VERSION "created by canmatrix"

NS_ :

BS_:

BU_: IPD

BO_ 777 RZCU_PTCANFD_100ms_FrP10: 8 Vector__XXX
 SG_ IRZCU_100ms_Group10_CRC : 7|8@0+ (1,0) [0|255] "null" IPD
 SG_ IRZCU_100ms_Group10_RC : 11|4@0+ (1,0) [0|15] "null" IPD
 SG_ IOfbdChrgRelaySts : 13|2@0+ (1,0) [0|3] "null" IPD
 SG_ IRZCU_100ms_Group10_Reserved1 : 15|2@0+ (1,0) [0|3] "null" IPD
 SG_ IOfbdChrgrNgtvSktTem : 23|8@0+ (1,-40) [-40|215] "degreeCelsius" IPD
 SG_ IOnBdChrgrSktPstvSnsrTem : 31|8@0+ (1,-40) [-40|215] "degreeCelsius" IPD
 SG_ IEleccLckCtrlResp : 34|3@0+ (1,0) [0|7] "null" IPD
 SG_ IOnbdChrgrSktEleccLckEnable : 36|2@0+ (1,0) [0|3] "null" IPD
 SG_ IOnBdChrgrSktPstvSnsrTemV : 37|1@0+ (1,0) [0|1] "null" IPD
 SG_ IOfbdChrgrNgtvSktTemV : 38|1@0+ (1,0) [0|1] "null" IPD
 SG_ IOfbdChrgrWkup : 39|1@0+ (1,0) [0|1] "null" IPD
 SG_ IRZCU_100ms_Group10_Reserved2 : 45|7@0+ (1,0) [0|127] "null" IPD
 SG_ IFlbStrgFnStsResp : 47|2@0+ (1,0) [0|3] "null" IPD
 SG_ IRZCU_100ms_Group10_Reserved3 : 48|3@0+ (1,0) [0|7] "null" IPD
 SG_ IOfbdRelayWeldFlt : 49|1@0+ (1,0) [0|1] "null" IPD
 SG_ IIMU_Signal_status : 52|3@0+ (1,0) [0|7] "null" IPD
 SG_ IVCUCtrlS2Req : 54|2@0+ (1,0) [0|3] "null" IPD
 SG_ IOfbdChrgRelayStsV : 56|1@0+ (1,0) [0|1] "null" IPD
 SG_ ICstRgtnBrkLgtReq : 57|1@0+ (1,0) [0|1] "null" IPD
 SG_ ICstRgtnBrkLgtReqV : 58|1@0+ (1,0) [0|1] "null" IPD
 SG_ IOnBdChrgrSktElecLckStaV : 59|1@0+ (1,0) [0|1] "null" IPD
 SG_ IOnBdChrgrSktElecLckSta : 61|2@0+ (1,0) [0|3] "null" IPD

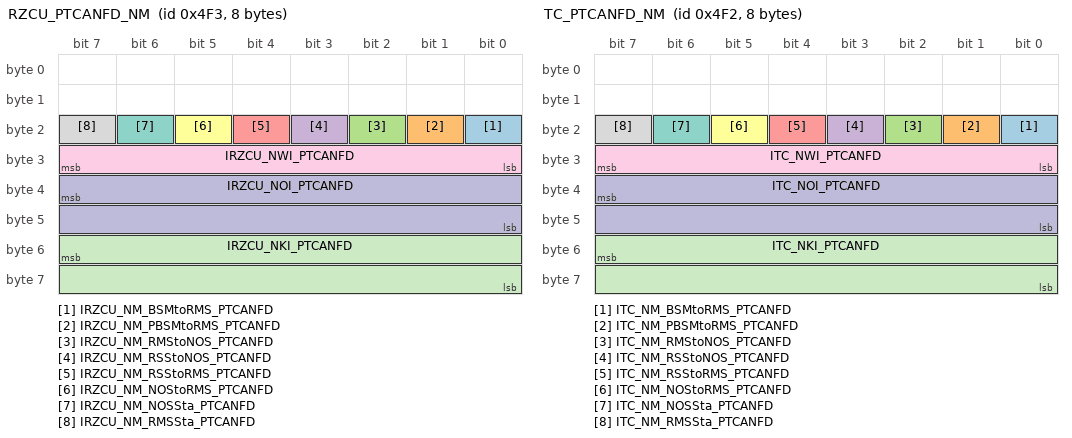
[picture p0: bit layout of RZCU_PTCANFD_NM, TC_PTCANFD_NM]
BO_ 1267 RZCU_PTCANFD_NM: 8 Vector__XXX
 SG_ IRZCU_NM_BSMtoRMS_PTCANFD : 16|1@0+ (1,0) [0|1] "null" Vector__XXX
 SG_ IRZCU_NM_PBSMtoRMS_PTCANFD : 17|1@0+ (1,0) [0|1] "null" Vector__XXX
 SG_ IRZCU_NM_RMStoNOS_PTCANFD : 18|1@0+ (1,0) [0|1] "null" Vector__XXX
 SG_ IRZCU_NM_RSStoNOS_PTCANFD : 19|1@0+ (1,0) [0|1] "null" Vector__XXX
 SG_ IRZCU_NM_RSStoRMS_PTCANFD : 20|1@0+ (1,0) [0|1] "null" Vector__XXX
 SG_ IRZCU_NM_NOStoRMS_PTCANFD : 21|1@0+ (1,0) [0|1] "null" Vector__XXX
 SG_ IRZCU_NM_NOSSta_PTCANFD : 22|1@0+ (1,0) [0|1] "null" Vector__XXX
 SG_ IRZCU_NM_RMSSta_PTCANFD : 23|1@0+ (1,0) [0|1] "null" Vector__XXX
 SG_ IRZCU_NWI_PTCANFD : 31|8@0+ (1,0) [0|255] "null" Vector__XXX
 SG_ IRZCU_NOI_PTCANFD : 39|16@0+ (1,0) [0|65535] "null" Vector__XXX
 SG_ IRZCU_NKI_PTCANFD : 55|16@0+ (1,0) [0|65535] "null" Vector__XXX

BO_ 247 RZCU_RZCUCANFD_10ms_FrP22_NoSecO: 12 Vector__XXX
 SG_ IRZCU_10ms_Group22_CRC : 7|8@0+ (1,0) [0|255] "null" IPD
 SG_ IRZCU_10ms_Group22_RC : 11|4@0+ (1,0) [0|15] "null" IPD
 SG_ IRZCU_10ms_Group22_Reserved1 : 13|2@0+ (1,0) [0|3] "null" IPD
 SG_ IEPTTrOtptShaftTotMinAvlblToqV : 14|1@0+ (1,0) [0|1] "null" IPD
 SG_ IEPTTrOtptShaftTotMaxAvlblToqV : 15|1@0+ (1,0) [0|1] "null" IPD
 SG_ IEPTTrOtptShaftTotMaxAvlblToq : 23|12@0+ (0.5,-848) [-848|1199.5] "Nm" IPD
 SG_ IEPTTrOtptShaftTotMinAvlblToq : 27|12@0+ (0.5,-848) [-848|1199.5] "Nm" IPD
 SG_ IEPTTrOtptShaftTotToq : 43|12@0+ (0.5,-848) [-848|1199.5] "Nm" IPD
 SG_ IEPTTrOtptShaftTotToqV : 44|1@0+ (1,0) [0|1] "null" IPD
 SG_ IRZCU_10ms_Group22_Reserved2 : 47|3@0+ (1,0) [0|7] "null" IPD
 SG_ IRZCU_10ms_Group22_Reserved3 : 63|8@0+ (1,0) [0|255] "null" IPD
 SG_ IRZCU_10ms_Group22_Reserved4 : 71|8@0+ (1,0) [0|255] "null" IPD
 SG_ IRZCU_10ms_Group22_Reserved5 : 79|8@0+ (1,0) [0|255] "null" IPD
 SG_ IRZCU_10ms_Group22_Reserved6 : 87|8@0+ (1,0) [0|255] "null" IPD
 SG_ IRZCU_10ms_Group22_Reserved7 : 95|8@0+ (1,0) [0|255] "null" IPD

BO_ 225 RZCU_RZCUCANFD_10ms_FrP23: 16 Vector__XXX
 SG_ IRZCU_10ms_Group23_CRC : 7|8@0+ (1,0) [0|255] "null" IPD
 SG_ IRZCU_10ms_Group23_RC : 11|4@0+ (1,0) [0|15] "null" IPD
 SG_ IRZCU_10ms_Group23_Reserved1 : 15|4@0+ (1,0) [0|15] "null" IPD
 SG_ IRZCU_10ms_Group23_Reserved3 : 18|3@0+ (1,0) [0|7] "null" IPD
 SG_ IAutodDrvngToqReqResp : 21|3@0+ (1,0) [0|7] "null" IPD
 SG_ IRZCU_10ms_Group23_Reserved2 : 23|2@0+ (1,0) [0|3] "null" IPD
 SG_ IRZCU_10ms_Group23_Reserved4 : 28|5@0+ (1,0) [0|31] "null" IPD
 SG_ IPtACCToqReqResp : 31|3@0+ (1,0) [0|7] "null" IPD
 SG_ IAIPilotSysSaBrSts : 35|4@0+ (1,0) [0|15] "null" IPD
 SG_ IAIPilotSysSaBrInh : 39|4@0+ (1,0) [0|15] "null" IPD
 SG_ IRZCU_10ms_Group23_Reserved5 : 47|8@0+ (1,0) [0|255] "null" IPD
 SG_ IRZCU_10ms_Group23_Reserved6 : 54|7@0+ (1,0) [0|127] "null" IPD
 SG_ IAccelOvrd : 55|1@0+ (1,0) [0|1] "null" IPD
 SG_ IRZCU_10ms_Group23_Reserved7 : 63|8@0+ (1,0) [0|255] "null" IPD
 SG_ IRZCU_10ms_Group23_Reserved8 : 71|8@0+ (1,0) [0|255] "null" IPD
 SG_ IRZCU_10ms_Group23_Reserved9 : 79|8@0+ (1,0) [0|255] "null" IPD
 SG_ IRZCU_10ms_Group23_Reserved10 : 87|8@0+ (1,0) [0|255] "null" IPD
 SG_ IRZCU_10ms_Group23_Reserved11 : 95|8@0+ (1,0) [0|255] "null" IPD

BO_ 1266 TC_PTCANFD_NM: 8 Vector__XXX
 SG_ ITC_NM_BSMtoRMS_PTCANFD : 16|1@0+ (1,0) [0|1] "null" Vector__XXX
 SG_ ITC_NM_PBSMtoRMS_PTCANFD : 17|1@0+ (1,0) [0|1] "null" Vector__XXX
 SG_ ITC_NM_RMStoNOS_PTCANFD : 18|1@0+ (1,0) [0|1] "null" Vector__XXX
 SG_ ITC_NM_RSStoNOS_PTCANFD : 19|1@0+ (1,0) [0|1] "null" Vector__XXX
 SG_ ITC_NM_RSStoRMS_PTCANFD : 20|1@0+ (1,0) [0|1] "null" Vector__XXX
 SG_ ITC_NM_NOStoRMS_PTCANFD : 21|1@0+ (1,0) [0|1] "null" Vector__XXX
 SG_ ITC_NM_NOSSta_PTCANFD : 22|1@0+ (1,0) [0|1] "null" Vector__XXX
 SG_ ITC_NM_RMSSta_PTCANFD : 23|1@0+ (1,0) [0|1] "null" Vector__XXX
 SG_ ITC_NWI_PTCANFD : 31|8@0+ (1,0) [0|255] "null" Vector__XXX
 SG_ ITC_NOI_PTCANFD : 39|16@0+ (1,0) [0|65535] "null" Vector__XXX
 SG_ ITC_NKI_PTCANFD : 55|16@0+ (1,0) [0|65535] "null" Vector__XXX

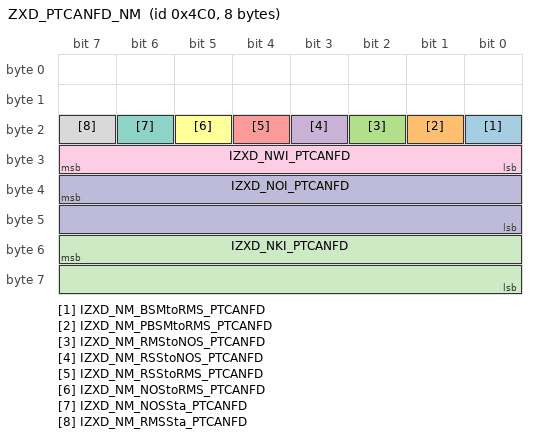
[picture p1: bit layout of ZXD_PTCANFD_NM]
BO_ 1216 ZXD_PTCANFD_NM: 8 Vector__XXX
 SG_ IZXD_NM_BSMtoRMS_PTCANFD : 16|1@0+ (1,0) [0|1] "null" Vector__XXX
 SG_ IZXD_NM_PBSMtoRMS_PTCANFD : 17|1@0+ (1,0) [0|1] "null" Vector__XXX
 SG_ IZXD_NM_RMStoNOS_PTCANFD : 18|1@0+ (1,0) [0|1] "null" Vector__XXX
 SG_ IZXD_NM_RSStoNOS_PTCANFD : 19|1@0+ (1,0) [0|1] "null" Vector__XXX
 SG_ IZXD_NM_RSStoRMS_PTCANFD : 20|1@0+ (1,0) [0|1] "null" Vector__XXX
 SG_ IZXD_NM_NOStoRMS_PTCANFD : 21|1@0+ (1,0) [0|1] "null" Vector__XXX
 SG_ IZXD_NM_NOSSta_PTCANFD : 22|1@0+ (1,0) [0|1] "null" Vector__XXX
 SG_ IZXD_NM_RMSSta_PTCANFD : 23|1@0+ (1,0) [0|1] "null" Vector__XXX
 SG_ IZXD_NWI_PTCANFD : 31|8@0+ (1,0) [0|255] "null" Vector__XXX
 SG_ IZXD_NOI_PTCANFD : 39|16@0+ (1,0) [0|65535] "null" Vector__XXX
 SG_ IZXD_NKI_PTCANFD : 55|16@0+ (1,0) [0|65535] "null" Vector__XXX

BO_ 769 ESS_PTCANFD_100ms_ConFrP19: 64 Vector__XXX
 SG_ Header_ID M : 7|24@0- (1,0) [-8388608|8388607] "" Vector__XXX
 SG_ Header_DLC : 31|8@0- (1,0) [-128|127] "" Vector__XXX
 SG_ IBMSEmsnRltdMalfA m147460 : 36|1@0+ (1,0) [0|1] "null" Vector__XXX
 SG_ IBMSOdoFctV m147460 : 37|1@0+ (1,0) [0|1] "null" Vector__XXX
 SG_ IBMSCdstCtr m147460 : 39|2@0+ (1,0) [0|3] "null" Vector__XXX
 SG_ IBMSOdoFct m147460 : 47|8@0+ (0.5,0) [0|127.5] "Percent" Vector__XXX
 SG_ IBMSStdAvlblEnrg m147460 : 55|12@0+ (0.05,0) [0.00|204.75] "kwh" Vector__XXX
 SG_ IBMSChrgTrgtStdAvlblEnrg m147460 : 59|12@0+ (0.05,0) [0.00|204.75] "kwh" Vector__XXX
 SG_ IBMSDisTrgtStdAvlblEnrg m147460 : 79|12@0+ (0.05,0) [0.00|204.75] "kwh" Vector__XXX
 SG_ IBMSStdAvlblEnrgV m147460 : 81|1@0+ (1,0) [0|1] "null" Vector__XXX
 SG_ IBMSChrgTrgtStdAvlblEnrgV m147460 : 82|1@0+ (1,0) [0|1] "null" Vector__XXX
 SG_ IBMSDisTrgtStdAvlblEnrgV m147460 : 83|1@0+ (1,0) [0|1] "null" Vector__XXX
 SG_ IESS_100ms_Group25_CRC m65796 : 39|8@0+ (1,0) [0|255] "null" Vector__XXX
 SG_ IESS_100ms_Group25_RC m65796 : 43|4@0+ (1,0) [0|15] "null" Vector__XXX
 SG_ IESS_100ms_Group25_Reserved1 m65796 : 47|4@0+ (1,0) [0|15] "null" Vector__XXX
 SG_ IBMSPosPtIsltnRstc m65796 : 53|14@0+ (0.5,0) [0|8191.5] "kOhm" Vector__XXX
 SG_ IBMSPosPtIsltnRstcV m65796 : 54|1@0+ (1,0) [0|1] "null" Vector__XXX
 SG_ IBMSNegPtIsltnRstcV m65796 : 55|1@0+ (1,0) [0|1] "null" Vector__XXX
 SG_ IBMSNegPtIsltnRstc m65796 : 69|14@0+ (0.5,0) [0|8191.5] "kOhm" Vector__XXX
 SG_ IESS_100ms_Group25_Reserved2 m65796 : 71|2@0+ (1,0) [0|3] "null" Vector__XXX
 SG_ IESS_100ms_Group25_Reserved3 m65796 : 87|8@0+ (1,0) [0|255] "null" Vector__XXX
 SG_ IESS_100ms_Group25_Reserved4 m65796 : 95|8@0+ (1,0) [0|255] "null" Vector__XXX
 SG_ IBMSStaOfHealthResi m65794 : 39|8@0+ (0.5,0) [0|127.5] "Percent" Vector__XXX
 SG_ IBMSStaOfHealthCapct m65794 : 47|8@0+ (0.5,0) [0|127.5] "Percent" Vector__XXX
 SG_ IBMSOnbdChrgSpRsn m65794 : 55|8@0+ (1,0) [0|255] "null" Vector__XXX
 SG_ IBMSPackSOH m65794 : 57|10@0+ (0.1,0) [0|102.3] "Percent" Vector__XXX
 SG_ IBMSFltLamp m65794 : 63|4@0+ (1,0) [0|15] "null" Vector__XXX
 SG_ IHVBatShutOff m65794 : 79|1@0+ (1,0) [0|1] "null" Vector__XXX
 SG_ IHVBatSOCHiResV m74579 : 48|1@0+ (1,0) [0|1] "null" Vector__XXX
 SG_ IHVBatSOCMin m74579 : 63|8@0+ (0.392157,0) [0.000000|100.000035] "null" Vector__XXX
 SG_ IHVBatSOCHiRes m74579 : 71|16@0+ (0.00152593,0) [0E-008|100.00182255] "null" Vector__XXX
 SG_ IHVBatSOCTrgtHiRes m74579 : 87|16@0+ (0.001526,0) [0.000000|100.006410] "null" Vector__XXX
 SG_ IESS_100ms_Group58_CRC m74584 : 39|8@0+ (1,0) [0|255] "null" IPD
 SG_ IESS_100ms_Group58_RC m74584 : 43|4@0+ (1,0) [0|15] "null" IPD
 SG_ IBMSOfbdChrgrSktVolV m74584 : 44|1@0+ (1,0) [0|1] "null" IPD
 SG_ IESS_100ms_Group58_Reserved1 m74584 : 45|1@0+ (1,0) [0|1] "null" IPD
 SG_ IBMSOffBdChrgrPlugOn m74584 : 47|2@0+ (1,0) [0|3] "null" IPD
 SG_ IESS_100ms_Group58_Reserved2 m74584 : 55|8@0+ (1,0) [0|255] "null" IPD
 SG_ IESS_100ms_Group58_Reserved3 m74584 : 63|8@0+ (1,0) [0|255] "null" IPD
 SG_ IBMSOfbdChrgrSktVol m74584 : 71|12@0+ (0.25,0) [0.00|1023.75] "null" IPD
 SG_ IESS_100ms_Group58_Reserved4 m74584 : 73|2@0+ (1,0) [0|3] "null" IPD
 SG_ IBMSOffBdChrgrPlugOnV m74584 : 74|1@0+ (1,0) [0|1] "null" IPD
 SG_ IBMSOfbdChrgrWkup m74584 : 75|1@0+ (1,0) [0|1] "null" IPD
 SG_ IESS_100ms_Group58_Reserved5 m74584 : 87|8@0+ (1,0) [0|255] "null" IPD
 SG_ IESS_100ms_Group58_Reserved6 m74584 : 95|8@0+ (1,0) [0|255] "null" IPD

BO_ 548 ESS_PTCANFD_100ms_ConFrP29: 64 Vector__XXX
 SG_ Header_ID M : 7|24@0- (1,0) [-8388608|8388607] "" Vector__XXX
 SG_ Header_DLC : 31|8@0- (1,0) [-128|127] "" Vector__XXX
 SG_ IVehElecRngDspCmd m147459 : 33|2@0+ (1,0) [0|3] "null" Vector__XXX
 SG_ IElecDrvRngPerKwhV m147459 : 34|1@0+ (1,0) [0|1] "null" Vector__XXX
 SG_ IVehElecRngV m147459 : 35|1@0+ (1,0) [0|1] "null" Vector__XXX
 SG_ IElecDrvRngPerKwh m147459 : 39|4@0+ (1,0) [0|15] "mph" Vector__XXX
 SG_ IBMSOfbdChrgrMaxOtptVol m147459 : 47|12@0+ (0.25,0) [0.00|1023.75] "V" Vector__XXX
 SG_ IBMSOfbdChrgrOtptVol m147459 : 50|12@0+ (0.25,0) [0.00|1023.75] "V" Vector__XXX
 SG_ IBMSOfbdChrgrMaxOtptVolV m147459 : 51|1@0+ (1,0) [0|1] "null" Vector__XXX
 SG_ IBMSOfbdChrgrOtptCrnt m147459 : 69|11@0+ (0.5,0) [0|1023.5] "A" Vector__XXX
 SG_ IBMSOfbdChrgrOtptVolV m147459 : 70|1@0+ (1,0) [0|1] "null" Vector__XXX
 SG_ IBMSOfbdChrgngMd m147459 : 73|2@0+ (1,0) [0|3] "null" Vector__XXX
 SG_ IBMSOfbdChrgrOtptCrnV m147459 : 74|1@0+ (1,0) [0|1] "null" Vector__XXX
 SG_ IVehElecRng m147459 : 82|11@0+ (1,0) [0|2047] "km" Vector__XXX
 SG_ IBMSEnbPTC m147459 : 84|1@0+ (1,0) [0|1] "null" Vector__XXX
 SG_ IHVOffMoSts m147459 : 87|3@0+ (1,0) [0|7] "null" Vector__XXX
 SG_ IBMSPTCHeatReqDspCmd m147458 : 33|2@0+ (1,0) [0|3] "null" Vector__XXX
 SG_ IChrgngRmnngTimeV m147458 : 34|1@0+ (1,0) [0|1] "null" Vector__XXX
 SG_ IBMSChrgrPlugCnctnIO m147458 : 35|1@0+ (1,0) [0|1] "null" IPD
 SG_ IBMSCumuDschrgEnrgV m147458 : 38|1@0+ (1,0) [0|1] "null" Vector__XXX
 SG_ IBMSCumuDschrgEnrg m147458 : 47|24@0+ (0.1,0) [0|1677721.5] "kWh" Vector__XXX
 SG_ IChrgngRmnngTime m147458 : 65|10@0+ (1,0) [0|1023] "min" Vector__XXX
 SG_ IBMSEleccLckCtrlDspCmd m147458 : 67|2@0+ (1,0) [0|3] "null" Vector__XXX
 SG_ IBMSPackSOCCorr m147458 : 71|3@0+ (1,0) [0|7] "null" Vector__XXX
 SG_ IBMSPTCHeatResp m147458 : 82|3@0+ (1,0) [0|7] "null" Vector__XXX
 SG_ IBMSNotfnPushReq m147458 : 87|5@0+ (1,0) [0|31] "null" Vector__XXX
 SG_ IBMSBattNoFuChargReq m147458 : 95|8@0+ (1,0) [0|255] "null" Vector__XXX
 SG_ IBMSPackSOCE m333904 : 47|10@0+ (0.1,0) [0|102.3] "%" Vector__XXX
 SG_ IBMSPackSOC m333904 : 49|10@0+ (0.1,0) [0|102.3] "Percent" Vector__XXX
 SG_ IBMSPackSOCV m333904 : 50|1@0+ (1,0) [0|1] "null" Vector__XXX
 SG_ IBMSPackSOCActual m333904 : 71|8@0+ (0.5,0) [0|127.5] "Percent" Vector__XXX
 SG_ IBMSPackSOCDsp m333904 : 73|10@0+ (0.1,0) [0|102.3] "Percent" IPD
 SG_ IBMSPackSOCDspV m333904 : 74|1@0+ (1,0) [0|1] "null" IPD
 SG_ IBMSPackSOCEV m333904 : 76|1@0+ (1,0) [0|1] "null" Vector__XXX
 SG_ IBMSSysCoolResp m333904 : 79|3@0+ (1,0) [0|7] "null" Vector__XXX
 SG_ IBMSOnbdChrgngCmdReq m333905 : 47|4@0+ (1,0) [0|15] "null" Vector__XXX
 SG_ IBMSCtrlS2Req m333905 : 49|2@0+ (1,0) [0|3] "null" Vector__XXX
 SG_ IBMSDsChrgSpRsn m333905 : 54|5@0+ (1,0) [0|31] "null" Vector__XXX
 SG_ IBMSOnbdChrgrAltCrntLmt m333905 : 63|8@0+ (0.5,0) [0|127.5] "A" Vector__XXX
 SG_ IBMSOnbdChrgrOtptCrntReq m333905 : 67|12@0+ (0.1,-204.8) [-204.8|204.7] "A" Vector__XXX
 SG_ IBMSOnbdChrgngMd m333905 : 70|3@0+ (1,0) [0|7] "null" Vector__XXX
 SG_ IBMSOnbdChrgrOtptVolReqV m333905 : 71|1@0+ (1,0) [0|1] "null" Vector__XXX
 SG_ IBMSOnbdChrgrOtptVolReq m333905 : 87|16@0+ (0.02,0) [0.00|1310.70] "V" Vector__XXX
 SG_ IVehCltcElecCsumpV m147457 : 34|1@0+ (1,0) [0|1] "null" Vector__XXX
 SG_ IBMSAvlblEnrgV m147457 : 35|1@0+ (1,0) [0|1] "null" Vector__XXX
 SG_ ICrntAvgElecCsumpV m147457 : 39|1@0+ (1,0) [0|1] "null" Vector__XXX
 SG_ IVehCltcElecCsump m147457 : 47|10@0+ (0.1,-20) [-20|82.3] "null" Vector__XXX
 SG_ ICrntAvgElecCsump m147457 : 53|10@0+ (0.1,-20) [-20|82.3] "kwh/100km" Vector__XXX
 SG_ IElecCsumpPerKm m147457 : 59|10@0+ (0.1,-20) [-20|82.3] "kwh/100km" Vector__XXX
 SG_ IHVBatElecEnrgAvgRate m147457 : 65|10@0+ (0.1,-20) [-20|82.3] "kwh/100km" Vector__XXX
 SG_ IHVBatElecEnrgAvgRateV m147457 : 85|1@0+ (1,0) [0|1] "null" Vector__XXX
 SG_ IElecEnrgAvgRstPerfd m147457 : 86|1@0+ (1,0) [0|1] "null" Vector__XXX
 SG_ IElecCsumpPerKmV m147457 : 87|1@0+ (1,0) [0|1] "null" Vector__XXX
 SG_ IBMSAvlblEnrg m147457 : 95|8@0+ (0.4,0) [0|102] "kWh" Vector__XXX

BO_ 404 RZCU_PTCANFD_20ms_ConFrP06: 64 Vector__XXX
 SG_ Header_ID M : 7|24@0- (1,0) [-8388608|8388607] "" Vector__XXX
 SG_ Header_DLC : 31|8@0- (1,0) [-128|127] "" Vector__XXX
 SG_ IRZCU_20ms_Group06_CRC m9830661 : 39|8@0+ (1,0) [0|255] "null" IPD
 SG_ IRZCU_20ms_Group06_RC m9830661 : 43|4@0+ (1,0) [0|15] "null" IPD
 SG_ ITrEstdGearV m9830661 : 44|1@0+ (1,0) [0|1] "null" IPD
 SG_ IEPTRdyV m9830661 : 45|1@0+ (1,0) [0|1] "null" IPD
 SG_ IEPTRdy m9830661 : 46|1@0+ (1,0) [0|1] "null" IPD
 SG_ ITrShftLvrPosV m9830661 : 47|1@0+ (1,0) [0|1] "null" IPD
 SG_ ITrEstdGear m9830661 : 51|4@0+ (1,0) [0|15] "null" IPD
 SG_ ITrShftLvrPos m9830661 : 55|4@0+ (1,0) [0|15] "null" IPD
 SG_ IRZCU_20ms_Group06_Reserved1 m9830661 : 60|5@0+ (1,0) [0|31] "null" IPD
 SG_ ITrEngdStaV m9830661 : 61|1@0+ (1,0) [0|1] "null" IPD
 SG_ ITrEngdSta m9830661 : 63|2@0+ (1,0) [0|3] "null" IPD
 SG_ IRZCU_20ms_Group06_Reserved2 m9830661 : 71|8@0+ (1,0) [0|255] "null" IPD
 SG_ IRZCU_20ms_Group06_Reserved3 m9830661 : 79|8@0+ (1,0) [0|255] "null" IPD
 SG_ IRZCU_20ms_Group06_Reserved4 m9830661 : 87|8@0+ (1,0) [0|255] "null" IPD
 SG_ IRZCU_20ms_Group06_Reserved5 m9830661 : 95|8@0+ (1,0) [0|255] "null" IPD
 SG_ IEPTRunCrkTrmlSts m9830663 : 45|2@0+ (1,0) [0|3] "null" Vector__XXX
 SG_ IEPTSimEnSpd m9830663 : 55|16@0+ (0.25,0) [0.00|16383.75] "rpm" Vector__XXX
 SG_ IVMCLvlCtrlAdjActn m9830663 : 68|4@0+ (1,0) [0|15] "null" Vector__XXX
 SG_ ISecyAxleSts m9830663 : 71|3@0+ (1,0) [0|7] "null" Vector__XXX

BO_ 180 RZCU_SFCANFD_10ms_ConFrP08: 64 Vector__XXX
 SG_ Header_ID M : 7|24@0- (1,0) [-8388608|8388607] "" Vector__XXX
 SG_ Header_DLC : 31|8@0- (1,0) [-128|127] "" Vector__XXX
 SG_ IRZCU_10ms_Group01_CRC m614402 : 39|8@0+ (1,0) [0|255] "null" IPD
 SG_ IRZCU_10ms_Group01_RC m614402 : 43|4@0+ (1,0) [0|15] "null" IPD
 SG_ IElecMotEmgcShutDwn m614402 : 44|1@0+ (1,0) [0|1] "null" IPD
 SG_ IEPTHVEmgcPwrOffReq m614402 : 45|1@0+ (1,0) [0|1] "null" IPD
 SG_ IEPTMainRelayDrvReq m614402 : 47|2@0+ (1,0) [0|3] "null" IPD
 SG_ IEPTStCmdOn m614402 : 48|1@0+ (1,0) [0|1] "null" IPD
 SG_ IEPTAccelActuPosV m614402 : 49|1@0+ (1,0) [0|1] "null" IPD
 SG_ IAutoChrgngMngmnt m614402 : 51|2@0+ (1,0) [0|3] "null" IPD
 SG_ IEPTBrkPdlDscrtInptStsV m614402 : 52|1@0+ (1,0) [0|1] "null" IPD
 SG_ IEPTBrkPdlDscrtInptSts m614402 : 53|1@0+ (1,0) [0|1] "null" IPD
 SG_ IRVSEPTRdy m614402 : 54|1@0+ (1,0) [0|1] "null" IPD
 SG_ IEPTCrkAbotd m614402 : 55|1@0+ (1,0) [0|1] "null" IPD
 SG_ IRZCU_10ms_Group01_Reserved1 m614402 : 60|5@0+ (1,0) [0|31] "null" IPD
 SG_ IEPTHVDCDCMdReq m614402 : 63|3@0+ (1,0) [0|7] "null" IPD
 SG_ IEPTAccelActuPos m614402 : 71|8@0+ (0.392157,0) [0.000000|100.000035] "Percent" IPD
 SG_ IEPTAccelEfctvPos m614402 : 79|8@0+ (0.392157,0) [0.000000|100.000035] "Percent" IPD
 SG_ IRZCU_10ms_Group01_Reserved2 m614402 : 87|8@0+ (1,0) [0|255] "null" IPD
 SG_ IRZCU_10ms_Group01_Reserved3 m614402 : 95|8@0+ (1,0) [0|255] "null" IPD
 SG_ IRZCU_10ms_Group02_CRC m614416 : 39|8@0+ (1,0) [0|255] "null" IPD
 SG_ IRZCU_10ms_Group02_RC m614416 : 43|4@0+ (1,0) [0|15] "null" IPD
 SG_ IEPTTrInptShaftSpdV_R m614416 : 44|1@0+ (1,0) [0|1] "null" IPD
 SG_ IRZCU_10ms_Group02_Reserved1 m614416 : 45|1@0+ (1,0) [0|1] "null" IPD
 SG_ IEPTTrInptShaftSpdV m614416 : 46|1@0+ (1,0) [0|1] "null" IPD
 SG_ IEPTSecyAxleInptShaftSpdV m614416 : 47|1@0+ (1,0) [0|1] "null" IPD
 SG_ IEPTSecyAxleInptShaftSpd m614416 : 55|16@0+ (1,-32767) [-32767|32768] "rpm" IPD
 SG_ IEPTTrInptShaftSpd m614416 : 71|16@0+ (1,-32767) [-32767|32768] "rpm" IPD
 SG_ IEPTTrInptShaftSpd_R m614416 : 87|16@0+ (1,-32767) [-32767|32768] "rpm" IPD

BA_DEF_ BO_ "FrameTriggeringName" STRING;
BA_DEF_ BO_ "GenMsgCycleTime" INT 0 65535;
BA_DEF_ BO_ "GenMsgSendType" ENUM  "cyclicX","spontanX","cyclicIfActiveX","spontanWithDelay","cyclicAndSpontanX","cyclicAndSpontanWithDelay","spontanWithRepitition","cyclicIfActiveAndSpontanWD","cyclicIfActiveFast","cyclicWithRepeatOnDemand","none";
BA_DEF_ BO_ "GenMsgStartValue" STRING;
BA_DEF_ BO_ "PduName" STRING;
BA_DEF_ BO_ "SystemMessageLongSymbol" STRING;
BA_DEF_ BO_ "VFrameFormat" ENUM  "StandardCAN","ExtendedCAN","reserved","reserved","reserved","reserved","reserved","reserved","reserved","reserved","reserved","reserved","reserved","reserved","StandardCAN_FD","ExtendedCAN_FD";
BA_DEF_ SG_ "CompuMethodName" STRING;
BA_DEF_ SG_ "GenSigStartValue" FLOAT 0 100000000000;
BA_DEF_ SG_ "ISignalName" STRING;
BA_DEF_ SG_ "LongName" STRING;
BA_DEF_ SG_ "SysSignalName" STRING;
BA_ "FrameTriggeringName" BO_ 777 "RZCU_PTCANFD_100ms_FrP10";
BA_ "GenMsgCycleTime" BO_ 777 100;
BA_ "GenMsgSendType" BO_ 777 0;
BA_ "GenMsgStartValue" BO_ 777 "00c0fe00603f81c9";
BA_ "PduName" BO_ 777 "RZCU_100ms_PDU10";
BA_ "VFrameFormat" BO_ 777 14;
BA_ "FrameTriggeringName" BO_ 1267 "RZCU_PTCANFD_NM";
BA_ "GenMsgSendType" BO_ 1267 1;
BA_ "GenMsgStartValue" BO_ 1267 "0000000000000000";
BA_ "PduName" BO_ 1267 "NmPDU_PTCANFD_RZCU";
BA_ "VFrameFormat" BO_ 1267 14;
BA_ "FrameTriggeringName" BO_ 247 "RZCU_RZCUCANFD_10ms_FrP22_NoSecOC";
BA_ "GenMsgCycleTime" BO_ 247 10;
BA_ "GenMsgSendType" BO_ 247 0;
BA_ "GenMsgStartValue" BO_ 247 "00306a0000f000ffffffffff";
BA_ "PduName" BO_ 247 "RZCU_10ms_PDU22";
BA_ "SystemMessageLongSymbol" BO_ 247 "RZCU_RZCUCANFD_10ms_FrP22_NoSecOC";
BA_ "VFrameFormat" BO_ 247 14;
BA_ "FrameTriggeringName" BO_ 225 "RZCU_RZCUCANFD_10ms_FrP23";
BA_ "GenMsgCycleTime" BO_ 225 10;
BA_ "GenMsgSendType" BO_ 225 0;
BA_ "GenMsgStartValue" BO_ 225 "00f0c71f00ff7fffffffffff00000000";
BA_ "PduName" BO_ 225 "RZCU_10ms_PDU23";
BA_ "VFrameFormat" BO_ 225 14;
BA_ "FrameTriggeringName" BO_ 1266 "TC_PTCANFD_NM";
BA_ "GenMsgSendType" BO_ 1266 1;
BA_ "GenMsgStartValue" BO_ 1266 "0000000000000000";
BA_ "PduName" BO_ 1266 "NmPDU_PTCANFD_TC";
BA_ "VFrameFormat" BO_ 1266 14;
BA_ "FrameTriggeringName" BO_ 1216 "ZXD_PTCANFD_NM";
BA_ "GenMsgSendType" BO_ 1216 1;
BA_ "GenMsgStartValue" BO_ 1216 "0000000000000000";
BA_ "PduName" BO_ 1216 "NmPDU_PTCANFD_ZXD";
BA_ "VFrameFormat" BO_ 1216 14;
BA_ "FrameTriggeringName" BO_ 769 "ESS_PTCANFD_100ms_ConFrP19";
BA_ "GenMsgCycleTime" BO_ 769 100;
BA_ "GenMsgSendType" BO_ 769 1;
BA_ "PduName" BO_ 769 "BMS_ZONE_PTCANFD_100ms_Container02";
BA_ "VFrameFormat" BO_ 769 14;
BA_ "FrameTriggeringName" BO_ 548 "ESS_PTCANFD_100ms_ConFrP29";
BA_ "GenMsgCycleTime" BO_ 548 100;
BA_ "GenMsgSendType" BO_ 548 1;
BA_ "PduName" BO_ 548 "BMS_ZONE_PTCANFD_100ms_Container01";
BA_ "VFrameFormat" BO_ 548 14;
BA_ "FrameTriggeringName" BO_ 404 "RZCU_PTCANFD_20ms_ConFrP06";
BA_ "GenMsgCycleTime" BO_ 404 20;
BA_ "GenMsgSendType" BO_ 404 1;
BA_ "PduName" BO_ 404 "IMCU_PTCANFD_20ms_Container01";
BA_ "VFrameFormat" BO_ 404 14;
BA_ "FrameTriggeringName" BO_ 180 "RZCU_SFCANFD_10ms_ConFrP08";
BA_ "GenMsgCycleTime" BO_ 180 10;
BA_ "GenMsgSendType" BO_ 180 1;
BA_ "PduName" BO_ 180 "IMCU_SFCANFD_10ms_Container08";
BA_ "VFrameFormat" BO_ 180 14;
BA_ "CompuMethodName" SG_ 777 IRZCU_100ms_Group10_CRC "RZCU_100ms_Group10_CRC";
BA_ "ISignalName" SG_ 777 IRZCU_100ms_Group10_CRC "IRZCU_100ms_Group10_CRC";
BA_ "SysSignalName" SG_ 777 IRZCU_100ms_Group10_CRC "RZCU_100ms_Group10_CRC";
BA_ "CompuMethodName" SG_ 777 IRZCU_100ms_Group10_RC "RZCU_100ms_Group10_RC";
BA_ "ISignalName" SG_ 777 IRZCU_100ms_Group10_RC "IRZCU_100ms_Group10_RC";
BA_ "SysSignalName" SG_ 777 IRZCU_100ms_Group10_RC "RZCU_100ms_Group10_RC";
BA_ "CompuMethodName" SG_ 777 IOfbdChrgRelaySts "OfbdChrgRelaySts";
BA_ "ISignalName" SG_ 777 IOfbdChrgRelaySts "IOfbdChrgRelaySts";
BA_ "LongName" SG_ 777 IOfbdChrgRelaySts "Offboard Charge Relay Status";
BA_ "SysSignalName" SG_ 777 IOfbdChrgRelaySts "OfbdChrgRelaySts";
BA_ "CompuMethodName" SG_ 777 IRZCU_100ms_Group10_Reserved1 "RZCU_100ms_Group10_Reserved1";
BA_ "GenSigStartValue" SG_ 777 IRZCU_100ms_Group10_Reserved1 3;
BA_ "ISignalName" SG_ 777 IRZCU_100ms_Group10_Reserved1 "IRZCU_100ms_Group10_Reserved1";
BA_ "SysSignalName" SG_ 777 IRZCU_100ms_Group10_Reserved1 "RZCU_100ms_Group10_Reserved1";
BA_ "CompuMethodName" SG_ 777 IOfbdChrgrNgtvSktTem "OfbdChrgrNgtvSktTem";
BA_ "GenSigStartValue" SG_ 777 IOfbdChrgrNgtvSktTem 254;
BA_ "ISignalName" SG_ 777 IOfbdChrgrNgtvSktTem "IOfbdChrgrNgtvSktTem";
BA_ "LongName" SG_ 777 IOfbdChrgrNgtvSktTem "Offboard_Charger_Negative_Socket_Temperature";
BA_ "SysSignalName" SG_ 777 IOfbdChrgrNgtvSktTem "OfbdChrgrNgtvSktTem";
BA_ "CompuMethodName" SG_ 777 IOnBdChrgrSktPstvSnsrTem "OnBdChrgrSktPstvSnsrTem";
BA_ "ISignalName" SG_ 777 IOnBdChrgrSktPstvSnsrTem "IOnBdChrgrSktPstvSnsrTem";
BA_ "LongName" SG_ 777 IOnBdChrgrSktPstvSnsrTem "On_Board_Charger_Socket_Positive_Sensor_Temperature";
BA_ "SysSignalName" SG_ 777 IOnBdChrgrSktPstvSnsrTem "OnBdChrgrSktPstvSnsrTem";
BA_ "CompuMethodName" SG_ 777 IEleccLckCtrlResp "EleccLckCtrlResp";
BA_ "ISignalName" SG_ 777 IEleccLckCtrlResp "IEleccLckCtrlResp";
BA_ "LongName" SG_ 777 IEleccLckCtrlResp "Combined Charging Unit Electronic Lock Control Response";
BA_ "SysSignalName" SG_ 777 IEleccLckCtrlResp "EleccLckCtrlResp";
BA_ "CompuMethodName" SG_ 777 IOnbdChrgrSktEleccLckEnable "OnbdChrgrSktEleccLckEnable";
BA_ "ISignalName" SG_ 777 IOnbdChrgrSktEleccLckEnable "IOnbdChrgrSktEleccLckEnable";
BA_ "LongName" SG_ 777 IOnbdChrgrSktEleccLckEnable "Combined Charging Unit On oboard Charger Socket Electric Lock Enable";
BA_ "SysSignalName" SG_ 777 IOnbdChrgrSktEleccLckEnable "OnbdChrgrSktEleccLckEnable";
BA_ "CompuMethodName" SG_ 777 IOnBdChrgrSktPstvSnsrTemV "OnBdChrgrSktPstvSnsrTemV";
BA_ "GenSigStartValue" SG_ 777 IOnBdChrgrSktPstvSnsrTemV 1;
BA_ "ISignalName" SG_ 777 IOnBdChrgrSktPstvSnsrTemV "IOnBdChrgrSktPstvSnsrTemV";
BA_ "LongName" SG_ 777 IOnBdChrgrSktPstvSnsrTemV "On_Board_Charger_Socket_Positive_Sensor_Temperature_Validity";
BA_ "SysSignalName" SG_ 777 IOnBdChrgrSktPstvSnsrTemV "OnBdChrgrSktPstvSnsrTemV";
BA_ "CompuMethodName" SG_ 777 IOfbdChrgrNgtvSktTemV "OfbdChrgrNgtvSktTemV";
BA_ "GenSigStartValue" SG_ 777 IOfbdChrgrNgtvSktTemV 1;
BA_ "ISignalName" SG_ 777 IOfbdChrgrNgtvSktTemV "IOfbdChrgrNgtvSktTemV";
BA_ "LongName" SG_ 777 IOfbdChrgrNgtvSktTemV "Offboard_Charger_Negative_Socket_Temperature_Validity";
BA_ "SysSignalName" SG_ 777 IOfbdChrgrNgtvSktTemV "OfbdChrgrNgtvSktTemV";
BA_ "CompuMethodName" SG_ 777 IOfbdChrgrWkup "OfbdChrgrWkup";
BA_ "ISignalName" SG_ 777 IOfbdChrgrWkup "IOfbdChrgrWkup";
BA_ "LongName" SG_ 777 IOfbdChrgrWkup "Combined Charging Unit Offboard Charger Wakeup";
BA_ "SysSignalName" SG_ 777 IOfbdChrgrWkup "OfbdChrgrWkup";
BA_ "CompuMethodName" SG_ 777 IRZCU_100ms_Group10_Reserved2 "RZCU_100ms_Group10_Reserved2";
BA_ "GenSigStartValue" SG_ 777 IRZCU_100ms_Group10_Reserved2 127;
BA_ "ISignalName" SG_ 777 IRZCU_100ms_Group10_Reserved2 "IRZCU_100ms_Group10_Reserved2";
BA_ "SysSignalName" SG_ 777 IRZCU_100ms_Group10_Reserved2 "RZCU_100ms_Group10_Reserved2";
BA_ "CompuMethodName" SG_ 777 IFlbStrgFnStsResp "FlbStrgFnStsResp";
BA_ "ISignalName" SG_ 777 IFlbStrgFnStsResp "IFlbStrgFnStsResp";
BA_ "LongName" SG_ 777 IFlbStrgFnStsResp "Flexible Steering Function Status Response";
BA_ "SysSignalName" SG_ 777 IFlbStrgFnStsResp "FlbStrgFnStsResp";
BA_ "CompuMethodName" SG_ 777 IRZCU_100ms_Group10_Reserved3 "RZCU_100ms_Group10_Reserved3";
BA_ "GenSigStartValue" SG_ 777 IRZCU_100ms_Group10_Reserved3 7;
BA_ "ISignalName" SG_ 777 IRZCU_100ms_Group10_Reserved3 "IRZCU_100ms_Group10_Reserved3";
BA_ "SysSignalName" SG_ 777 IRZCU_100ms_Group10_Reserved3 "RZCU_100ms_Group10_Reserved3";
BA_ "CompuMethodName" SG_ 777 IOfbdRelayWeldFlt "OfbdRelayWeldFlt";
BA_ "ISignalName" SG_ 777 IOfbdRelayWeldFlt "IOfbdRelayWeldFlt";
BA_ "LongName" SG_ 777 IOfbdRelayWeldFlt "Offboard Relay Weld Fault";
BA_ "SysSignalName" SG_ 777 IOfbdRelayWeldFlt "OfbdRelayWeldFlt";
BA_ "CompuMethodName" SG_ 777 IIMU_Signal_status "IMU_Signal_status";
BA_ "ISignalName" SG_ 777 IIMU_Signal_status "IIMU_Signal_status";
BA_ "LongName" SG_ 777 IIMU_Signal_status "IMU Signal status";
BA_ "SysSignalName" SG_ 777 IIMU_Signal_status "IMU_Signal_status";
BA_ "CompuMethodName" SG_ 777 IVCUCtrlS2Req "VCUCtrlS2Req";
BA_ "ISignalName" SG_ 777 IVCUCtrlS2Req "IVCUCtrlS2Req";
BA_ "LongName" SG_ 777 IVCUCtrlS2Req "Vehicle Control Unit Control S2 Request";
BA_ "SysSignalName" SG_ 777 IVCUCtrlS2Req "VCUCtrlS2Req";
BA_ "CompuMethodName" SG_ 777 IOfbdChrgRelayStsV "OfbdChrgRelayStsV";
BA_ "GenSigStartValue" SG_ 777 IOfbdChrgRelayStsV 1;
BA_ "ISignalName" SG_ 777 IOfbdChrgRelayStsV "IOfbdChrgRelayStsV";
BA_ "LongName" SG_ 777 IOfbdChrgRelayStsV "Offboard Charge Relay Status Validity";
BA_ "SysSignalName" SG_ 777 IOfbdChrgRelayStsV "OfbdChrgRelayStsV";
BA_ "CompuMethodName" SG_ 777 ICstRgtnBrkLgtReq "CstRgtnBrkLgtReq";
BA_ "ISignalName" SG_ 777 ICstRgtnBrkLgtReq "ICstRgtnBrkLgtReq";
BA_ "LongName" SG_ 777 ICstRgtnBrkLgtReq "Coast_Regenation_Brake_Light_Request";
BA_ "SysSignalName" SG_ 777 ICstRgtnBrkLgtReq "CstRgtnBrkLgtReq";
BA_ "CompuMethodName" SG_ 777 ICstRgtnBrkLgtReqV "CstRgtnBrkLgtReqV";
BA_ "ISignalName" SG_ 777 ICstRgtnBrkLgtReqV "ICstRgtnBrkLgtReqV";
BA_ "LongName" SG_ 777 ICstRgtnBrkLgtReqV "Coast_Regenation_Brake_Light_Request_Valid";
BA_ "SysSignalName" SG_ 777 ICstRgtnBrkLgtReqV "CstRgtnBrkLgtReqV";
BA_ "CompuMethodName" SG_ 777 IOnBdChrgrSktElecLckStaV "OnBdChrgrSktElecLckStaV";
BA_ "GenSigStartValue" SG_ 777 IOnBdChrgrSktElecLckStaV 1;
BA_ "ISignalName" SG_ 777 IOnBdChrgrSktElecLckStaV "IOnBdChrgrSktElecLckStaV";
BA_ "LongName" SG_ 777 IOnBdChrgrSktElecLckStaV "Combined Charging Unit On Board Charger Socket Electronic Lock State Validity";
BA_ "SysSignalName" SG_ 777 IOnBdChrgrSktElecLckStaV "OnBdChrgrSktElecLckStaV";
BA_ "CompuMethodName" SG_ 777 IOnBdChrgrSktElecLckSta "OnBdChrgrSktElecLckSta";
BA_ "ISignalName" SG_ 777 IOnBdChrgrSktElecLckSta "IOnBdChrgrSktElecLckSta";
BA_ "LongName" SG_ 777 IOnBdChrgrSktElecLckSta "Combined Charging Unit On Board Charger Socket Electric Lock Status";
BA_ "SysSignalName" SG_ 777 IOnBdChrgrSktElecLckSta "OnBdChrgrSktElecLckSta";
BA_ "CompuMethodName" SG_ 1267 IRZCU_NM_BSMtoRMS_PTCANFD "RZCU_NM_BSMtoRMS_PTCANFD";
BA_ "ISignalName" SG_ 1267 IRZCU_NM_BSMtoRMS_PTCANFD "IRZCU_NM_BSMtoRMS_PTCANFD";
BA_ "LongName" SG_ 1267 IRZCU_NM_BSMtoRMS_PTCANFD "RZCU NM BSMtoRMS PTCANFD";
BA_ "SysSignalName" SG_ 1267 IRZCU_NM_BSMtoRMS_PTCANFD "RZCU_NM_BSMtoRMS_PTCANFD";
BA_ "CompuMethodName" SG_ 1267 IRZCU_NM_PBSMtoRMS_PTCANFD "RZCU_NM_PBSMtoRMS_PTCANFD";
BA_ "ISignalName" SG_ 1267 IRZCU_NM_PBSMtoRMS_PTCANFD "IRZCU_NM_PBSMtoRMS_PTCANFD";
BA_ "LongName" SG_ 1267 IRZCU_NM_PBSMtoRMS_PTCANFD "RZCU NM PBSMtoRMS PTCANFD";
BA_ "SysSignalName" SG_ 1267 IRZCU_NM_PBSMtoRMS_PTCANFD "RZCU_NM_PBSMtoRMS_PTCANFD";
BA_ "CompuMethodName" SG_ 1267 IRZCU_NM_RMStoNOS_PTCANFD "RZCU_NM_RMStoNOS_PTCANFD";
BA_ "ISignalName" SG_ 1267 IRZCU_NM_RMStoNOS_PTCANFD "IRZCU_NM_RMStoNOS_PTCANFD";
BA_ "LongName" SG_ 1267 IRZCU_NM_RMStoNOS_PTCANFD "RZCU NM RMStoNOS PTCANFD";
BA_ "SysSignalName" SG_ 1267 IRZCU_NM_RMStoNOS_PTCANFD "RZCU_NM_RMStoNOS_PTCANFD";
BA_ "CompuMethodName" SG_ 1267 IRZCU_NM_RSStoNOS_PTCANFD "RZCU_NM_RSStoNOS_PTCANFD";
BA_ "ISignalName" SG_ 1267 IRZCU_NM_RSStoNOS_PTCANFD "IRZCU_NM_RSStoNOS_PTCANFD";
BA_ "LongName" SG_ 1267 IRZCU_NM_RSStoNOS_PTCANFD "RZCU NM RSStoNOS PTCANFD";
BA_ "SysSignalName" SG_ 1267 IRZCU_NM_RSStoNOS_PTCANFD "RZCU_NM_RSStoNOS_PTCANFD";
BA_ "CompuMethodName" SG_ 1267 IRZCU_NM_RSStoRMS_PTCANFD "RZCU_NM_RSStoRMS_PTCANFD";
BA_ "ISignalName" SG_ 1267 IRZCU_NM_RSStoRMS_PTCANFD "IRZCU_NM_RSStoRMS_PTCANFD";
BA_ "LongName" SG_ 1267 IRZCU_NM_RSStoRMS_PTCANFD "RZCU NM RSStoRMS PTCANFD";
BA_ "SysSignalName" SG_ 1267 IRZCU_NM_RSStoRMS_PTCANFD "RZCU_NM_RSStoRMS_PTCANFD";
BA_ "CompuMethodName" SG_ 1267 IRZCU_NM_NOStoRMS_PTCANFD "RZCU_NM_NOStoRMS_PTCANFD";
BA_ "ISignalName" SG_ 1267 IRZCU_NM_NOStoRMS_PTCANFD "IRZCU_NM_NOStoRMS_PTCANFD";
BA_ "LongName" SG_ 1267 IRZCU_NM_NOStoRMS_PTCANFD "RZCU NM NOStoRMS PTCANFD";
BA_ "SysSignalName" SG_ 1267 IRZCU_NM_NOStoRMS_PTCANFD "RZCU_NM_NOStoRMS_PTCANFD";
BA_ "CompuMethodName" SG_ 1267 IRZCU_NM_NOSSta_PTCANFD "RZCU_NM_NOSSta_PTCANFD";
BA_ "ISignalName" SG_ 1267 IRZCU_NM_NOSSta_PTCANFD "IRZCU_NM_NOSSta_PTCANFD";
BA_ "LongName" SG_ 1267 IRZCU_NM_NOSSta_PTCANFD "RZCU NM NOSSta PTCANFD";
BA_ "SysSignalName" SG_ 1267 IRZCU_NM_NOSSta_PTCANFD "RZCU_NM_NOSSta_PTCANFD";
BA_ "CompuMethodName" SG_ 1267 IRZCU_NM_RMSSta_PTCANFD "RZCU_NM_RMSSta_PTCANFD";
BA_ "ISignalName" SG_ 1267 IRZCU_NM_RMSSta_PTCANFD "IRZCU_NM_RMSSta_PTCANFD";
BA_ "LongName" SG_ 1267 IRZCU_NM_RMSSta_PTCANFD "RZCU NM RMSSta PTCANFD";
BA_ "SysSignalName" SG_ 1267 IRZCU_NM_RMSSta_PTCANFD "RZCU_NM_RMSSta_PTCANFD";
BA_ "CompuMethodName" SG_ 1267 IRZCU_NWI_PTCANFD "RZCU_NWI_PTCANFD";
BA_ "ISignalName" SG_ 1267 IRZCU_NWI_PTCANFD "IRZCU_NWI_PTCANFD";
BA_ "LongName" SG_ 1267 IRZCU_NWI_PTCANFD "RZCU Network Wakeup Indication";
BA_ "SysSignalName" SG_ 1267 IRZCU_NWI_PTCANFD "RZCU_NWI_PTCANFD";
BA_ "CompuMethodName" SG_ 1267 IRZCU_NOI_PTCANFD "RZCU_NOI_PTCANFD";
BA_ "ISignalName" SG_ 1267 IRZCU_NOI_PTCANFD "IRZCU_NOI_PTCANFD";
BA_ "LongName" SG_ 1267 IRZCU_NOI_PTCANFD "RZCU Network Operation Indication";
BA_ "SysSignalName" SG_ 1267 IRZCU_NOI_PTCANFD "RZCU_NOI_PTCANFD";
BA_ "CompuMethodName" SG_ 1267 IRZCU_NKI_PTCANFD "RZCU_NKI_PTCANFD";
BA_ "ISignalName" SG_ 1267 IRZCU_NKI_PTCANFD "IRZCU_NKI_PTCANFD";
BA_ "LongName" SG_ 1267 IRZCU_NKI_PTCANFD "RZCU Network Keep Indication";
BA_ "SysSignalName" SG_ 1267 IRZCU_NKI_PTCANFD "RZCU_NKI_PTCANFD";
BA_ "CompuMethodName" SG_ 247 IRZCU_10ms_Group22_CRC "RZCU_10ms_Group22_CRC";
BA_ "ISignalName" SG_ 247 IRZCU_10ms_Group22_CRC "IRZCU_10ms_Group22_CRC";
BA_ "SysSignalName" SG_ 247 IRZCU_10ms_Group22_CRC "RZCU_10ms_Group22_CRC";
BA_ "CompuMethodName" SG_ 247 IRZCU_10ms_Group22_RC "RZCU_10ms_Group22_RC";
BA_ "ISignalName" SG_ 247 IRZCU_10ms_Group22_RC "IRZCU_10ms_Group22_RC";
BA_ "SysSignalName" SG_ 247 IRZCU_10ms_Group22_RC "RZCU_10ms_Group22_RC";
BA_ "CompuMethodName" SG_ 247 IRZCU_10ms_Group22_Reserved1 "RZCU_10ms_Group22_Reserved1";
BA_ "GenSigStartValue" SG_ 247 IRZCU_10ms_Group22_Reserved1 3;
BA_ "ISignalName" SG_ 247 IRZCU_10ms_Group22_Reserved1 "IRZCU_10ms_Group22_Reserved1";
BA_ "SysSignalName" SG_ 247 IRZCU_10ms_Group22_Reserved1 "RZCU_10ms_Group22_Reserved1";
BA_ "CompuMethodName" SG_ 247 IEPTTrOtptShaftTotMinAvlblToqV "EPTTrOtptShaftTotMinAvlblToqV";
BA_ "ISignalName" SG_ 247 IEPTTrOtptShaftTotMinAvlblToqV "IEPTTrOtptShaftTotMinAvlblToqV";
BA_ "LongName" SG_ 247 IEPTTrOtptShaftTotMinAvlblToqV "Electric_Powertrain_Transmission_Output_Shaft_Total_Minimum_Available_Torque_Validity";
BA_ "SysSignalName" SG_ 247 IEPTTrOtptShaftTotMinAvlblToqV "EPTTrOtptShaftTotMinAvlblToqV";
BA_ "CompuMethodName" SG_ 247 IEPTTrOtptShaftTotMaxAvlblToqV "EPTTrOtptShaftTotMaxAvlblToqV";
BA_ "ISignalName" SG_ 247 IEPTTrOtptShaftTotMaxAvlblToqV "IEPTTrOtptShaftTotMaxAvlblToqV";
BA_ "LongName" SG_ 247 IEPTTrOtptShaftTotMaxAvlblToqV "Electric_Powertrain_Transmission_Output_Shaft_Total_Maximum_Available_Torque_Validity";
BA_ "SysSignalName" SG_ 247 IEPTTrOtptShaftTotMaxAvlblToqV "EPTTrOtptShaftTotMaxAvlblToqV";
BA_ "CompuMethodName" SG_ 247 IEPTTrOtptShaftTotMaxAvlblToq "EPTTrOtptShaftTotMaxAvlblToq";
BA_ "GenSigStartValue" SG_ 247 IEPTTrOtptShaftTotMaxAvlblToq 1696;
BA_ "ISignalName" SG_ 247 IEPTTrOtptShaftTotMaxAvlblToq "IEPTTrOtptShaftTotMaxAvlblToq";
BA_ "LongName" SG_ 247 IEPTTrOtptShaftTotMaxAvlblToq "Electric_Powertrain_Transmission_Output_Shaft_Total_Maximum_Available_Torque";
BA_ "SysSignalName" SG_ 247 IEPTTrOtptShaftTotMaxAvlblToq "EPTTrOtptShaftTotMaxAvlblToq";
BA_ "CompuMethodName" SG_ 247 IEPTTrOtptShaftTotMinAvlblToq "EPTTrOtptShaftTotMinAvlblToq";
BA_ "ISignalName" SG_ 247 IEPTTrOtptShaftTotMinAvlblToq "IEPTTrOtptShaftTotMinAvlblToq";
BA_ "LongName" SG_ 247 IEPTTrOtptShaftTotMinAvlblToq "Electric_Powertrain_Transmission_Output_Shaft_Total_Minimum_Available_Torque";
BA_ "SysSignalName" SG_ 247 IEPTTrOtptShaftTotMinAvlblToq "EPTTrOtptShaftTotMinAvlblToq";
BA_ "CompuMethodName" SG_ 247 IEPTTrOtptShaftTotToq "EPTTrOtptShaftTotToq";
BA_ "ISignalName" SG_ 247 IEPTTrOtptShaftTotToq "IEPTTrOtptShaftTotToq";
BA_ "LongName" SG_ 247 IEPTTrOtptShaftTotToq "Electric_Powertrain_Transmission_Output_Shaft_Total_Torque";
BA_ "SysSignalName" SG_ 247 IEPTTrOtptShaftTotToq "EPTTrOtptShaftTotToq";
BA_ "CompuMethodName" SG_ 247 IEPTTrOtptShaftTotToqV "EPTTrOtptShaftTotToqV";
BA_ "GenSigStartValue" SG_ 247 IEPTTrOtptShaftTotToqV 1;
BA_ "ISignalName" SG_ 247 IEPTTrOtptShaftTotToqV "IEPTTrOtptShaftTotToqV";
BA_ "LongName" SG_ 247 IEPTTrOtptShaftTotToqV "Electric_Powertrain_Transmission_Output_Shaft_Total_Torque_Validity";
BA_ "SysSignalName" SG_ 247 IEPTTrOtptShaftTotToqV "EPTTrOtptShaftTotToqV";
BA_ "CompuMethodName" SG_ 247 IRZCU_10ms_Group22_Reserved2 "RZCU_10ms_Group22_Reserved2";
BA_ "GenSigStartValue" SG_ 247 IRZCU_10ms_Group22_Reserved2 7;
BA_ "ISignalName" SG_ 247 IRZCU_10ms_Group22_Reserved2 "IRZCU_10ms_Group22_Reserved2";
BA_ "SysSignalName" SG_ 247 IRZCU_10ms_Group22_Reserved2 "RZCU_10ms_Group22_Reserved2";
BA_ "CompuMethodName" SG_ 247 IRZCU_10ms_Group22_Reserved3 "RZCU_10ms_Group22_Reserved3";
BA_ "GenSigStartValue" SG_ 247 IRZCU_10ms_Group22_Reserved3 255;
BA_ "ISignalName" SG_ 247 IRZCU_10ms_Group22_Reserved3 "IRZCU_10ms_Group22_Reserved3";
BA_ "SysSignalName" SG_ 247 IRZCU_10ms_Group22_Reserved3 "RZCU_10ms_Group22_Reserved3";
BA_ "CompuMethodName" SG_ 247 IRZCU_10ms_Group22_Reserved4 "RZCU_10ms_Group22_Reserved4";
BA_ "GenSigStartValue" SG_ 247 IRZCU_10ms_Group22_Reserved4 255;
BA_ "ISignalName" SG_ 247 IRZCU_10ms_Group22_Reserved4 "IRZCU_10ms_Group22_Reserved4";
BA_ "SysSignalName" SG_ 247 IRZCU_10ms_Group22_Reserved4 "RZCU_10ms_Group22_Reserved4";
BA_ "CompuMethodName" SG_ 247 IRZCU_10ms_Group22_Reserved5 "RZCU_10ms_Group22_Reserved5";
BA_ "GenSigStartValue" SG_ 247 IRZCU_10ms_Group22_Reserved5 255;
BA_ "ISignalName" SG_ 247 IRZCU_10ms_Group22_Reserved5 "IRZCU_10ms_Group22_Reserved5";
BA_ "SysSignalName" SG_ 247 IRZCU_10ms_Group22_Reserved5 "RZCU_10ms_Group22_Reserved5";
BA_ "CompuMethodName" SG_ 247 IRZCU_10ms_Group22_Reserved6 "RZCU_10ms_Group22_Reserved6";
BA_ "GenSigStartValue" SG_ 247 IRZCU_10ms_Group22_Reserved6 255;
BA_ "ISignalName" SG_ 247 IRZCU_10ms_Group22_Reserved6 "IRZCU_10ms_Group22_Reserved6";
BA_ "SysSignalName" SG_ 247 IRZCU_10ms_Group22_Reserved6 "RZCU_10ms_Group22_Reserved6";
BA_ "CompuMethodName" SG_ 247 IRZCU_10ms_Group22_Reserved7 "RZCU_10ms_Group22_Reserved7";
BA_ "GenSigStartValue" SG_ 247 IRZCU_10ms_Group22_Reserved7 255;
BA_ "ISignalName" SG_ 247 IRZCU_10ms_Group22_Reserved7 "IRZCU_10ms_Group22_Reserved7";
BA_ "SysSignalName" SG_ 247 IRZCU_10ms_Group22_Reserved7 "RZCU_10ms_Group22_Reserved7";
BA_ "CompuMethodName" SG_ 225 IRZCU_10ms_Group23_CRC "RZCU_10ms_Group23_CRC";
BA_ "ISignalName" SG_ 225 IRZCU_10ms_Group23_CRC "IRZCU_10ms_Group23_CRC";
BA_ "SysSignalName" SG_ 225 IRZCU_10ms_Group23_CRC "RZCU_10ms_Group23_CRC";
BA_ "CompuMethodName" SG_ 225 IRZCU_10ms_Group23_RC "RZCU_10ms_Group23_RC";
BA_ "ISignalName" SG_ 225 IRZCU_10ms_Group23_RC "IRZCU_10ms_Group23_RC";
BA_ "SysSignalName" SG_ 225 IRZCU_10ms_Group23_RC "RZCU_10ms_Group23_RC";
BA_ "CompuMethodName" SG_ 225 IRZCU_10ms_Group23_Reserved1 "RZCU_10ms_Group23_Reserved1";
BA_ "GenSigStartValue" SG_ 225 IRZCU_10ms_Group23_Reserved1 15;
BA_ "ISignalName" SG_ 225 IRZCU_10ms_Group23_Reserved1 "IRZCU_10ms_Group23_Reserved1";
BA_ "SysSignalName" SG_ 225 IRZCU_10ms_Group23_Reserved1 "RZCU_10ms_Group23_Reserved1";
BA_ "CompuMethodName" SG_ 225 IRZCU_10ms_Group23_Reserved3 "RZCU_10ms_Group23_Reserved3";
BA_ "GenSigStartValue" SG_ 225 IRZCU_10ms_Group23_Reserved3 7;
BA_ "ISignalName" SG_ 225 IRZCU_10ms_Group23_Reserved3 "IRZCU_10ms_Group23_Reserved3";
BA_ "SysSignalName" SG_ 225 IRZCU_10ms_Group23_Reserved3 "RZCU_10ms_Group23_Reserved3";
BA_ "CompuMethodName" SG_ 225 IAutodDrvngToqReqResp "AutodDrvngToqReqResp";
BA_ "ISignalName" SG_ 225 IAutodDrvngToqReqResp "IAutodDrvngToqReqResp";
BA_ "LongName" SG_ 225 IAutodDrvngToqReqResp "Automated_Driving_Torque_Request_Response";
BA_ "SysSignalName" SG_ 225 IAutodDrvngToqReqResp "AutodDrvngToqReqResp";
BA_ "CompuMethodName" SG_ 225 IRZCU_10ms_Group23_Reserved2 "RZCU_10ms_Group23_Reserved2";
BA_ "GenSigStartValue" SG_ 225 IRZCU_10ms_Group23_Reserved2 3;
BA_ "ISignalName" SG_ 225 IRZCU_10ms_Group23_Reserved2 "IRZCU_10ms_Group23_Reserved2";
BA_ "SysSignalName" SG_ 225 IRZCU_10ms_Group23_Reserved2 "RZCU_10ms_Group23_Reserved2";
BA_ "CompuMethodName" SG_ 225 IRZCU_10ms_Group23_Reserved4 "RZCU_10ms_Group23_Reserved4";
BA_ "GenSigStartValue" SG_ 225 IRZCU_10ms_Group23_Reserved4 31;
BA_ "ISignalName" SG_ 225 IRZCU_10ms_Group23_Reserved4 "IRZCU_10ms_Group23_Reserved4";
BA_ "SysSignalName" SG_ 225 IRZCU_10ms_Group23_Reserved4 "RZCU_10ms_Group23_Reserved4";
BA_ "CompuMethodName" SG_ 225 IPtACCToqReqResp "PtACCToqReqResp";
BA_ "ISignalName" SG_ 225 IPtACCToqReqResp "IPtACCToqReqResp";
BA_ "LongName" SG_ 225 IPtACCToqReqResp "Powertrain_Adaptive_Cruise_Control_Torque_Request_Response";
BA_ "SysSignalName" SG_ 225 IPtACCToqReqResp "PtACCToqReqResp";
BA_ "CompuMethodName" SG_ 225 IAIPilotSysSaBrSts "AIPilotSysSaBrSts";
BA_ "ISignalName" SG_ 225 IAIPilotSysSaBrSts "IAIPilotSysSaBrSts";
BA_ "LongName" SG_ 225 IAIPilotSysSaBrSts "Ai Pilot Control System High Level Safety Braking Status";
BA_ "SysSignalName" SG_ 225 IAIPilotSysSaBrSts "AIPilotSysSaBrSts";
BA_ "CompuMethodName" SG_ 225 IAIPilotSysSaBrInh "AIPilotSysSaBrInh";
BA_ "ISignalName" SG_ 225 IAIPilotSysSaBrInh "IAIPilotSysSaBrInh";
BA_ "LongName" SG_ 225 IAIPilotSysSaBrInh "Ai Pilot Control System High Level Safety Braking Fault Inhibit Reason";
BA_ "SysSignalName" SG_ 225 IAIPilotSysSaBrInh "AIPilotSysSaBrInh";
BA_ "CompuMethodName" SG_ 225 IRZCU_10ms_Group23_Reserved5 "RZCU_10ms_Group23_Reserved5";
BA_ "GenSigStartValue" SG_ 225 IRZCU_10ms_Group23_Reserved5 255;
BA_ "ISignalName" SG_ 225 IRZCU_10ms_Group23_Reserved5 "IRZCU_10ms_Group23_Reserved5";
BA_ "SysSignalName" SG_ 225 IRZCU_10ms_Group23_Reserved5 "RZCU_10ms_Group23_Reserved5";
BA_ "CompuMethodName" SG_ 225 IRZCU_10ms_Group23_Reserved6 "RZCU_10ms_Group23_Reserved6";
BA_ "GenSigStartValue" SG_ 225 IRZCU_10ms_Group23_Reserved6 127;
BA_ "ISignalName" SG_ 225 IRZCU_10ms_Group23_Reserved6 "IRZCU_10ms_Group23_Reserved6";
BA_ "SysSignalName" SG_ 225 IRZCU_10ms_Group23_Reserved6 "RZCU_10ms_Group23_Reserved6";
BA_ "CompuMethodName" SG_ 225 IAccelOvrd "AccelOvrd";
BA_ "ISignalName" SG_ 225 IAccelOvrd "IAccelOvrd";
BA_ "LongName" SG_ 225 IAccelOvrd "Accelerator_Override";
BA_ "SysSignalName" SG_ 225 IAccelOvrd "AccelOvrd";
BA_ "CompuMethodName" SG_ 225 IRZCU_10ms_Group23_Reserved7 "RZCU_10ms_Group23_Reserved7";
BA_ "GenSigStartValue" SG_ 225 IRZCU_10ms_Group23_Reserved7 255;
BA_ "ISignalName" SG_ 225 IRZCU_10ms_Group23_Reserved7 "IRZCU_10ms_Group23_Reserved7";
BA_ "SysSignalName" SG_ 225 IRZCU_10ms_Group23_Reserved7 "RZCU_10ms_Group23_Reserved7";
BA_ "CompuMethodName" SG_ 225 IRZCU_10ms_Group23_Reserved8 "RZCU_10ms_Group23_Reserved8";
BA_ "GenSigStartValue" SG_ 225 IRZCU_10ms_Group23_Reserved8 255;
BA_ "ISignalName" SG_ 225 IRZCU_10ms_Group23_Reserved8 "IRZCU_10ms_Group23_Reserved8";
BA_ "SysSignalName" SG_ 225 IRZCU_10ms_Group23_Reserved8 "RZCU_10ms_Group23_Reserved8";
BA_ "CompuMethodName" SG_ 225 IRZCU_10ms_Group23_Reserved9 "RZCU_10ms_Group23_Reserved9";
BA_ "GenSigStartValue" SG_ 225 IRZCU_10ms_Group23_Reserved9 255;
BA_ "ISignalName" SG_ 225 IRZCU_10ms_Group23_Reserved9 "IRZCU_10ms_Group23_Reserved9";
BA_ "SysSignalName" SG_ 225 IRZCU_10ms_Group23_Reserved9 "RZCU_10ms_Group23_Reserved9";
BA_ "CompuMethodName" SG_ 225 IRZCU_10ms_Group23_Reserved10 "RZCU_10ms_Group23_Reserved10";
BA_ "GenSigStartValue" SG_ 225 IRZCU_10ms_Group23_Reserved10 255;
BA_ "ISignalName" SG_ 225 IRZCU_10ms_Group23_Reserved10 "IRZCU_10ms_Group23_Reserved10";
BA_ "SysSignalName" SG_ 225 IRZCU_10ms_Group23_Reserved10 "RZCU_10ms_Group23_Reserved10";
BA_ "CompuMethodName" SG_ 225 IRZCU_10ms_Group23_Reserved11 "RZCU_10ms_Group23_Reserved11";
BA_ "GenSigStartValue" SG_ 225 IRZCU_10ms_Group23_Reserved11 255;
BA_ "ISignalName" SG_ 225 IRZCU_10ms_Group23_Reserved11 "IRZCU_10ms_Group23_Reserved11";
BA_ "SysSignalName" SG_ 225 IRZCU_10ms_Group23_Reserved11 "RZCU_10ms_Group23_Reserved11";
BA_ "CompuMethodName" SG_ 1266 ITC_NM_BSMtoRMS_PTCANFD "TC_NM_BSMtoRMS_PTCANFD";
BA_ "ISignalName" SG_ 1266 ITC_NM_BSMtoRMS_PTCANFD "ITC_NM_BSMtoRMS_PTCANFD";
BA_ "LongName" SG_ 1266 ITC_NM_BSMtoRMS_PTCANFD "TC NM BSMtoRMS PTCANFD";
BA_ "SysSignalName" SG_ 1266 ITC_NM_BSMtoRMS_PTCANFD "TC_NM_BSMtoRMS_PTCANFD";
BA_ "CompuMethodName" SG_ 1266 ITC_NM_PBSMtoRMS_PTCANFD "TC_NM_PBSMtoRMS_PTCANFD";
BA_ "ISignalName" SG_ 1266 ITC_NM_PBSMtoRMS_PTCANFD "ITC_NM_PBSMtoRMS_PTCANFD";
BA_ "LongName" SG_ 1266 ITC_NM_PBSMtoRMS_PTCANFD "TC NM PBSMtoRMS PTCANFD";
BA_ "SysSignalName" SG_ 1266 ITC_NM_PBSMtoRMS_PTCANFD "TC_NM_PBSMtoRMS_PTCANFD";
BA_ "CompuMethodName" SG_ 1266 ITC_NM_RMStoNOS_PTCANFD "TC_NM_RMStoNOS_PTCANFD";
BA_ "ISignalName" SG_ 1266 ITC_NM_RMStoNOS_PTCANFD "ITC_NM_RMStoNOS_PTCANFD";
BA_ "LongName" SG_ 1266 ITC_NM_RMStoNOS_PTCANFD "TC NM RMStoNOS PTCANFD";
BA_ "SysSignalName" SG_ 1266 ITC_NM_RMStoNOS_PTCANFD "TC_NM_RMStoNOS_PTCANFD";
BA_ "CompuMethodName" SG_ 1266 ITC_NM_RSStoNOS_PTCANFD "TC_NM_RSStoNOS_PTCANFD";
BA_ "ISignalName" SG_ 1266 ITC_NM_RSStoNOS_PTCANFD "ITC_NM_RSStoNOS_PTCANFD";
BA_ "LongName" SG_ 1266 ITC_NM_RSStoNOS_PTCANFD "TC NM RSStoNOS PTCANFD";
BA_ "SysSignalName" SG_ 1266 ITC_NM_RSStoNOS_PTCANFD "TC_NM_RSStoNOS_PTCANFD";
BA_ "CompuMethodName" SG_ 1266 ITC_NM_RSStoRMS_PTCANFD "TC_NM_RSStoRMS_PTCANFD";
BA_ "ISignalName" SG_ 1266 ITC_NM_RSStoRMS_PTCANFD "ITC_NM_RSStoRMS_PTCANFD";
BA_ "LongName" SG_ 1266 ITC_NM_RSStoRMS_PTCANFD "TC NM RSStoRMS PTCANFD";
BA_ "SysSignalName" SG_ 1266 ITC_NM_RSStoRMS_PTCANFD "TC_NM_RSStoRMS_PTCANFD";
BA_ "CompuMethodName" SG_ 1266 ITC_NM_NOStoRMS_PTCANFD "TC_NM_NOStoRMS_PTCANFD";
BA_ "ISignalName" SG_ 1266 ITC_NM_NOStoRMS_PTCANFD "ITC_NM_NOStoRMS_PTCANFD";
BA_ "LongName" SG_ 1266 ITC_NM_NOStoRMS_PTCANFD "TC NM NOStoRMS PTCANFD";
BA_ "SysSignalName" SG_ 1266 ITC_NM_NOStoRMS_PTCANFD "TC_NM_NOStoRMS_PTCANFD";
BA_ "CompuMethodName" SG_ 1266 ITC_NM_NOSSta_PTCANFD "TC_NM_NOSSta_PTCANFD";
BA_ "ISignalName" SG_ 1266 ITC_NM_NOSSta_PTCANFD "ITC_NM_NOSSta_PTCANFD";
BA_ "LongName" SG_ 1266 ITC_NM_NOSSta_PTCANFD "TC NM NOSSta PTCANFD";
BA_ "SysSignalName" SG_ 1266 ITC_NM_NOSSta_PTCANFD "TC_NM_NOSSta_PTCANFD";
BA_ "CompuMethodName" SG_ 1266 ITC_NM_RMSSta_PTCANFD "TC_NM_RMSSta_PTCANFD";
BA_ "ISignalName" SG_ 1266 ITC_NM_RMSSta_PTCANFD "ITC_NM_RMSSta_PTCANFD";
BA_ "LongName" SG_ 1266 ITC_NM_RMSSta_PTCANFD "TC NM RMSSta PTCANFD";
BA_ "SysSignalName" SG_ 1266 ITC_NM_RMSSta_PTCANFD "TC_NM_RMSSta_PTCANFD";
BA_ "CompuMethodName" SG_ 1266 ITC_NWI_PTCANFD "TC_NWI_PTCANFD";
BA_ "ISignalName" SG_ 1266 ITC_NWI_PTCANFD "ITC_NWI_PTCANFD";
BA_ "LongName" SG_ 1266 ITC_NWI_PTCANFD "TC PTCANFD Network_Wakeup Indication";
BA_ "SysSignalName" SG_ 1266 ITC_NWI_PTCANFD "TC_NWI_PTCANFD";
BA_ "CompuMethodName" SG_ 1266 ITC_NOI_PTCANFD "TC_NOI_PTCANFD";
BA_ "ISignalName" SG_ 1266 ITC_NOI_PTCANFD "ITC_NOI_PTCANFD";
BA_ "LongName" SG_ 1266 ITC_NOI_PTCANFD "TC PTCANFD Network Operation Indication";
BA_ "SysSignalName" SG_ 1266 ITC_NOI_PTCANFD "TC_NOI_PTCANFD";
BA_ "CompuMethodName" SG_ 1266 ITC_NKI_PTCANFD "TC_NKI_PTCANFD";
BA_ "ISignalName" SG_ 1266 ITC_NKI_PTCANFD "ITC_NKI_PTCANFD";
BA_ "LongName" SG_ 1266 ITC_NKI_PTCANFD "TC PTCANFD Network Keep Indication";
BA_ "SysSignalName" SG_ 1266 ITC_NKI_PTCANFD "TC_NKI_PTCANFD";
BA_ "CompuMethodName" SG_ 1216 IZXD_NM_BSMtoRMS_PTCANFD "ZXD_NM_BSMtoRMS_PTCANFD";
BA_ "ISignalName" SG_ 1216 IZXD_NM_BSMtoRMS_PTCANFD "IZXD_NM_BSMtoRMS_PTCANFD";
BA_ "LongName" SG_ 1216 IZXD_NM_BSMtoRMS_PTCANFD "ZXD_NM_BSMtoRMS_PTCANFD";
BA_ "SysSignalName" SG_ 1216 IZXD_NM_BSMtoRMS_PTCANFD "ZXD_NM_BSMtoRMS_PTCANFD";
BA_ "CompuMethodName" SG_ 1216 IZXD_NM_PBSMtoRMS_PTCANFD "ZXD_NM_PBSMtoRMS_PTCANFD";
BA_ "ISignalName" SG_ 1216 IZXD_NM_PBSMtoRMS_PTCANFD "IZXD_NM_PBSMtoRMS_PTCANFD";
BA_ "LongName" SG_ 1216 IZXD_NM_PBSMtoRMS_PTCANFD "ZXD_NM_PBSMtoRMS_PTCANFD";
BA_ "SysSignalName" SG_ 1216 IZXD_NM_PBSMtoRMS_PTCANFD "ZXD_NM_PBSMtoRMS_PTCANFD";
BA_ "CompuMethodName" SG_ 1216 IZXD_NM_RMStoNOS_PTCANFD "ZXD_NM_RMStoNOS_PTCANFD";
BA_ "ISignalName" SG_ 1216 IZXD_NM_RMStoNOS_PTCANFD "IZXD_NM_RMStoNOS_PTCANFD";
BA_ "LongName" SG_ 1216 IZXD_NM_RMStoNOS_PTCANFD "ZXD_NM_RMStoNOS_PTCANFD";
BA_ "SysSignalName" SG_ 1216 IZXD_NM_RMStoNOS_PTCANFD "ZXD_NM_RMStoNOS_PTCANFD";
BA_ "CompuMethodName" SG_ 1216 IZXD_NM_RSStoNOS_PTCANFD "ZXD_NM_RSStoNOS_PTCANFD";
BA_ "ISignalName" SG_ 1216 IZXD_NM_RSStoNOS_PTCANFD "IZXD_NM_RSStoNOS_PTCANFD";
BA_ "LongName" SG_ 1216 IZXD_NM_RSStoNOS_PTCANFD "ZXD_NM_RSStoNOS_PTCANFD";
BA_ "SysSignalName" SG_ 1216 IZXD_NM_RSStoNOS_PTCANFD "ZXD_NM_RSStoNOS_PTCANFD";
BA_ "CompuMethodName" SG_ 1216 IZXD_NM_RSStoRMS_PTCANFD "ZXD_NM_RSStoRMS_PTCANFD";
BA_ "ISignalName" SG_ 1216 IZXD_NM_RSStoRMS_PTCANFD "IZXD_NM_RSStoRMS_PTCANFD";
BA_ "LongName" SG_ 1216 IZXD_NM_RSStoRMS_PTCANFD "ZXD_NM_RSStoRMS_PTCANFD";
BA_ "SysSignalName" SG_ 1216 IZXD_NM_RSStoRMS_PTCANFD "ZXD_NM_RSStoRMS_PTCANFD";
BA_ "CompuMethodName" SG_ 1216 IZXD_NM_NOStoRMS_PTCANFD "ZXD_NM_NOStoRMS_PTCANFD";
BA_ "ISignalName" SG_ 1216 IZXD_NM_NOStoRMS_PTCANFD "IZXD_NM_NOStoRMS_PTCANFD";
BA_ "LongName" SG_ 1216 IZXD_NM_NOStoRMS_PTCANFD "ZXD_NM_NOStoRMS_PTCANFD";
BA_ "SysSignalName" SG_ 1216 IZXD_NM_NOStoRMS_PTCANFD "ZXD_NM_NOStoRMS_PTCANFD";
BA_ "CompuMethodName" SG_ 1216 IZXD_NM_NOSSta_PTCANFD "ZXD_NM_NOSSta_PTCANFD";
BA_ "ISignalName" SG_ 1216 IZXD_NM_NOSSta_PTCANFD "IZXD_NM_NOSSta_PTCANFD";
BA_ "LongName" SG_ 1216 IZXD_NM_NOSSta_PTCANFD "ZXD_NM_NOSSta_PTCANFD";
BA_ "SysSignalName" SG_ 1216 IZXD_NM_NOSSta_PTCANFD "ZXD_NM_NOSSta_PTCANFD";
BA_ "CompuMethodName" SG_ 1216 IZXD_NM_RMSSta_PTCANFD "ZXD_NM_RMSSta_PTCANFD";
BA_ "ISignalName" SG_ 1216 IZXD_NM_RMSSta_PTCANFD "IZXD_NM_RMSSta_PTCANFD";
BA_ "LongName" SG_ 1216 IZXD_NM_RMSSta_PTCANFD "ZXD_NM_RMSSta_PTCANFD";
BA_ "SysSignalName" SG_ 1216 IZXD_NM_RMSSta_PTCANFD "ZXD_NM_RMSSta_PTCANFD";
BA_ "CompuMethodName" SG_ 1216 IZXD_NWI_PTCANFD "ZXD_NWI_PTCANFD";
BA_ "ISignalName" SG_ 1216 IZXD_NWI_PTCANFD "IZXD_NWI_PTCANFD";
BA_ "LongName" SG_ 1216 IZXD_NWI_PTCANFD "ZXD RZCUCANFD Network_Wakeup_Indication";
BA_ "SysSignalName" SG_ 1216 IZXD_NWI_PTCANFD "ZXD_NWI_PTCANFD";
BA_ "CompuMethodName" SG_ 1216 IZXD_NOI_PTCANFD "ZXD_NOI_PTCANFD";
BA_ "ISignalName" SG_ 1216 IZXD_NOI_PTCANFD "IZXD_NOI_PTCANFD";
BA_ "LongName" SG_ 1216 IZXD_NOI_PTCANFD "ZXD RZCUCANFD Network Operation Indication";
BA_ "SysSignalName" SG_ 1216 IZXD_NOI_PTCANFD "ZXD_NOI_PTCANFD";
BA_ "CompuMethodName" SG_ 1216 IZXD_NKI_PTCANFD "ZXD_NKI_PTCANFD";
BA_ "ISignalName" SG_ 1216 IZXD_NKI_PTCANFD "IZXD_NKI_PTCANFD";
BA_ "LongName" SG_ 1216 IZXD_NKI_PTCANFD "ZXD RZCUCANFD Network Keep Indication";
BA_ "SysSignalName" SG_ 1216 IZXD_NKI_PTCANFD "ZXD_NKI_PTCANFD";
BA_ "CompuMethodName" SG_ 769 IBMSEmsnRltdMalfA "BMSEmsnRltdMalfA";
BA_ "ISignalName" SG_ 769 IBMSEmsnRltdMalfA "IBMSEmsnRltdMalfA";
BA_ "LongName" SG_ 769 IBMSEmsnRltdMalfA "Battery Management System Emissions Related Malfunction Active";
BA_ "SysSignalName" SG_ 769 IBMSEmsnRltdMalfA "BMSEmsnRltdMalfA";
BA_ "CompuMethodName" SG_ 769 IBMSOdoFctV "BMSOdoFctV";
BA_ "GenSigStartValue" SG_ 769 IBMSOdoFctV 1;
BA_ "ISignalName" SG_ 769 IBMSOdoFctV "IBMSOdoFctV";
BA_ "LongName" SG_ 769 IBMSOdoFctV "Battery Management System Odometer Factor Validity";
BA_ "SysSignalName" SG_ 769 IBMSOdoFctV "BMSOdoFctV";
BA_ "CompuMethodName" SG_ 769 IBMSCdstCtr "BMSCdstCtr";
BA_ "ISignalName" SG_ 769 IBMSCdstCtr "IBMSCdstCtr";
BA_ "LongName" SG_ 769 IBMSCdstCtr "Battery Management System Coldstart Counter";
BA_ "SysSignalName" SG_ 769 IBMSCdstCtr "BMSCdstCtr";
BA_ "CompuMethodName" SG_ 769 IBMSOdoFct "BMSOdoFct";
BA_ "GenSigStartValue" SG_ 769 IBMSOdoFct 255;
BA_ "ISignalName" SG_ 769 IBMSOdoFct "IBMSOdoFct";
BA_ "LongName" SG_ 769 IBMSOdoFct "Battery Management System Odometer Factor";
BA_ "SysSignalName" SG_ 769 IBMSOdoFct "BMSOdoFct";
BA_ "CompuMethodName" SG_ 769 IBMSStdAvlblEnrg "BMSStdAvlblEnrg";
BA_ "GenSigStartValue" SG_ 769 IBMSStdAvlblEnrg 4095;
BA_ "ISignalName" SG_ 769 IBMSStdAvlblEnrg "IBMSStdAvlblEnrg";
BA_ "LongName" SG_ 769 IBMSStdAvlblEnrg "Battery Management System Standard Available Energy";
BA_ "SysSignalName" SG_ 769 IBMSStdAvlblEnrg "BMSStdAvlblEnrg";
BA_ "CompuMethodName" SG_ 769 IBMSChrgTrgtStdAvlblEnrg "BMSChrgTrgtStdAvlblEnrg";
BA_ "GenSigStartValue" SG_ 769 IBMSChrgTrgtStdAvlblEnrg 4095;
BA_ "ISignalName" SG_ 769 IBMSChrgTrgtStdAvlblEnrg "IBMSChrgTrgtStdAvlblEnrg";
BA_ "LongName" SG_ 769 IBMSChrgTrgtStdAvlblEnrg "Battery Management System Charge Target Standard Available Energy";
BA_ "SysSignalName" SG_ 769 IBMSChrgTrgtStdAvlblEnrg "BMSChrgTrgtStdAvlblEnrg";
BA_ "CompuMethodName" SG_ 769 IBMSDisTrgtStdAvlblEnrg "BMSDisTrgtStdAvlblEnrg";
BA_ "GenSigStartValue" SG_ 769 IBMSDisTrgtStdAvlblEnrg 4095;
BA_ "ISignalName" SG_ 769 IBMSDisTrgtStdAvlblEnrg "IBMSDisTrgtStdAvlblEnrg";
BA_ "LongName" SG_ 769 IBMSDisTrgtStdAvlblEnrg "Battery Management System Discharge Standard CLTC Available Energy";
BA_ "SysSignalName" SG_ 769 IBMSDisTrgtStdAvlblEnrg "BMSDisTrgtStdAvlblEnrg";
BA_ "CompuMethodName" SG_ 769 IBMSStdAvlblEnrgV "BMSStdAvlblEnrgV";
BA_ "GenSigStartValue" SG_ 769 IBMSStdAvlblEnrgV 1;
BA_ "ISignalName" SG_ 769 IBMSStdAvlblEnrgV "IBMSStdAvlblEnrgV";
BA_ "LongName" SG_ 769 IBMSStdAvlblEnrgV "Battery Management System Standard Available Energy Validity";
BA_ "SysSignalName" SG_ 769 IBMSStdAvlblEnrgV "BMSStdAvlblEnrgV";
BA_ "CompuMethodName" SG_ 769 IBMSChrgTrgtStdAvlblEnrgV "BMSChrgTrgtStdAvlblEnrgV";
BA_ "GenSigStartValue" SG_ 769 IBMSChrgTrgtStdAvlblEnrgV 1;
BA_ "ISignalName" SG_ 769 IBMSChrgTrgtStdAvlblEnrgV "IBMSChrgTrgtStdAvlblEnrgV";
BA_ "LongName" SG_ 769 IBMSChrgTrgtStdAvlblEnrgV "Battery Management System Charge Target Standard Available Energy Validity";
BA_ "SysSignalName" SG_ 769 IBMSChrgTrgtStdAvlblEnrgV "BMSChrgTrgtStdAvlblEnrgV";
BA_ "CompuMethodName" SG_ 769 IBMSDisTrgtStdAvlblEnrgV "BMSDisTrgtStdAvlblEnrgV";
BA_ "GenSigStartValue" SG_ 769 IBMSDisTrgtStdAvlblEnrgV 1;
BA_ "ISignalName" SG_ 769 IBMSDisTrgtStdAvlblEnrgV "IBMSDisTrgtStdAvlblEnrgV";
BA_ "LongName" SG_ 769 IBMSDisTrgtStdAvlblEnrgV "Battery Management System Discharge Standard CLTC Available Energy Validity";
BA_ "SysSignalName" SG_ 769 IBMSDisTrgtStdAvlblEnrgV "BMSDisTrgtStdAvlblEnrgV";
BA_ "CompuMethodName" SG_ 769 IESS_100ms_Group25_CRC "ESS_100ms_Group25_CRC";
BA_ "ISignalName" SG_ 769 IESS_100ms_Group25_CRC "IESS_100ms_Group25_CRC";
BA_ "SysSignalName" SG_ 769 IESS_100ms_Group25_CRC "ESS_100ms_Group25_CRC";
BA_ "CompuMethodName" SG_ 769 IESS_100ms_Group25_RC "ESS_100ms_Group25_RC";
BA_ "ISignalName" SG_ 769 IESS_100ms_Group25_RC "IESS_100ms_Group25_RC";
BA_ "SysSignalName" SG_ 769 IESS_100ms_Group25_RC "ESS_100ms_Group25_RC";
BA_ "CompuMethodName" SG_ 769 IESS_100ms_Group25_Reserved1 "ESS_100ms_Group25_Reserved1";
BA_ "GenSigStartValue" SG_ 769 IESS_100ms_Group25_Reserved1 15;
BA_ "ISignalName" SG_ 769 IESS_100ms_Group25_Reserved1 "IESS_100ms_Group25_Reserved1";
BA_ "SysSignalName" SG_ 769 IESS_100ms_Group25_Reserved1 "ESS_100ms_Group25_Reserved1";
BA_ "CompuMethodName" SG_ 769 IBMSPosPtIsltnRstc "BMSPosPtIsltnRstc";
BA_ "GenSigStartValue" SG_ 769 IBMSPosPtIsltnRstc 16383;
BA_ "ISignalName" SG_ 769 IBMSPosPtIsltnRstc "IBMSPosPtIsltnRstc";
BA_ "LongName" SG_ 769 IBMSPosPtIsltnRstc "Battery Management System Positive Powertrain Isolation Resistance";
BA_ "SysSignalName" SG_ 769 IBMSPosPtIsltnRstc "BMSPosPtIsltnRstc";
BA_ "CompuMethodName" SG_ 769 IBMSPosPtIsltnRstcV "BMSPosPtIsltnRstcV";
BA_ "GenSigStartValue" SG_ 769 IBMSPosPtIsltnRstcV 1;
BA_ "ISignalName" SG_ 769 IBMSPosPtIsltnRstcV "IBMSPosPtIsltnRstcV";
BA_ "LongName" SG_ 769 IBMSPosPtIsltnRstcV "Battery Management System Postive Powertrain Isolation Resistance Validity";
BA_ "SysSignalName" SG_ 769 IBMSPosPtIsltnRstcV "BMSPosPtIsltnRstcV";
BA_ "CompuMethodName" SG_ 769 IBMSNegPtIsltnRstcV "BMSNegPtIsltnRstcV";
BA_ "GenSigStartValue" SG_ 769 IBMSNegPtIsltnRstcV 1;
BA_ "ISignalName" SG_ 769 IBMSNegPtIsltnRstcV "IBMSNegPtIsltnRstcV";
BA_ "LongName" SG_ 769 IBMSNegPtIsltnRstcV "Battery Management System Negative Powertrain Isolation Resistance Validity";
BA_ "SysSignalName" SG_ 769 IBMSNegPtIsltnRstcV "BMSNegPtIsltnRstcV";
BA_ "CompuMethodName" SG_ 769 IBMSNegPtIsltnRstc "BMSNegPtIsltnRstc";
BA_ "GenSigStartValue" SG_ 769 IBMSNegPtIsltnRstc 16383;
BA_ "ISignalName" SG_ 769 IBMSNegPtIsltnRstc "IBMSNegPtIsltnRstc";
BA_ "LongName" SG_ 769 IBMSNegPtIsltnRstc "Battery Management System Negative Powertrain Isolation Resistance";
BA_ "SysSignalName" SG_ 769 IBMSNegPtIsltnRstc "BMSNegPtIsltnRstc";
BA_ "CompuMethodName" SG_ 769 IESS_100ms_Group25_Reserved2 "ESS_100ms_Group25_Reserved2";
BA_ "GenSigStartValue" SG_ 769 IESS_100ms_Group25_Reserved2 3;
BA_ "ISignalName" SG_ 769 IESS_100ms_Group25_Reserved2 "IESS_100ms_Group25_Reserved2";
BA_ "SysSignalName" SG_ 769 IESS_100ms_Group25_Reserved2 "ESS_100ms_Group25_Reserved2";
BA_ "CompuMethodName" SG_ 769 IESS_100ms_Group25_Reserved3 "ESS_100ms_Group25_Reserved3";
BA_ "GenSigStartValue" SG_ 769 IESS_100ms_Group25_Reserved3 255;
BA_ "ISignalName" SG_ 769 IESS_100ms_Group25_Reserved3 "IESS_100ms_Group25_Reserved3";
BA_ "SysSignalName" SG_ 769 IESS_100ms_Group25_Reserved3 "ESS_100ms_Group25_Reserved3";
BA_ "CompuMethodName" SG_ 769 IESS_100ms_Group25_Reserved4 "ESS_100ms_Group25_Reserved4";
BA_ "GenSigStartValue" SG_ 769 IESS_100ms_Group25_Reserved4 255;
BA_ "ISignalName" SG_ 769 IESS_100ms_Group25_Reserved4 "IESS_100ms_Group25_Reserved4";
BA_ "SysSignalName" SG_ 769 IESS_100ms_Group25_Reserved4 "ESS_100ms_Group25_Reserved4";
BA_ "CompuMethodName" SG_ 769 IBMSStaOfHealthResi "BMSStaOfHealthResi";
BA_ "GenSigStartValue" SG_ 769 IBMSStaOfHealthResi 254;
BA_ "ISignalName" SG_ 769 IBMSStaOfHealthResi "IBMSStaOfHealthResi";
BA_ "LongName" SG_ 769 IBMSStaOfHealthResi "Battery Management System State Of Health Resistance";
BA_ "SysSignalName" SG_ 769 IBMSStaOfHealthResi "BMSStaOfHealthResi";
BA_ "CompuMethodName" SG_ 769 IBMSStaOfHealthCapct "BMSStaOfHealthCapct";
BA_ "GenSigStartValue" SG_ 769 IBMSStaOfHealthCapct 254;
BA_ "ISignalName" SG_ 769 IBMSStaOfHealthCapct "IBMSStaOfHealthCapct";
BA_ "LongName" SG_ 769 IBMSStaOfHealthCapct "Battery Management System State Of Health Capacity";
BA_ "SysSignalName" SG_ 769 IBMSStaOfHealthCapct "BMSStaOfHealthCapct";
BA_ "CompuMethodName" SG_ 769 IBMSOnbdChrgSpRsn "BMSOnbdChrgSpRsn";
BA_ "ISignalName" SG_ 769 IBMSOnbdChrgSpRsn "IBMSOnbdChrgSpRsn";
BA_ "LongName" SG_ 769 IBMSOnbdChrgSpRsn "Battery Management System Onboard Charge Stop Reason";
BA_ "SysSignalName" SG_ 769 IBMSOnbdChrgSpRsn "BMSOnbdChrgSpRsn";
BA_ "CompuMethodName" SG_ 769 IBMSPackSOH "BMSPackSOH";
BA_ "GenSigStartValue" SG_ 769 IBMSPackSOH 1022;
BA_ "ISignalName" SG_ 769 IBMSPackSOH "IBMSPackSOH";
BA_ "LongName" SG_ 769 IBMSPackSOH "Battery Management System Pack State Of Health";
BA_ "SysSignalName" SG_ 769 IBMSPackSOH "BMSPackSOH";
BA_ "CompuMethodName" SG_ 769 IBMSFltLamp "BMSFltLamp";
BA_ "ISignalName" SG_ 769 IBMSFltLamp "IBMSFltLamp";
BA_ "LongName" SG_ 769 IBMSFltLamp "Battery Management System Fault Lamp";
BA_ "SysSignalName" SG_ 769 IBMSFltLamp "BMSFltLamp";
BA_ "CompuMethodName" SG_ 769 IHVBatShutOff "HVBatShutOff";
BA_ "GenSigStartValue" SG_ 769 IHVBatShutOff 1;
BA_ "ISignalName" SG_ 769 IHVBatShutOff "IHVBatShutOff";
BA_ "LongName" SG_ 769 IHVBatShutOff "High Voltage Battery Shut Off";
BA_ "SysSignalName" SG_ 769 IHVBatShutOff "HVBatShutOff";
BA_ "CompuMethodName" SG_ 769 IHVBatSOCHiResV "HVBatSOCHiResV";
BA_ "GenSigStartValue" SG_ 769 IHVBatSOCHiResV 1;
BA_ "ISignalName" SG_ 769 IHVBatSOCHiResV "IHVBatSOCHiResV";
BA_ "LongName" SG_ 769 IHVBatSOCHiResV "High Voltage Battery State Of Charge High Resolution Validity";
BA_ "SysSignalName" SG_ 769 IHVBatSOCHiResV "HVBatSOCHiResV";
BA_ "CompuMethodName" SG_ 769 IHVBatSOCMin "HVBatSOCMin";
BA_ "ISignalName" SG_ 769 IHVBatSOCMin "IHVBatSOCMin";
BA_ "LongName" SG_ 769 IHVBatSOCMin "High Voltage Battery State Of Charge Minimum";
BA_ "SysSignalName" SG_ 769 IHVBatSOCMin "HVBatSOCMin";
BA_ "CompuMethodName" SG_ 769 IHVBatSOCHiRes "HVBatSOCHiRes";
BA_ "ISignalName" SG_ 769 IHVBatSOCHiRes "IHVBatSOCHiRes";
BA_ "LongName" SG_ 769 IHVBatSOCHiRes "High Voltage Battery State Of Charge High Resolution";
BA_ "SysSignalName" SG_ 769 IHVBatSOCHiRes "HVBatSOCHiRes";
BA_ "CompuMethodName" SG_ 769 IHVBatSOCTrgtHiRes "HVBatSOCTrgtHiRes";
BA_ "ISignalName" SG_ 769 IHVBatSOCTrgtHiRes "IHVBatSOCTrgtHiRes";
BA_ "LongName" SG_ 769 IHVBatSOCTrgtHiRes "High Voltage Battery State Of Charge Target High Resolution";
BA_ "SysSignalName" SG_ 769 IHVBatSOCTrgtHiRes "HVBatSOCTrgtHiRes";
BA_ "CompuMethodName" SG_ 769 IESS_100ms_Group58_CRC "ESS_100ms_Group58_CRC";
BA_ "ISignalName" SG_ 769 IESS_100ms_Group58_CRC "IESS_100ms_Group58_CRC";
BA_ "SysSignalName" SG_ 769 IESS_100ms_Group58_CRC "ESS_100ms_Group58_CRC";
BA_ "CompuMethodName" SG_ 769 IESS_100ms_Group58_RC "ESS_100ms_Group58_RC";
BA_ "ISignalName" SG_ 769 IESS_100ms_Group58_RC "IESS_100ms_Group58_RC";
BA_ "SysSignalName" SG_ 769 IESS_100ms_Group58_RC "ESS_100ms_Group58_RC";
BA_ "CompuMethodName" SG_ 769 IBMSOfbdChrgrSktVolV "BMSOfbdChrgrSktVolV";
BA_ "ISignalName" SG_ 769 IBMSOfbdChrgrSktVolV "IBMSOfbdChrgrSktVolV";
BA_ "LongName" SG_ 769 IBMSOfbdChrgrSktVolV "BMS Off-board Charger Socket Voltage Validity";
BA_ "SysSignalName" SG_ 769 IBMSOfbdChrgrSktVolV "BMSOfbdChrgrSktVolV";
BA_ "CompuMethodName" SG_ 769 IESS_100ms_Group58_Reserved1 "ESS_100ms_Group58_Reserved1";
BA_ "GenSigStartValue" SG_ 769 IESS_100ms_Group58_Reserved1 1;
BA_ "ISignalName" SG_ 769 IESS_100ms_Group58_Reserved1 "IESS_100ms_Group58_Reserved1";
BA_ "SysSignalName" SG_ 769 IESS_100ms_Group58_Reserved1 "ESS_100ms_Group58_Reserved1";
BA_ "CompuMethodName" SG_ 769 IBMSOffBdChrgrPlugOn "BMSOffBdChrgrPlugOn";
BA_ "ISignalName" SG_ 769 IBMSOffBdChrgrPlugOn "IBMSOffBdChrgrPlugOn";
BA_ "LongName" SG_ 769 IBMSOffBdChrgrPlugOn "Battery Management System Off Board Charger Plug On";
BA_ "SysSignalName" SG_ 769 IBMSOffBdChrgrPlugOn "BMSOffBdChrgrPlugOn";
BA_ "CompuMethodName" SG_ 769 IESS_100ms_Group58_Reserved2 "ESS_100ms_Group58_Reserved2";
BA_ "GenSigStartValue" SG_ 769 IESS_100ms_Group58_Reserved2 255;
BA_ "ISignalName" SG_ 769 IESS_100ms_Group58_Reserved2 "IESS_100ms_Group58_Reserved2";
BA_ "SysSignalName" SG_ 769 IESS_100ms_Group58_Reserved2 "ESS_100ms_Group58_Reserved2";
BA_ "CompuMethodName" SG_ 769 IESS_100ms_Group58_Reserved3 "ESS_100ms_Group58_Reserved3";
BA_ "GenSigStartValue" SG_ 769 IESS_100ms_Group58_Reserved3 255;
BA_ "ISignalName" SG_ 769 IESS_100ms_Group58_Reserved3 "IESS_100ms_Group58_Reserved3";
BA_ "SysSignalName" SG_ 769 IESS_100ms_Group58_Reserved3 "ESS_100ms_Group58_Reserved3";
BA_ "CompuMethodName" SG_ 769 IBMSOfbdChrgrSktVol "BMSOfbdChrgrSktVol";
BA_ "ISignalName" SG_ 769 IBMSOfbdChrgrSktVol "IBMSOfbdChrgrSktVol";
BA_ "LongName" SG_ 769 IBMSOfbdChrgrSktVol "BMS Off-board Charger Socket Voltage";
BA_ "SysSignalName" SG_ 769 IBMSOfbdChrgrSktVol "BMSOfbdChrgrSktVol";
BA_ "CompuMethodName" SG_ 769 IESS_100ms_Group58_Reserved4 "ESS_100ms_Group58_Reserved4";
BA_ "GenSigStartValue" SG_ 769 IESS_100ms_Group58_Reserved4 3;
BA_ "ISignalName" SG_ 769 IESS_100ms_Group58_Reserved4 "IESS_100ms_Group58_Reserved4";
BA_ "SysSignalName" SG_ 769 IESS_100ms_Group58_Reserved4 "ESS_100ms_Group58_Reserved4";
BA_ "CompuMethodName" SG_ 769 IBMSOffBdChrgrPlugOnV "BMSOffBdChrgrPlugOnV";
BA_ "GenSigStartValue" SG_ 769 IBMSOffBdChrgrPlugOnV 1;
BA_ "ISignalName" SG_ 769 IBMSOffBdChrgrPlugOnV "IBMSOffBdChrgrPlugOnV";
BA_ "LongName" SG_ 769 IBMSOffBdChrgrPlugOnV "Battery Management System Off Board Charger Plug On Validity";
BA_ "SysSignalName" SG_ 769 IBMSOffBdChrgrPlugOnV "BMSOffBdChrgrPlugOnV";
BA_ "CompuMethodName" SG_ 769 IBMSOfbdChrgrWkup "BMSOfbdChrgrWkup";
BA_ "ISignalName" SG_ 769 IBMSOfbdChrgrWkup "IBMSOfbdChrgrWkup";
BA_ "LongName" SG_ 769 IBMSOfbdChrgrWkup "Battery Management System Offboard Charger Wakeup";
BA_ "SysSignalName" SG_ 769 IBMSOfbdChrgrWkup "BMSOfbdChrgrWkup";
BA_ "CompuMethodName" SG_ 769 IESS_100ms_Group58_Reserved5 "ESS_100ms_Group58_Reserved5";
BA_ "GenSigStartValue" SG_ 769 IESS_100ms_Group58_Reserved5 255;
BA_ "ISignalName" SG_ 769 IESS_100ms_Group58_Reserved5 "IESS_100ms_Group58_Reserved5";
BA_ "SysSignalName" SG_ 769 IESS_100ms_Group58_Reserved5 "ESS_100ms_Group58_Reserved5";
BA_ "CompuMethodName" SG_ 769 IESS_100ms_Group58_Reserved6 "ESS_100ms_Group58_Reserved6";
BA_ "GenSigStartValue" SG_ 769 IESS_100ms_Group58_Reserved6 255;
BA_ "ISignalName" SG_ 769 IESS_100ms_Group58_Reserved6 "IESS_100ms_Group58_Reserved6";
BA_ "SysSignalName" SG_ 769 IESS_100ms_Group58_Reserved6 "ESS_100ms_Group58_Reserved6";
BA_ "CompuMethodName" SG_ 548 IVehElecRngDspCmd "VehElecRngDspCmd";
BA_ "ISignalName" SG_ 548 IVehElecRngDspCmd "IVehElecRngDspCmd";
BA_ "LongName" SG_ 548 IVehElecRngDspCmd "Vehicle Electric Range Display Command";
BA_ "SysSignalName" SG_ 548 IVehElecRngDspCmd "VehElecRngDspCmd";
BA_ "CompuMethodName" SG_ 548 IElecDrvRngPerKwhV "ElecDrvRngPerKwhV";
BA_ "GenSigStartValue" SG_ 548 IElecDrvRngPerKwhV 1;
BA_ "ISignalName" SG_ 548 IElecDrvRngPerKwhV "IElecDrvRngPerKwhV";
BA_ "LongName" SG_ 548 IElecDrvRngPerKwhV "Electrical Drive Range Per kwh Valid";
BA_ "SysSignalName" SG_ 548 IElecDrvRngPerKwhV "ElecDrvRngPerKwhV";
BA_ "CompuMethodName" SG_ 548 IVehElecRngV "VehElecRngV";
BA_ "GenSigStartValue" SG_ 548 IVehElecRngV 1;
BA_ "ISignalName" SG_ 548 IVehElecRngV "IVehElecRngV";
BA_ "LongName" SG_ 548 IVehElecRngV "Battery Management System Distance Vehicle Electric Range Validity";
BA_ "SysSignalName" SG_ 548 IVehElecRngV "VehElecRngV";
BA_ "CompuMethodName" SG_ 548 IElecDrvRngPerKwh "ElecDrvRngPerKwh";
BA_ "ISignalName" SG_ 548 IElecDrvRngPerKwh "IElecDrvRngPerKwh";
BA_ "LongName" SG_ 548 IElecDrvRngPerKwh "Electrical Drive Range Per kwh";
BA_ "SysSignalName" SG_ 548 IElecDrvRngPerKwh "ElecDrvRngPerKwh";
BA_ "CompuMethodName" SG_ 548 IBMSOfbdChrgrMaxOtptVol "BMSOfbdChrgrMaxOtptVol";
BA_ "GenSigStartValue" SG_ 548 IBMSOfbdChrgrMaxOtptVol 4095;
BA_ "ISignalName" SG_ 548 IBMSOfbdChrgrMaxOtptVol "IBMSOfbdChrgrMaxOtptVol";
BA_ "LongName" SG_ 548 IBMSOfbdChrgrMaxOtptVol "Battery Management System Offboard Charger Maximum Output Voltage";
BA_ "SysSignalName" SG_ 548 IBMSOfbdChrgrMaxOtptVol "BMSOfbdChrgrMaxOtptVol";
BA_ "CompuMethodName" SG_ 548 IBMSOfbdChrgrOtptVol "BMSOfbdChrgrOtptVol";
BA_ "GenSigStartValue" SG_ 548 IBMSOfbdChrgrOtptVol 4095;
BA_ "ISignalName" SG_ 548 IBMSOfbdChrgrOtptVol "IBMSOfbdChrgrOtptVol";
BA_ "LongName" SG_ 548 IBMSOfbdChrgrOtptVol "Battery Management System Offboard Charger Output Voltage";
BA_ "SysSignalName" SG_ 548 IBMSOfbdChrgrOtptVol "BMSOfbdChrgrOtptVol";
BA_ "CompuMethodName" SG_ 548 IBMSOfbdChrgrMaxOtptVolV "BMSOfbdChrgrMaxOtptVolV";
BA_ "GenSigStartValue" SG_ 548 IBMSOfbdChrgrMaxOtptVolV 1;
BA_ "ISignalName" SG_ 548 IBMSOfbdChrgrMaxOtptVolV "IBMSOfbdChrgrMaxOtptVolV";
BA_ "LongName" SG_ 548 IBMSOfbdChrgrMaxOtptVolV "Battery Management System Offboard Charger Maximum Output Voltage Validity";
BA_ "SysSignalName" SG_ 548 IBMSOfbdChrgrMaxOtptVolV "BMSOfbdChrgrMaxOtptVolV";
BA_ "CompuMethodName" SG_ 548 IBMSOfbdChrgrOtptCrnt "BMSOfbdChrgrOtptCrnt";
BA_ "GenSigStartValue" SG_ 548 IBMSOfbdChrgrOtptCrnt 2047;
BA_ "ISignalName" SG_ 548 IBMSOfbdChrgrOtptCrnt "IBMSOfbdChrgrOtptCrnt";
BA_ "LongName" SG_ 548 IBMSOfbdChrgrOtptCrnt "Battery Management System Offboard Charger Output Current";
BA_ "SysSignalName" SG_ 548 IBMSOfbdChrgrOtptCrnt "BMSOfbdChrgrOtptCrnt";
BA_ "CompuMethodName" SG_ 548 IBMSOfbdChrgrOtptVolV "BMSOfbdChrgrOtptVolV";
BA_ "GenSigStartValue" SG_ 548 IBMSOfbdChrgrOtptVolV 1;
BA_ "ISignalName" SG_ 548 IBMSOfbdChrgrOtptVolV "IBMSOfbdChrgrOtptVolV";
BA_ "LongName" SG_ 548 IBMSOfbdChrgrOtptVolV "Battery Management System Offboard Charger Output Voltage Validity";
BA_ "SysSignalName" SG_ 548 IBMSOfbdChrgrOtptVolV "BMSOfbdChrgrOtptVolV";
BA_ "CompuMethodName" SG_ 548 IBMSOfbdChrgngMd "BMSOfbdChrgngMd";
BA_ "ISignalName" SG_ 548 IBMSOfbdChrgngMd "IBMSOfbdChrgngMd";
BA_ "LongName" SG_ 548 IBMSOfbdChrgngMd "Battery Management System Offboard Charging Mode";
BA_ "SysSignalName" SG_ 548 IBMSOfbdChrgngMd "BMSOfbdChrgngMd";
BA_ "CompuMethodName" SG_ 548 IBMSOfbdChrgrOtptCrnV "BMSOfbdChrgrOtptCrnV";
BA_ "GenSigStartValue" SG_ 548 IBMSOfbdChrgrOtptCrnV 1;
BA_ "ISignalName" SG_ 548 IBMSOfbdChrgrOtptCrnV "IBMSOfbdChrgrOtptCrnV";
BA_ "LongName" SG_ 548 IBMSOfbdChrgrOtptCrnV "Battery Management System Offboard Charger Output Current Validity";
BA_ "SysSignalName" SG_ 548 IBMSOfbdChrgrOtptCrnV "BMSOfbdChrgrOtptCrnV";
BA_ "CompuMethodName" SG_ 548 IVehElecRng "VehElecRng";
BA_ "GenSigStartValue" SG_ 548 IVehElecRng 2047;
BA_ "ISignalName" SG_ 548 IVehElecRng "IVehElecRng";
BA_ "LongName" SG_ 548 IVehElecRng "Vehicle Electric Range";
BA_ "SysSignalName" SG_ 548 IVehElecRng "VehElecRng";
BA_ "CompuMethodName" SG_ 548 IBMSEnbPTC "BMSEnbPTC";
BA_ "ISignalName" SG_ 548 IBMSEnbPTC "IBMSEnbPTC";
BA_ "LongName" SG_ 548 IBMSEnbPTC "Battery Management System Enable Positive Temperature Coefficient";
BA_ "SysSignalName" SG_ 548 IBMSEnbPTC "BMSEnbPTC";
BA_ "CompuMethodName" SG_ 548 IHVOffMoSts "HVOffMoSts";
BA_ "ISignalName" SG_ 548 IHVOffMoSts "IHVOffMoSts";
BA_ "LongName" SG_ 548 IHVOffMoSts "High Voltage Off Monitor Status";
BA_ "SysSignalName" SG_ 548 IHVOffMoSts "HVOffMoSts";
BA_ "CompuMethodName" SG_ 548 IBMSPTCHeatReqDspCmd "BMSPTCHeatReqDspCmd";
BA_ "ISignalName" SG_ 548 IBMSPTCHeatReqDspCmd "IBMSPTCHeatReqDspCmd";
BA_ "LongName" SG_ 548 IBMSPTCHeatReqDspCmd "Battery Management System Positive Temperature Coefficient Heat Request Display Command";
BA_ "SysSignalName" SG_ 548 IBMSPTCHeatReqDspCmd "BMSPTCHeatReqDspCmd";
BA_ "CompuMethodName" SG_ 548 IChrgngRmnngTimeV "ChrgngRmnngTimeV";
BA_ "GenSigStartValue" SG_ 548 IChrgngRmnngTimeV 1;
BA_ "ISignalName" SG_ 548 IChrgngRmnngTimeV "IChrgngRmnngTimeV";
BA_ "LongName" SG_ 548 IChrgngRmnngTimeV "Charging Remaining Time Validity";
BA_ "SysSignalName" SG_ 548 IChrgngRmnngTimeV "ChrgngRmnngTimeV";
BA_ "CompuMethodName" SG_ 548 IBMSChrgrPlugCnctnIO "BMSChrgrPlugCnctnIO";
BA_ "GenSigStartValue" SG_ 548 IBMSChrgrPlugCnctnIO 1;
BA_ "ISignalName" SG_ 548 IBMSChrgrPlugCnctnIO "IBMSChrgrPlugCnctnIO";
BA_ "LongName" SG_ 548 IBMSChrgrPlugCnctnIO "Battery Management System Charger Plug Connection Indication On";
BA_ "SysSignalName" SG_ 548 IBMSChrgrPlugCnctnIO "BMSChrgrPlugCnctnIO";
BA_ "CompuMethodName" SG_ 548 IBMSCumuDschrgEnrgV "BMSCumuDschrgEnrgV";
BA_ "GenSigStartValue" SG_ 548 IBMSCumuDschrgEnrgV 1;
BA_ "ISignalName" SG_ 548 IBMSCumuDschrgEnrgV "IBMSCumuDschrgEnrgV";
BA_ "LongName" SG_ 548 IBMSCumuDschrgEnrgV "Battery Management System Cumulative Discharge Energy Validity";
BA_ "SysSignalName" SG_ 548 IBMSCumuDschrgEnrgV "BMSCumuDschrgEnrgV";
BA_ "CompuMethodName" SG_ 548 IBMSCumuDschrgEnrg "BMSCumuDschrgEnrg";
BA_ "GenSigStartValue" SG_ 548 IBMSCumuDschrgEnrg 16777215;
BA_ "ISignalName" SG_ 548 IBMSCumuDschrgEnrg "IBMSCumuDschrgEnrg";
BA_ "LongName" SG_ 548 IBMSCumuDschrgEnrg "Battery Management System Cumulative Discharge Energy";
BA_ "SysSignalName" SG_ 548 IBMSCumuDschrgEnrg "BMSCumuDschrgEnrg";
BA_ "CompuMethodName" SG_ 548 IChrgngRmnngTime "ChrgngRmnngTime";
BA_ "GenSigStartValue" SG_ 548 IChrgngRmnngTime 1023;
BA_ "ISignalName" SG_ 548 IChrgngRmnngTime "IChrgngRmnngTime";
BA_ "LongName" SG_ 548 IChrgngRmnngTime "Charging Remaining Time";
BA_ "SysSignalName" SG_ 548 IChrgngRmnngTime "ChrgngRmnngTime";
BA_ "CompuMethodName" SG_ 548 IBMSEleccLckCtrlDspCmd "BMSEleccLckCtrlDspCmd";
BA_ "ISignalName" SG_ 548 IBMSEleccLckCtrlDspCmd "IBMSEleccLckCtrlDspCmd";
BA_ "LongName" SG_ 548 IBMSEleccLckCtrlDspCmd "Battery Management System Electronic Lock Control Display Command";
BA_ "SysSignalName" SG_ 548 IBMSEleccLckCtrlDspCmd "BMSEleccLckCtrlDspCmd";
BA_ "CompuMethodName" SG_ 548 IBMSPackSOCCorr "BMSPackSOCCorr";
BA_ "ISignalName" SG_ 548 IBMSPackSOCCorr "IBMSPackSOCCorr";
BA_ "LongName" SG_ 548 IBMSPackSOCCorr "BMS PacksOCcorrection";
BA_ "SysSignalName" SG_ 548 IBMSPackSOCCorr "BMSPackSOCCorr";
BA_ "CompuMethodName" SG_ 548 IBMSPTCHeatResp "BMSPTCHeatResp";
BA_ "ISignalName" SG_ 548 IBMSPTCHeatResp "IBMSPTCHeatResp";
BA_ "LongName" SG_ 548 IBMSPTCHeatResp "Battery Management System Ptc Heat Response";
BA_ "SysSignalName" SG_ 548 IBMSPTCHeatResp "BMSPTCHeatResp";
BA_ "CompuMethodName" SG_ 548 IBMSNotfnPushReq "BMSNotfnPushReq";
BA_ "ISignalName" SG_ 548 IBMSNotfnPushReq "IBMSNotfnPushReq";
BA_ "LongName" SG_ 548 IBMSNotfnPushReq "Battery Management System Notification Push Request";
BA_ "SysSignalName" SG_ 548 IBMSNotfnPushReq "BMSNotfnPushReq";
BA_ "CompuMethodName" SG_ 548 IBMSBattNoFuChargReq "BMSBattNoFuChargReq";
BA_ "ISignalName" SG_ 548 IBMSBattNoFuChargReq "IBMSBattNoFuChargReq";
BA_ "LongName" SG_ 548 IBMSBattNoFuChargReq "Battery Management System Battery No Full Charge Request";
BA_ "SysSignalName" SG_ 548 IBMSBattNoFuChargReq "BMSBattNoFuChargReq";
BA_ "CompuMethodName" SG_ 548 IBMSPackSOCE "BMSPackSOCE";
BA_ "GenSigStartValue" SG_ 548 IBMSPackSOCE 255;
BA_ "ISignalName" SG_ 548 IBMSPackSOCE "IBMSPackSOCE";
BA_ "LongName" SG_ 548 IBMSPackSOCE "BMS pack state of certified energy";
BA_ "SysSignalName" SG_ 548 IBMSPackSOCE "BMSPackSOCE";
BA_ "CompuMethodName" SG_ 548 IBMSPackSOC "BMSPackSOC";
BA_ "GenSigStartValue" SG_ 548 IBMSPackSOC 1023;
BA_ "ISignalName" SG_ 548 IBMSPackSOC "IBMSPackSOC";
BA_ "LongName" SG_ 548 IBMSPackSOC "Battery Management System Pack State Of Charge";
BA_ "SysSignalName" SG_ 548 IBMSPackSOC "BMSPackSOC";
BA_ "CompuMethodName" SG_ 548 IBMSPackSOCV "BMSPackSOCV";
BA_ "GenSigStartValue" SG_ 548 IBMSPackSOCV 1;
BA_ "ISignalName" SG_ 548 IBMSPackSOCV "IBMSPackSOCV";
BA_ "LongName" SG_ 548 IBMSPackSOCV "Battery Management System Pack State Of Charge Validity";
BA_ "SysSignalName" SG_ 548 IBMSPackSOCV "BMSPackSOCV";
BA_ "CompuMethodName" SG_ 548 IBMSPackSOCActual "BMSPackSOCActual";
BA_ "GenSigStartValue" SG_ 548 IBMSPackSOCActual 254;
BA_ "ISignalName" SG_ 548 IBMSPackSOCActual "IBMSPackSOCActual";
BA_ "LongName" SG_ 548 IBMSPackSOCActual "Battery Management System Pack Actual State Of Charge";
BA_ "SysSignalName" SG_ 548 IBMSPackSOCActual "BMSPackSOCActual";
BA_ "CompuMethodName" SG_ 548 IBMSPackSOCDsp "BMSPackSOCDsp";
BA_ "GenSigStartValue" SG_ 548 IBMSPackSOCDsp 1023;
BA_ "ISignalName" SG_ 548 IBMSPackSOCDsp "IBMSPackSOCDsp";
BA_ "LongName" SG_ 548 IBMSPackSOCDsp "Battery Management System Pack State Of Charge Display";
BA_ "SysSignalName" SG_ 548 IBMSPackSOCDsp "BMSPackSOCDsp";
BA_ "CompuMethodName" SG_ 548 IBMSPackSOCDspV "BMSPackSOCDspV";
BA_ "GenSigStartValue" SG_ 548 IBMSPackSOCDspV 1;
BA_ "ISignalName" SG_ 548 IBMSPackSOCDspV "IBMSPackSOCDspV";
BA_ "LongName" SG_ 548 IBMSPackSOCDspV "Battery Management System Pack State Of Charge Display Validity";
BA_ "SysSignalName" SG_ 548 IBMSPackSOCDspV "BMSPackSOCDspV";
BA_ "CompuMethodName" SG_ 548 IBMSPackSOCEV "BMSPackSOCEV";
BA_ "GenSigStartValue" SG_ 548 IBMSPackSOCEV 1;
BA_ "ISignalName" SG_ 548 IBMSPackSOCEV "IBMSPackSOCEV";
BA_ "LongName" SG_ 548 IBMSPackSOCEV "BMS pack state of certified energy Vailid";
BA_ "SysSignalName" SG_ 548 IBMSPackSOCEV "BMSPackSOCEV";
BA_ "CompuMethodName" SG_ 548 IBMSSysCoolResp "BMSSysCoolResp";
BA_ "ISignalName" SG_ 548 IBMSSysCoolResp "IBMSSysCoolResp";
BA_ "LongName" SG_ 548 IBMSSysCoolResp "Battery Management System Cool Response";
BA_ "SysSignalName" SG_ 548 IBMSSysCoolResp "BMSSysCoolResp";
BA_ "CompuMethodName" SG_ 548 IBMSOnbdChrgngCmdReq "BMSOnbdChrgngCmdReq";
BA_ "ISignalName" SG_ 548 IBMSOnbdChrgngCmdReq "IBMSOnbdChrgngCmdReq";
BA_ "LongName" SG_ 548 IBMSOnbdChrgngCmdReq "Battery Management System Onboard Charging Command Request";
BA_ "SysSignalName" SG_ 548 IBMSOnbdChrgngCmdReq "BMSOnbdChrgngCmdReq";
BA_ "CompuMethodName" SG_ 548 IBMSCtrlS2Req "BMSCtrlS2Req";
BA_ "ISignalName" SG_ 548 IBMSCtrlS2Req "IBMSCtrlS2Req";
BA_ "LongName" SG_ 548 IBMSCtrlS2Req "Battery Management System Control S2 Request";
BA_ "SysSignalName" SG_ 548 IBMSCtrlS2Req "BMSCtrlS2Req";
BA_ "CompuMethodName" SG_ 548 IBMSDsChrgSpRsn "BMSDsChrgSpRsn";
BA_ "ISignalName" SG_ 548 IBMSDsChrgSpRsn "IBMSDsChrgSpRsn";
BA_ "LongName" SG_ 548 IBMSDsChrgSpRsn "Battery Management System Discharge Stop Reason";
BA_ "SysSignalName" SG_ 548 IBMSDsChrgSpRsn "BMSDsChrgSpRsn";
BA_ "CompuMethodName" SG_ 548 IBMSOnbdChrgrAltCrntLmt "BMSOnbdChrgrAltCrntLmt";
BA_ "ISignalName" SG_ 548 IBMSOnbdChrgrAltCrntLmt "IBMSOnbdChrgrAltCrntLmt";
BA_ "LongName" SG_ 548 IBMSOnbdChrgrAltCrntLmt "Battery Management System On Board Charger Alternating Current Limit";
BA_ "SysSignalName" SG_ 548 IBMSOnbdChrgrAltCrntLmt "BMSOnbdChrgrAltCrntLmt";
BA_ "CompuMethodName" SG_ 548 IBMSOnbdChrgrOtptCrntReq "BMSOnbdChrgrOtptCrntReq";
BA_ "ISignalName" SG_ 548 IBMSOnbdChrgrOtptCrntReq "IBMSOnbdChrgrOtptCrntReq";
BA_ "LongName" SG_ 548 IBMSOnbdChrgrOtptCrntReq "Battery Management System On Board Charger Output Current Request";
BA_ "SysSignalName" SG_ 548 IBMSOnbdChrgrOtptCrntReq "BMSOnbdChrgrOtptCrntReq";
BA_ "CompuMethodName" SG_ 548 IBMSOnbdChrgngMd "BMSOnbdChrgngMd";
BA_ "ISignalName" SG_ 548 IBMSOnbdChrgngMd "IBMSOnbdChrgngMd";
BA_ "LongName" SG_ 548 IBMSOnbdChrgngMd "Battery Management System Onboard Charging Mode";
BA_ "SysSignalName" SG_ 548 IBMSOnbdChrgngMd "BMSOnbdChrgngMd";
BA_ "CompuMethodName" SG_ 548 IBMSOnbdChrgrOtptVolReqV "BMSOnbdChrgrOtptVolReqV";
BA_ "ISignalName" SG_ 548 IBMSOnbdChrgrOtptVolReqV "IBMSOnbdChrgrOtptVolReqV";
BA_ "LongName" SG_ 548 IBMSOnbdChrgrOtptVolReqV "Battery Management System Onboard Charger Output Voltage Request Validity";
BA_ "SysSignalName" SG_ 548 IBMSOnbdChrgrOtptVolReqV "BMSOnbdChrgrOtptVolReqV";
BA_ "CompuMethodName" SG_ 548 IBMSOnbdChrgrOtptVolReq "BMSOnbdChrgrOtptVolReq";
BA_ "ISignalName" SG_ 548 IBMSOnbdChrgrOtptVolReq "IBMSOnbdChrgrOtptVolReq";
BA_ "LongName" SG_ 548 IBMSOnbdChrgrOtptVolReq "Battery Management System Onboard Charger Output Voltage Request";
BA_ "SysSignalName" SG_ 548 IBMSOnbdChrgrOtptVolReq "BMSOnbdChrgrOtptVolReq";
BA_ "CompuMethodName" SG_ 548 IVehCltcElecCsumpV "VehCltcElecCsumpV";
BA_ "GenSigStartValue" SG_ 548 IVehCltcElecCsumpV 1;
BA_ "ISignalName" SG_ 548 IVehCltcElecCsumpV "IVehCltcElecCsumpV";
BA_ "LongName" SG_ 548 IVehCltcElecCsumpV "Vehicle CLTC Electric Consumption Validity";
BA_ "SysSignalName" SG_ 548 IVehCltcElecCsumpV "VehCltcElecCsumpV";
BA_ "CompuMethodName" SG_ 548 IBMSAvlblEnrgV "BMSAvlblEnrgV";
BA_ "GenSigStartValue" SG_ 548 IBMSAvlblEnrgV 1;
BA_ "ISignalName" SG_ 548 IBMSAvlblEnrgV "IBMSAvlblEnrgV";
BA_ "LongName" SG_ 548 IBMSAvlblEnrgV "Battery Management System Available Energy Validity";
BA_ "SysSignalName" SG_ 548 IBMSAvlblEnrgV "BMSAvlblEnrgV";
BA_ "CompuMethodName" SG_ 548 ICrntAvgElecCsumpV "CrntAvgElecCsumpV";
BA_ "GenSigStartValue" SG_ 548 ICrntAvgElecCsumpV 1;
BA_ "ISignalName" SG_ 548 ICrntAvgElecCsumpV "ICrntAvgElecCsumpV";
BA_ "LongName" SG_ 548 ICrntAvgElecCsumpV "Current Average Electric Consumption Validity";
BA_ "SysSignalName" SG_ 548 ICrntAvgElecCsumpV "CrntAvgElecCsumpV";
BA_ "CompuMethodName" SG_ 548 IVehCltcElecCsump "VehCltcElecCsump";
BA_ "GenSigStartValue" SG_ 548 IVehCltcElecCsump 1023;
BA_ "ISignalName" SG_ 548 IVehCltcElecCsump "IVehCltcElecCsump";
BA_ "LongName" SG_ 548 IVehCltcElecCsump "Vehicle CLTC Electric Consumption";
BA_ "SysSignalName" SG_ 548 IVehCltcElecCsump "VehCltcElecCsump";
BA_ "CompuMethodName" SG_ 548 ICrntAvgElecCsump "CrntAvgElecCsump";
BA_ "GenSigStartValue" SG_ 548 ICrntAvgElecCsump 1023;
BA_ "ISignalName" SG_ 548 ICrntAvgElecCsump "ICrntAvgElecCsump";
BA_ "LongName" SG_ 548 ICrntAvgElecCsump "Current Average Electric Consumption";
BA_ "SysSignalName" SG_ 548 ICrntAvgElecCsump "CrntAvgElecCsump";
BA_ "CompuMethodName" SG_ 548 IElecCsumpPerKm "ElecCsumpPerKm";
BA_ "GenSigStartValue" SG_ 548 IElecCsumpPerKm 1023;
BA_ "ISignalName" SG_ 548 IElecCsumpPerKm "IElecCsumpPerKm";
BA_ "LongName" SG_ 548 IElecCsumpPerKm "Electric Consumption Per Kilometer";
BA_ "SysSignalName" SG_ 548 IElecCsumpPerKm "ElecCsumpPerKm";
BA_ "CompuMethodName" SG_ 548 IHVBatElecEnrgAvgRate "HVBatElecEnrgAvgRate";
BA_ "GenSigStartValue" SG_ 548 IHVBatElecEnrgAvgRate 1023;
BA_ "ISignalName" SG_ 548 IHVBatElecEnrgAvgRate "IHVBatElecEnrgAvgRate";
BA_ "LongName" SG_ 548 IHVBatElecEnrgAvgRate "High Voltage Battery Electric Energy Average Rate";
BA_ "SysSignalName" SG_ 548 IHVBatElecEnrgAvgRate "HVBatElecEnrgAvgRate";
BA_ "CompuMethodName" SG_ 548 IHVBatElecEnrgAvgRateV "HVBatElecEnrgAvgRateV";
BA_ "GenSigStartValue" SG_ 548 IHVBatElecEnrgAvgRateV 1;
BA_ "ISignalName" SG_ 548 IHVBatElecEnrgAvgRateV "IHVBatElecEnrgAvgRateV";
BA_ "LongName" SG_ 548 IHVBatElecEnrgAvgRateV "High Voltage Battery Electric Energy Average Rate Validity";
BA_ "SysSignalName" SG_ 548 IHVBatElecEnrgAvgRateV "HVBatElecEnrgAvgRateV";
BA_ "CompuMethodName" SG_ 548 IElecEnrgAvgRstPerfd "ElecEnrgAvgRstPerfd";
BA_ "ISignalName" SG_ 548 IElecEnrgAvgRstPerfd "IElecEnrgAvgRstPerfd";
BA_ "LongName" SG_ 548 IElecEnrgAvgRstPerfd "Electric Energy Average Reset Performed";
BA_ "SysSignalName" SG_ 548 IElecEnrgAvgRstPerfd "ElecEnrgAvgRstPerfd";
BA_ "CompuMethodName" SG_ 548 IElecCsumpPerKmV "ElecCsumpPerKmV";
BA_ "GenSigStartValue" SG_ 548 IElecCsumpPerKmV 1;
BA_ "ISignalName" SG_ 548 IElecCsumpPerKmV "IElecCsumpPerKmV";
BA_ "LongName" SG_ 548 IElecCsumpPerKmV "Electric Consumption Per Kilometer Validity";
BA_ "SysSignalName" SG_ 548 IElecCsumpPerKmV "ElecCsumpPerKmV";
BA_ "CompuMethodName" SG_ 548 IBMSAvlblEnrg "BMSAvlblEnrg";
BA_ "GenSigStartValue" SG_ 548 IBMSAvlblEnrg 255;
BA_ "ISignalName" SG_ 548 IBMSAvlblEnrg "IBMSAvlblEnrg";
BA_ "LongName" SG_ 548 IBMSAvlblEnrg "Battery Management System Available Energy";
BA_ "SysSignalName" SG_ 548 IBMSAvlblEnrg "BMSAvlblEnrg";
BA_ "CompuMethodName" SG_ 404 IRZCU_20ms_Group06_CRC "RZCU_20ms_Group06_CRC";
BA_ "ISignalName" SG_ 404 IRZCU_20ms_Group06_CRC "IRZCU_20ms_Group06_CRC";
BA_ "SysSignalName" SG_ 404 IRZCU_20ms_Group06_CRC "RZCU_20ms_Group06_CRC";
BA_ "CompuMethodName" SG_ 404 IRZCU_20ms_Group06_RC "RZCU_20ms_Group06_RC";
BA_ "ISignalName" SG_ 404 IRZCU_20ms_Group06_RC "IRZCU_20ms_Group06_RC";
BA_ "SysSignalName" SG_ 404 IRZCU_20ms_Group06_RC "RZCU_20ms_Group06_RC";
BA_ "CompuMethodName" SG_ 404 ITrEstdGearV "TrEstdGearV";
BA_ "ISignalName" SG_ 404 ITrEstdGearV "ITrEstdGearV";
BA_ "LongName" SG_ 404 ITrEstdGearV "Transmission Estimated Gear Validity";
BA_ "SysSignalName" SG_ 404 ITrEstdGearV "TrEstdGearV";
BA_ "CompuMethodName" SG_ 404 IEPTRdyV "EPTRdyV";
BA_ "GenSigStartValue" SG_ 404 IEPTRdyV 1;
BA_ "ISignalName" SG_ 404 IEPTRdyV "IEPTRdyV";
BA_ "LongName" SG_ 404 IEPTRdyV "Electric Powertrain Ready Validity";
BA_ "SysSignalName" SG_ 404 IEPTRdyV "EPTRdyV";
BA_ "CompuMethodName" SG_ 404 IEPTRdy "EPTRdy";
BA_ "ISignalName" SG_ 404 IEPTRdy "IEPTRdy";
BA_ "LongName" SG_ 404 IEPTRdy "Electric_Powertrain_Ready";
BA_ "SysSignalName" SG_ 404 IEPTRdy "EPTRdy";
BA_ "CompuMethodName" SG_ 404 ITrShftLvrPosV "TrShftLvrPosV";
BA_ "ISignalName" SG_ 404 ITrShftLvrPosV "ITrShftLvrPosV";
BA_ "LongName" SG_ 404 ITrShftLvrPosV "Transmission_Shift_Lever_Position_Validity";
BA_ "SysSignalName" SG_ 404 ITrShftLvrPosV "TrShftLvrPosV";
BA_ "CompuMethodName" SG_ 404 ITrEstdGear "TrEstdGear";
BA_ "ISignalName" SG_ 404 ITrEstdGear "ITrEstdGear";
BA_ "LongName" SG_ 404 ITrEstdGear "Transmission Estimated Gear";
BA_ "SysSignalName" SG_ 404 ITrEstdGear "TrEstdGear";
BA_ "CompuMethodName" SG_ 404 ITrShftLvrPos "TrShftLvrPos";
BA_ "ISignalName" SG_ 404 ITrShftLvrPos "ITrShftLvrPos";
BA_ "LongName" SG_ 404 ITrShftLvrPos "Transmission_Shift_Lever_Position";
BA_ "SysSignalName" SG_ 404 ITrShftLvrPos "TrShftLvrPos";
BA_ "CompuMethodName" SG_ 404 IRZCU_20ms_Group06_Reserved1 "RZCU_20ms_Group06_Reserved1";
BA_ "GenSigStartValue" SG_ 404 IRZCU_20ms_Group06_Reserved1 31;
BA_ "ISignalName" SG_ 404 IRZCU_20ms_Group06_Reserved1 "IRZCU_20ms_Group06_Reserved1";
BA_ "SysSignalName" SG_ 404 IRZCU_20ms_Group06_Reserved1 "RZCU_20ms_Group06_Reserved1";
BA_ "CompuMethodName" SG_ 404 ITrEngdStaV "TrEngdStaV";
BA_ "ISignalName" SG_ 404 ITrEngdStaV "ITrEngdStaV";
BA_ "LongName" SG_ 404 ITrEngdStaV "Transmission Engaged State Validity_Transmission Control Module";
BA_ "SysSignalName" SG_ 404 ITrEngdStaV "TrEngdStaV";
BA_ "CompuMethodName" SG_ 404 ITrEngdSta "TrEngdSta";
BA_ "ISignalName" SG_ 404 ITrEngdSta "ITrEngdSta";
BA_ "LongName" SG_ 404 ITrEngdSta "Transmission Engaged State_Transmission Control Module";
BA_ "SysSignalName" SG_ 404 ITrEngdSta "TrEngdSta";
BA_ "CompuMethodName" SG_ 404 IRZCU_20ms_Group06_Reserved2 "RZCU_20ms_Group06_Reserved2";
BA_ "GenSigStartValue" SG_ 404 IRZCU_20ms_Group06_Reserved2 255;
BA_ "ISignalName" SG_ 404 IRZCU_20ms_Group06_Reserved2 "IRZCU_20ms_Group06_Reserved2";
BA_ "SysSignalName" SG_ 404 IRZCU_20ms_Group06_Reserved2 "RZCU_20ms_Group06_Reserved2";
BA_ "CompuMethodName" SG_ 404 IRZCU_20ms_Group06_Reserved3 "RZCU_20ms_Group06_Reserved3";
BA_ "GenSigStartValue" SG_ 404 IRZCU_20ms_Group06_Reserved3 255;
BA_ "ISignalName" SG_ 404 IRZCU_20ms_Group06_Reserved3 "IRZCU_20ms_Group06_Reserved3";
BA_ "SysSignalName" SG_ 404 IRZCU_20ms_Group06_Reserved3 "RZCU_20ms_Group06_Reserved3";
BA_ "CompuMethodName" SG_ 404 IRZCU_20ms_Group06_Reserved4 "RZCU_20ms_Group06_Reserved4";
BA_ "GenSigStartValue" SG_ 404 IRZCU_20ms_Group06_Reserved4 255;
BA_ "ISignalName" SG_ 404 IRZCU_20ms_Group06_Reserved4 "IRZCU_20ms_Group06_Reserved4";
BA_ "SysSignalName" SG_ 404 IRZCU_20ms_Group06_Reserved4 "RZCU_20ms_Group06_Reserved4";
BA_ "CompuMethodName" SG_ 404 IRZCU_20ms_Group06_Reserved5 "RZCU_20ms_Group06_Reserved5";
BA_ "GenSigStartValue" SG_ 404 IRZCU_20ms_Group06_Reserved5 255;
BA_ "ISignalName" SG_ 404 IRZCU_20ms_Group06_Reserved5 "IRZCU_20ms_Group06_Reserved5";
BA_ "SysSignalName" SG_ 404 IRZCU_20ms_Group06_Reserved5 "RZCU_20ms_Group06_Reserved5";
BA_ "CompuMethodName" SG_ 404 IEPTRunCrkTrmlSts "EPTRunCrkTrmlSts";
BA_ "ISignalName" SG_ 404 IEPTRunCrkTrmlSts "IEPTRunCrkTrmlSts";
BA_ "LongName" SG_ 404 IEPTRunCrkTrmlSts "Electric Powertrian Run Crank Terminal State";
BA_ "SysSignalName" SG_ 404 IEPTRunCrkTrmlSts "EPTRunCrkTrmlSts";
BA_ "CompuMethodName" SG_ 404 IEPTSimEnSpd "EPTSimEnSpd";
BA_ "ISignalName" SG_ 404 IEPTSimEnSpd "IEPTSimEnSpd";
BA_ "LongName" SG_ 404 IEPTSimEnSpd "Electric Powertrain Simulaiton Engine Speed";
BA_ "SysSignalName" SG_ 404 IEPTSimEnSpd "EPTSimEnSpd";
BA_ "CompuMethodName" SG_ 404 IVMCLvlCtrlAdjActn "VMCLvlCtrlAdjActn";
BA_ "ISignalName" SG_ 404 IVMCLvlCtrlAdjActn "IVMCLvlCtrlAdjActn";
BA_ "LongName" SG_ 404 IVMCLvlCtrlAdjActn "Level Control Adjustment Action";
BA_ "SysSignalName" SG_ 404 IVMCLvlCtrlAdjActn "VMCLvlCtrlAdjActn";
BA_ "CompuMethodName" SG_ 404 ISecyAxleSts "SecyAxleSts";
BA_ "ISignalName" SG_ 404 ISecyAxleSts "ISecyAxleSts";
BA_ "LongName" SG_ 404 ISecyAxleSts "Secondary Axle Status";
BA_ "SysSignalName" SG_ 404 ISecyAxleSts "SecyAxleSts";
BA_ "CompuMethodName" SG_ 180 IRZCU_10ms_Group01_CRC "RZCU_10ms_Group01_CRC";
BA_ "ISignalName" SG_ 180 IRZCU_10ms_Group01_CRC "IRZCU_10ms_Group01_CRC";
BA_ "SysSignalName" SG_ 180 IRZCU_10ms_Group01_CRC "RZCU_10ms_Group01_CRC";
BA_ "CompuMethodName" SG_ 180 IRZCU_10ms_Group01_RC "RZCU_10ms_Group01_RC";
BA_ "ISignalName" SG_ 180 IRZCU_10ms_Group01_RC "IRZCU_10ms_Group01_RC";
BA_ "SysSignalName" SG_ 180 IRZCU_10ms_Group01_RC "RZCU_10ms_Group01_RC";
BA_ "CompuMethodName" SG_ 180 IElecMotEmgcShutDwn "ElecMotEmgcShutDwn";
BA_ "ISignalName" SG_ 180 IElecMotEmgcShutDwn "IElecMotEmgcShutDwn";
BA_ "LongName" SG_ 180 IElecMotEmgcShutDwn "Electric_Motor_Emergency_Shut_Down";
BA_ "SysSignalName" SG_ 180 IElecMotEmgcShutDwn "ElecMotEmgcShutDwn";
BA_ "CompuMethodName" SG_ 180 IEPTHVEmgcPwrOffReq "EPTHVEmgcPwrOffReq";
BA_ "ISignalName" SG_ 180 IEPTHVEmgcPwrOffReq "IEPTHVEmgcPwrOffReq";
BA_ "LongName" SG_ 180 IEPTHVEmgcPwrOffReq "Electric_Powertrain_High_Voltage_Emergency_Power_Off_Request";
BA_ "SysSignalName" SG_ 180 IEPTHVEmgcPwrOffReq "EPTHVEmgcPwrOffReq";
BA_ "CompuMethodName" SG_ 180 IEPTMainRelayDrvReq "EPTMainRelayDrvReq";
BA_ "ISignalName" SG_ 180 IEPTMainRelayDrvReq "IEPTMainRelayDrvReq";
BA_ "LongName" SG_ 180 IEPTMainRelayDrvReq "Electric_Powertrain_Main_Relay_Drive_Request";
BA_ "SysSignalName" SG_ 180 IEPTMainRelayDrvReq "EPTMainRelayDrvReq";
BA_ "CompuMethodName" SG_ 180 IEPTStCmdOn "EPTStCmdOn";
BA_ "ISignalName" SG_ 180 IEPTStCmdOn "IEPTStCmdOn";
BA_ "LongName" SG_ 180 IEPTStCmdOn "Electric Powertrain Start Command On";
BA_ "SysSignalName" SG_ 180 IEPTStCmdOn "EPTStCmdOn";
BA_ "CompuMethodName" SG_ 180 IEPTAccelActuPosV "EPTAccelActuPosV";
BA_ "ISignalName" SG_ 180 IEPTAccelActuPosV "IEPTAccelActuPosV";
BA_ "LongName" SG_ 180 IEPTAccelActuPosV "Electric_Powertrain_Accelerator_Actual_Position_Validity";
BA_ "SysSignalName" SG_ 180 IEPTAccelActuPosV "EPTAccelActuPosV";
BA_ "CompuMethodName" SG_ 180 IAutoChrgngMngmnt "AutoChrgngMngmnt";
BA_ "ISignalName" SG_ 180 IAutoChrgngMngmnt "IAutoChrgngMngmnt";
BA_ "LongName" SG_ 180 IAutoChrgngMngmnt "Auto Charging Management";
BA_ "SysSignalName" SG_ 180 IAutoChrgngMngmnt "AutoChrgngMngmnt";
BA_ "CompuMethodName" SG_ 180 IEPTBrkPdlDscrtInptStsV "EPTBrkPdlDscrtInptStsV";
BA_ "ISignalName" SG_ 180 IEPTBrkPdlDscrtInptStsV "IEPTBrkPdlDscrtInptStsV";
BA_ "LongName" SG_ 180 IEPTBrkPdlDscrtInptStsV "Electric_Powertrain_Brake_Pedal_Discrete_Input_Status_Validity";
BA_ "SysSignalName" SG_ 180 IEPTBrkPdlDscrtInptStsV "EPTBrkPdlDscrtInptStsV";
BA_ "CompuMethodName" SG_ 180 IEPTBrkPdlDscrtInptSts "EPTBrkPdlDscrtInptSts";
BA_ "ISignalName" SG_ 180 IEPTBrkPdlDscrtInptSts "IEPTBrkPdlDscrtInptSts";
BA_ "LongName" SG_ 180 IEPTBrkPdlDscrtInptSts "Electric_Powertrain_Brake_Pedal_Discrete_Input_Status";
BA_ "SysSignalName" SG_ 180 IEPTBrkPdlDscrtInptSts "EPTBrkPdlDscrtInptSts";
BA_ "CompuMethodName" SG_ 180 IRVSEPTRdy "RVSEPTRdy";
BA_ "ISignalName" SG_ 180 IRVSEPTRdy "IRVSEPTRdy";
BA_ "LongName" SG_ 180 IRVSEPTRdy "Remote_Vehicle_Start_Electric_Powertrain_Ready";
BA_ "SysSignalName" SG_ 180 IRVSEPTRdy "RVSEPTRdy";
BA_ "CompuMethodName" SG_ 180 IEPTCrkAbotd "EPTCrkAbotd";
BA_ "ISignalName" SG_ 180 IEPTCrkAbotd "IEPTCrkAbotd";
BA_ "LongName" SG_ 180 IEPTCrkAbotd "Electric_Powertrain_Crank_Aborted";
BA_ "SysSignalName" SG_ 180 IEPTCrkAbotd "EPTCrkAbotd";
BA_ "CompuMethodName" SG_ 180 IRZCU_10ms_Group01_Reserved1 "RZCU_10ms_Group01_Reserved1";
BA_ "GenSigStartValue" SG_ 180 IRZCU_10ms_Group01_Reserved1 31;
BA_ "ISignalName" SG_ 180 IRZCU_10ms_Group01_Reserved1 "IRZCU_10ms_Group01_Reserved1";
BA_ "SysSignalName" SG_ 180 IRZCU_10ms_Group01_Reserved1 "RZCU_10ms_Group01_Reserved1";
BA_ "CompuMethodName" SG_ 180 IEPTHVDCDCMdReq "EPTHVDCDCMdReq";
BA_ "ISignalName" SG_ 180 IEPTHVDCDCMdReq "IEPTHVDCDCMdReq";
BA_ "LongName" SG_ 180 IEPTHVDCDCMdReq "Electric_Powertrain_High_Voltage_Direct_Current_Direct_Current_Mode_Request";
BA_ "SysSignalName" SG_ 180 IEPTHVDCDCMdReq "EPTHVDCDCMdReq";
BA_ "CompuMethodName" SG_ 180 IEPTAccelActuPos "EPTAccelActuPos";
BA_ "ISignalName" SG_ 180 IEPTAccelActuPos "IEPTAccelActuPos";
BA_ "LongName" SG_ 180 IEPTAccelActuPos "Electric_Powertrain_Accelerator_Actual_Position";
BA_ "SysSignalName" SG_ 180 IEPTAccelActuPos "EPTAccelActuPos";
BA_ "CompuMethodName" SG_ 180 IEPTAccelEfctvPos "EPTAccelEfctvPos";
BA_ "ISignalName" SG_ 180 IEPTAccelEfctvPos "IEPTAccelEfctvPos";
BA_ "LongName" SG_ 180 IEPTAccelEfctvPos "Electric_Powertrain_Accelerator_Effective_Position";
BA_ "SysSignalName" SG_ 180 IEPTAccelEfctvPos "EPTAccelEfctvPos";
BA_ "CompuMethodName" SG_ 180 IRZCU_10ms_Group01_Reserved2 "RZCU_10ms_Group01_Reserved2";
BA_ "GenSigStartValue" SG_ 180 IRZCU_10ms_Group01_Reserved2 255;
BA_ "ISignalName" SG_ 180 IRZCU_10ms_Group01_Reserved2 "IRZCU_10ms_Group01_Reserved2";
BA_ "SysSignalName" SG_ 180 IRZCU_10ms_Group01_Reserved2 "RZCU_10ms_Group01_Reserved2";
BA_ "CompuMethodName" SG_ 180 IRZCU_10ms_Group01_Reserved3 "RZCU_10ms_Group01_Reserved3";
BA_ "GenSigStartValue" SG_ 180 IRZCU_10ms_Group01_Reserved3 255;
BA_ "ISignalName" SG_ 180 IRZCU_10ms_Group01_Reserved3 "IRZCU_10ms_Group01_Reserved3";
BA_ "SysSignalName" SG_ 180 IRZCU_10ms_Group01_Reserved3 "RZCU_10ms_Group01_Reserved3";
BA_ "CompuMethodName" SG_ 180 IRZCU_10ms_Group02_CRC "RZCU_10ms_Group02_CRC";
BA_ "ISignalName" SG_ 180 IRZCU_10ms_Group02_CRC "IRZCU_10ms_Group02_CRC";
BA_ "SysSignalName" SG_ 180 IRZCU_10ms_Group02_CRC "RZCU_10ms_Group02_CRC";
BA_ "CompuMethodName" SG_ 180 IRZCU_10ms_Group02_RC "RZCU_10ms_Group02_RC";
BA_ "ISignalName" SG_ 180 IRZCU_10ms_Group02_RC "IRZCU_10ms_Group02_RC";
BA_ "SysSignalName" SG_ 180 IRZCU_10ms_Group02_RC "RZCU_10ms_Group02_RC";
BA_ "CompuMethodName" SG_ 180 IEPTTrInptShaftSpdV_R "EPTTrInptShaftSpdV_R";
BA_ "ISignalName" SG_ 180 IEPTTrInptShaftSpdV_R "IEPTTrInptShaftSpdV_R";
BA_ "LongName" SG_ 180 IEPTTrInptShaftSpdV_R "Electric_Powertrain_Transmission_Input_Shaft_Speed_Valid_Right";
BA_ "SysSignalName" SG_ 180 IEPTTrInptShaftSpdV_R "EPTTrInptShaftSpdV_R";
BA_ "CompuMethodName" SG_ 180 IRZCU_10ms_Group02_Reserved1 "RZCU_10ms_Group02_Reserved1";
BA_ "GenSigStartValue" SG_ 180 IRZCU_10ms_Group02_Reserved1 1;
BA_ "ISignalName" SG_ 180 IRZCU_10ms_Group02_Reserved1 "IRZCU_10ms_Group02_Reserved1";
BA_ "SysSignalName" SG_ 180 IRZCU_10ms_Group02_Reserved1 "RZCU_10ms_Group02_Reserved1";
BA_ "CompuMethodName" SG_ 180 IEPTTrInptShaftSpdV "EPTTrInptShaftSpdV";
BA_ "ISignalName" SG_ 180 IEPTTrInptShaftSpdV "IEPTTrInptShaftSpdV";
BA_ "LongName" SG_ 180 IEPTTrInptShaftSpdV "Electric_Powertrain_Transmission_Input_Shaft_Speed_Validity";
BA_ "SysSignalName" SG_ 180 IEPTTrInptShaftSpdV "EPTTrInptShaftSpdV";
BA_ "CompuMethodName" SG_ 180 IEPTSecyAxleInptShaftSpdV "EPTSecyAxleInptShaftSpdV";
BA_ "ISignalName" SG_ 180 IEPTSecyAxleInptShaftSpdV "IEPTSecyAxleInptShaftSpdV";
BA_ "LongName" SG_ 180 IEPTSecyAxleInptShaftSpdV "Electric_Powertrain_Secondary_Axle_Input_Shaft_Speed_Validity";
BA_ "SysSignalName" SG_ 180 IEPTSecyAxleInptShaftSpdV "EPTSecyAxleInptShaftSpdV";
BA_ "CompuMethodName" SG_ 180 IEPTSecyAxleInptShaftSpd "EPTSecyAxleInptShaftSpd";
BA_ "GenSigStartValue" SG_ 180 IEPTSecyAxleInptShaftSpd 32767;
BA_ "ISignalName" SG_ 180 IEPTSecyAxleInptShaftSpd "IEPTSecyAxleInptShaftSpd";
BA_ "LongName" SG_ 180 IEPTSecyAxleInptShaftSpd "Electric_Powertrain_Secondary_Axle_Input_Shaft_Speed";
BA_ "SysSignalName" SG_ 180 IEPTSecyAxleInptShaftSpd "EPTSecyAxleInptShaftSpd";
BA_ "CompuMethodName" SG_ 180 IEPTTrInptShaftSpd "EPTTrInptShaftSpd";
BA_ "GenSigStartValue" SG_ 180 IEPTTrInptShaftSpd 32767;
BA_ "ISignalName" SG_ 180 IEPTTrInptShaftSpd "IEPTTrInptShaftSpd";
BA_ "LongName" SG_ 180 IEPTTrInptShaftSpd "Electric_Powertrain_Transmission_Input_Shaft_Speed";
BA_ "SysSignalName" SG_ 180 IEPTTrInptShaftSpd "EPTTrInptShaftSpd";
BA_ "CompuMethodName" SG_ 180 IEPTTrInptShaftSpd_R "EPTTrInptShaftSpd_R";
BA_ "GenSigStartValue" SG_ 180 IEPTTrInptShaftSpd_R 32767;
BA_ "ISignalName" SG_ 180 IEPTTrInptShaftSpd_R "IEPTTrInptShaftSpd_R";
BA_ "LongName" SG_ 180 IEPTTrInptShaftSpd_R "Electric_Powertrain_Transmission_Input_Shaft_Speed_Right";
BA_ "SysSignalName" SG_ 180 IEPTTrInptShaftSpd_R "EPTTrInptShaftSpd_R";
VAL_ 777 IOfbdChrgRelaySts 0 "OfbdChrgRelaySts_0_Open" 1 "OfbdChrgRelaySts_1_Closed" 2 "OfbdChrgRelaySts_2_Failure";
VAL_ 777 IEleccLckCtrlResp 0 "EleccLckCtrlResp_0_Default" 1 "EleccLckCtrlResp_1_Command_Executed_Successful" 2 "EleccLckCtrlResp_2_Failed";
VAL_ 777 IOnbdChrgrSktEleccLckEnable 0 "OnbdChrgrSktEleccLckEnable_0_Default" 1 "OnbdChrgrSktEleccLckEnable_1_Locked" 2 "OnbdChrgrSktEleccLckEnable_2_Unlocked";
VAL_ 777 IOnBdChrgrSktPstvSnsrTemV 0 "OnBdChrgrSktPstvSnsrTemV_0_Valid" 1 "OnBdChrgrSktPstvSnsrTemV_1_Invalid";
VAL_ 777 IOfbdChrgrNgtvSktTemV 0 "OfbdChrgrNgtvSktTemV_0_Valid" 1 "OfbdChrgrNgtvSktTemV_1_Invalid";
VAL_ 777 IOfbdChrgrWkup 0 "OfbdChrgrWkup_0_False" 1 "OfbdChrgrWkup_1_True";
VAL_ 777 IFlbStrgFnStsResp 0 "FlbStrgFnStsResp_0_Off" 1 "FlbStrgFnStsResp_1_Standby" 2 "FlbStrgFnStsResp_2_Active" 3 "FlbStrgFnStsResp_3_Disable";
VAL_ 777 IOfbdRelayWeldFlt 0 "OfbdRelayWeldFlt_0_NoFailure" 1 "OfbdRelayWeldFlt_1_Failure";
VAL_ 777 IIMU_Signal_status 0 "IMUSignalStatus_0_Normal" 1 "IMUSignalStatus_1_Failure" 2 "IMUSignalStatus_2_Resved" 3 "IMUSignalStatus_3_Resved" 4 "IMUSignalStatus_4_Resved" 5 "IMUSignalStatus_5_Resved" 6 "IMUSignalStatus_6_Resved" 7 "IMUSignalStatus_7_Resved";
VAL_ 777 IVCUCtrlS2Req 0 "VCUCtrlS2Req_0_Default" 1 "VCUCtrlS2Req_1_Close_Request" 2 "VCUCtrlS2Req_2_Open_Request";
VAL_ 777 IOfbdChrgRelayStsV 0 "OfbdChrgRelayStsV_0_Valid" 1 "OfbdChrgRelayStsV_1_Invalid";
VAL_ 777 ICstRgtnBrkLgtReq 0 "CstRgtnBrkLgtReq_0_NoRequest" 1 "CstRgtnBrkLgtReq_1_Request";
VAL_ 777 ICstRgtnBrkLgtReqV 0 "CstRgtnBrkLgtReqV_0_Valid" 1 "CstRgtnBrkLgtReqV_1_Invalid";
VAL_ 777 IOnBdChrgrSktElecLckStaV 0 "OnBdChrgrSktElecLckStaV_0_Valid" 1 "OnBdChrgrSktElecLckStaV_1_Invalid";
VAL_ 777 IOnBdChrgrSktElecLckSta 0 "OnBdChrgrSktElecLckSta_0_Unlocked" 1 "OnBdChrgrSktElecLckSta_1_Locked" 2 "OnBdChrgrSktElecLckSta_2_ControlLineFailure" 3 "OnBdChrgrSktElecLckSta_3_FeedbackError";
VAL_ 1267 IRZCU_NM_BSMtoRMS_PTCANFD 0 "RZCU_NM_BSMtoRMS_PTCANFD_0_False" 1 "RZCU_NM_BSMtoRMS_PTCANFD_1_True";
VAL_ 1267 IRZCU_NM_PBSMtoRMS_PTCANFD 0 "RZCU_NM_PBSMtoRMS_PTCANFD_0_False" 1 "RZCU_NM_PBSMtoRMS_PTCANFD_1_True";
VAL_ 1267 IRZCU_NM_RMStoNOS_PTCANFD 0 "RZCU_NM_RMStoNOS_PTCANFD_0_False" 1 "RZCU_NM_RMStoNOS_PTCANFD_1_True";
VAL_ 1267 IRZCU_NM_RSStoNOS_PTCANFD 0 "RZCU_NM_RSStoNOS_PTCANFD_0_False" 1 "RZCU_NM_RSStoNOS_PTCANFD_1_True";
VAL_ 1267 IRZCU_NM_RSStoRMS_PTCANFD 0 "RZCU_NM_RSStoRMS_PTCANFD_0_False" 1 "RZCU_NM_RSStoRMS_PTCANFD_1_True";
VAL_ 1267 IRZCU_NM_NOStoRMS_PTCANFD 0 "RZCU_NM_NOStoRMS_PTCANFD_0_False" 1 "RZCU_NM_NOStoRMS_PTCANFD_1_True";
VAL_ 1267 IRZCU_NM_NOSSta_PTCANFD 0 "RZCU_NM_NOSSta_PTCANFD_0_False" 1 "RZCU_NM_NOSSta_PTCANFD_1_True";
VAL_ 1267 IRZCU_NM_RMSSta_PTCANFD 0 "RZCU_NM_RMSSta_PTCANFD_0_False" 1 "RZCU_NM_RMSSta_PTCANFD_1_True";
VAL_ 1267 IRZCU_NWI_PTCANFD 0 "RZCU_NWI_PTCANFD_0_NoWakeNetworkSource" 1 "RZCU_NWI_PTCANFD_1_PowerModeIsRuncrank" 2 "RZCU_NWI_PTCANFD_2_ThermalFaultActive" 5 "RZCU_NWI_PTCANFD_5_OffboardChargerConnected" 8 "RZCU_NWI_PTCANFD_8_PLGOpenDetectByPriMarySwitch" 9 "RZCU_NWI_PTCANFD_9_PLGCloseDetectByPriMarySwitch" 10 "RZCU_NWI_PTCANFD_10_PLGOpenDetectBySecondarySwitch" 12 "RZCU_NWI_PTCANFD_12_PwrlftgtCloseRequest" 15 "RZCU_NWI_PTCANFD_15_EasyLdSwthReqRequest" 16 "RZCU_NWI_PTCANFD_16_ChrgFlapDoorAjarSwActive" 17 "RZCU_NWI_PTCANFD_17_RrSeatBrkSwActive";
VAL_ 1267 IRZCU_NOI_PTCANFD 0 "RZCU_NOI_PTCANFD_0_NoRequest" 65535 "RZCU_NOI_PTCANFD_65535_AllNetworkOperationActive";
VAL_ 1267 IRZCU_NKI_PTCANFD 0 "RZCU_NKI_PTCANFD_0_NoRequest" 1 "RZCU_NKI_PTCANFD_1_PowerModeIsNonOFF" 2 "RZCU_NKI_PTCANFD_2_ThermalFaultActive" 16 "RZCU_NKI_PTCANFD_16_HVBulid" 256 "RZCU_NKI_PTCANFD_256_RWSActive" 512 "RZCU_NKI_PTCANFD_512_ChargerFlapTimeWindow" 1024 "RZCU_NKI_PTCANFD_1024_EasyLdSwthReqRequest";
VAL_ 247 IEPTTrOtptShaftTotMinAvlblToqV 0 "EPTTrOtptShaftTotMinAvlblToqV_0_Valid" 1 "EPTTrOtptShaftTotMinAvlblToqV_1_Invalid";
VAL_ 247 IEPTTrOtptShaftTotMaxAvlblToqV 0 "EPTTrOtptShaftTotMaxAvlblToqV_0_Valid" 1 "EPTTrOtptShaftTotMaxAvlblToqV_1_Invalid";
VAL_ 247 IEPTTrOtptShaftTotToqV 0 "EPTTrOtptShaftTotToqV_0_Valid" 1 "EPTTrOtptShaftTotToqV_1_Invalid";
VAL_ 225 IAutodDrvngToqReqResp 0 "AutodDrvngToqReqResp_0_no_request" 1 "AutodDrvngToqReqResp_1_request_hornored" 2 "AutodDrvngToqReqResp_2_lost_arbitration" 3 "AutodDrvngToqReqResp_3_control_request_not_allow_for_error" 4 "AutodDrvngToqReqResp_4_precondition_not_satisfied";
VAL_ 225 IPtACCToqReqResp 0 "PtACCToqReqResp_0_NoRequest" 1 "PtACCToqReqResp_1_RequestHonored" 2 "PtACCToqReqResp_2_LostArbitration" 3 "PtACCToqReqResp_3_ControlNotAllowedForError" 4 "PtACCToqReqResp_4_Pre_conditionNotSatisfied" 5 "PtACCToqReqResp_5_reserved" 6 "PtACCToqReqResp_6_reserved" 7 "PtACCToqReqResp_7_reserved";
VAL_ 225 IAIPilotSysSaBrSts 0 "AIPilotSysSaBrSts_0__0" 1 "AIPilotSysSaBrSts_1__1" 2 "AIPilotSysSaBrSts_2__2" 3 "AIPilotSysSaBrSts_3__3" 4 "AIPilotSysSaBrSts_4__4" 5 "AIPilotSysSaBrSts_5__5" 6 "AIPilotSysSaBrSts_6__6" 7 "AIPilotSysSaBrSts_7__7" 8 "AIPilotSysSaBrSts_8__8" 9 "AIPilotSysSaBrSts_9__9" 10 "AIPilotSysSaBrSts_10__10" 11 "AIPilotSysSaBrSts_11__11" 12 "AIPilotSysSaBrSts_12__12" 13 "AIPilotSysSaBrSts_13__13" 14 "AIPilotSysSaBrSts_14__14" 15 "AIPilotSysSaBrSts_15__15";
VAL_ 225 IAIPilotSysSaBrInh 0 "AIPilotSysSaBrInh_0__0" 1 "AIPilotSysSaBrInh_1__1" 2 "AIPilotSysSaBrInh_2__2" 3 "AIPilotSysSaBrInh_3__3" 4 "AIPilotSysSaBrInh_4__4" 5 "AIPilotSysSaBrInh_5__5" 6 "AIPilotSysSaBrInh_6__6" 7 "AIPilotSysSaBrInh_7__7" 8 "AIPilotSysSaBrInh_8__8" 9 "AIPilotSysSaBrInh_9__9" 10 "AIPilotSysSaBrInh_10__10" 11 "AIPilotSysSaBrInh_11__11" 12 "AIPilotSysSaBrInh_12__12" 13 "AIPilotSysSaBrInh_13__13" 14 "AIPilotSysSaBrInh_14__14" 15 "AIPilotSysSaBrInh_15__15";
VAL_ 225 IAccelOvrd 0 "AccelOvrd_0_False" 1 "AccelOvrd_1_True";
VAL_ 1266 ITC_NM_BSMtoRMS_PTCANFD 0 "TC_NM_BSMtoRMS_PTCANFD_0_TC_NM_BSMtoRMS_0_False" 1 "TC_NM_BSMtoRMS_PTCANFD_1_TC_NM_BSMtoRMS_1_True";
VAL_ 1266 ITC_NM_PBSMtoRMS_PTCANFD 0 "TC_NM_PBSMtoRMS_PTCANFD_0_TC_NM_PBSMtoRMS_0_False" 1 "TC_NM_PBSMtoRMS_PTCANFD_1_TC_NM_PBSMtoRMS_1_True";
VAL_ 1266 ITC_NM_RMStoNOS_PTCANFD 0 "TC_NM_RMStoNOS_PTCANFD_0_TC_NM_RMStoNOS_0_False" 1 "TC_NM_RMStoNOS_PTCANFD_1_TC_NM_RMStoNOS_1_True";
VAL_ 1266 ITC_NM_RSStoNOS_PTCANFD 0 "TC_NM_RSStoNOS_PTCANFD_0_TC_NM_RSStoNOS_0_False" 1 "TC_NM_RSStoNOS_PTCANFD_1_TC_NM_RSStoNOS_1_True";
VAL_ 1266 ITC_NM_RSStoRMS_PTCANFD 0 "TC_NM_RSStoRMS_PTCANFD_0_TC_NM_RSStoRMS_0_False" 1 "TC_NM_RSStoRMS_PTCANFD_1_TC_NM_RSStoRMS_1_True";
VAL_ 1266 ITC_NM_NOStoRMS_PTCANFD 0 "TC_NM_NOStoRMS_PTCANFD_0_TC_NM_NOStoRMS_0_False" 1 "TC_NM_NOStoRMS_PTCANFD_1_TC_NM_NOStoRMS_1_True";
VAL_ 1266 ITC_NM_NOSSta_PTCANFD 0 "TC_NM_NOSSta_PTCANFD_0_TC_NM_NOSSta_0_False" 1 "TC_NM_NOSSta_PTCANFD_1_TC_NM_NOSSta_1_True";
VAL_ 1266 ITC_NM_RMSSta_PTCANFD 0 "TC_NM_RMSSta_PTCANFD_0_TC_NM_RMSSta_0_False" 1 "TC_NM_RMSSta_PTCANFD_1_TC_NM_RMSSta_1_True";
VAL_ 1266 ITC_NWI_PTCANFD 0 "TC_NWI_PTCANFD_0_NoWakeNetworkSource";
VAL_ 1266 ITC_NOI_PTCANFD 0 "TC_NOI_PTCANFD_0_NoRequest" 65535 "TC_NOI_PTCANFD_65535_AllNetworkOperationActive";
VAL_ 1266 ITC_NKI_PTCANFD 0 "TC_NKI_PTCANFD_0_NoRequest" 1 "TC_NKI_PTCANFD_1_PowerModeIsNonOFF" 2 "TC_NKI_PTCANFD_2_EOPCAfterRun";
VAL_ 1216 IZXD_NM_BSMtoRMS_PTCANFD 0 "ZXD_NM_BSMtoRMS_PTCANFD_0_False" 1 "ZXD_NM_BSMtoRMS_PTCANFD_1_True";
VAL_ 1216 IZXD_NM_PBSMtoRMS_PTCANFD 0 "ZXD_NM_PBSMtoRMS_PTCANFD_0_False" 1 "ZXD_NM_PBSMtoRMS_PTCANFD_1_True";
VAL_ 1216 IZXD_NM_RMStoNOS_PTCANFD 0 "ZXD_NM_RMStoNOS_PTCANFD_0_False" 1 "ZXD_NM_RMStoNOS_PTCANFD_1_True";
VAL_ 1216 IZXD_NM_RSStoNOS_PTCANFD 0 "ZXD_NM_RSStoNOS_PTCANFD_0_False" 1 "ZXD_NM_RSStoNOS_PTCANFD_1_True";
VAL_ 1216 IZXD_NM_RSStoRMS_PTCANFD 0 "ZXD_NM_RSStoRMS_PTCANFD_0_False" 1 "ZXD_NM_RSStoRMS_PTCANFD_1_True";
VAL_ 1216 IZXD_NM_NOStoRMS_PTCANFD 0 "ZXD_NM_NOStoRMS_PTCANFD_0_False" 1 "ZXD_NM_NOStoRMS_PTCANFD_1_True";
VAL_ 1216 IZXD_NM_NOSSta_PTCANFD 0 "ZXD_NM_NOSSta_PTCANFD_0_False" 1 "ZXD_NM_NOSSta_PTCANFD_1_True";
VAL_ 1216 IZXD_NM_RMSSta_PTCANFD 0 "ZXD_NM_RMSSta_PTCANFD_0_False" 1 "ZXD_NM_RMSSta_PTCANFD_1_True";
VAL_ 1216 IZXD_NWI_PTCANFD 0 "ZXD_NWI_PTCANFD_0_NoWakeNetworkSource" 1 "ZXD_NWI_PTCANFD_1_PowerModeIsNonOFF";
VAL_ 1216 IZXD_NOI_PTCANFD 0 "ZXD_NOI_PTCANFD_0_NoRequest" 65535 "ZXD_NOI_PTCANFD_65535_AllNetworkOperationActive";
VAL_ 1216 IZXD_NKI_PTCANFD 0 "ZXD_NKI_PTCANFD_0_NoRequest" 1 "ZXD_NKI_PTCANFD_1_PowerModeIsNonOFF";
VAL_ 769 IBMSEmsnRltdMalfA 0 "BMSEmsnRltdMalfA_0_False" 1 "BMSEmsnRltdMalfA_1_True";
VAL_ 769 IBMSOdoFctV 0 "BMSOdoFctV_0_Valid" 1 "BMSOdoFctV_1_Invalid";
VAL_ 769 IBMSStdAvlblEnrgV 0 "BMSStdAvlblEnrgV_0_Valid" 1 "BMSStdAvlblEnrgV_1_Invalid";
VAL_ 769 IBMSChrgTrgtStdAvlblEnrgV 0 "BMSChrgTrgtStdAvlblEnrgV_0_Valid" 1 "BMSChrgTrgtStdAvlblEnrgV_1_Invalid";
VAL_ 769 IBMSDisTrgtStdAvlblEnrgV 0 "BMSDisTrgtStdAvlblEnrgV_0_Valid" 1 "BMSDisTrgtStdAvlblEnrgV_1_Invalid";
VAL_ 769 IBMSPosPtIsltnRstcV 0 "BMSPosPtIsltnRstcV_0_Valid" 1 "BMSPosPtIsltnRstcV_1_Invalid";
VAL_ 769 IBMSNegPtIsltnRstcV 0 "BMSNegPtIsltnRstcV_0_Valid" 1 "BMSNegPtIsltnRstcV_1_Invalid";
VAL_ 769 IBMSStaOfHealthResi 254 "BMSStaOfHealthResi_254_Init" 255 "BMSStaOfHealthResi_255_Error";
VAL_ 769 IBMSStaOfHealthCapct 254 "BMSStaOfHealthCapct_254_Init" 255 "BMSStaOfHealthCapct_255_Error";
VAL_ 769 IBMSOnbdChrgSpRsn 0 "BMSOnbdChrgSpRsn_0_None" 1 "BMSOnbdChrgSpRsn_1_ChargerSatusAbnormal" 2 "BMSOnbdChrgSpRsn_2_ChargerPortOverTemperature" 3 "BMSOnbdChrgSpRsn_3_ChargingGunNotProperlyPluggedIn" 4 "BMSOnbdChrgSpRsn_4_ChargerVoltageMismatch";
VAL_ 769 IBMSPackSOH 1022 "BMSPackSOH_1022_Init" 1023 "BMSPackSOH_1023_Error";
VAL_ 769 IBMSFltLamp 0 "BMSFltLamp_0_No_lamp" 1 "BMSFltLamp_1_Yellow_Lamp" 2 "BMSFltLamp_2_Red_Lamp" 3 "BMSFltLamp_3_Flashing_Yellow_Lamp" 4 "BMSFltLamp_4_Flashing_Red_Lamp" 5 "BMSFltLamp_5_Reservered1" 6 "BMSFltLamp_6_Reservered2" 7 "BMSFltLamp_7_Reservered3";
VAL_ 769 IHVBatShutOff 0 "HVBatShutOff_0_False" 1 "HVBatShutOff_1_True";
VAL_ 769 IHVBatSOCHiResV 0 "HVBatSOCHiResV_0_Valid" 1 "HVBatSOCHiResV_1_Invalid";
VAL_ 769 IBMSOfbdChrgrSktVolV 0 "BMSOfbdChrgrSktVolV_0_Valid" 1 "BMSOfbdChrgrSktVolV_1_Invalid";
VAL_ 769 IBMSOffBdChrgrPlugOn 0 "BMSOffBdChrgrPlugOn_0_Disconnected" 1 "BMSOffBdChrgrPlugOn_1_Connected" 2 "BMSOffBdChrgrPlugOn_2_Semi_connected" 3 "BMSOffBdChrgrPlugOn_3_Abnormal_connected";
VAL_ 769 IBMSOffBdChrgrPlugOnV 0 "BMSOffBdChrgrPlugOnV_0_Valid" 1 "BMSOffBdChrgrPlugOnV_1_Invalid";
VAL_ 769 IBMSOfbdChrgrWkup 0 "BMSOfbdChrgrWkup_0_False" 1 "BMSOfbdChrgrWkup_1_True";
VAL_ 548 IVehElecRngDspCmd 0 "VehElecRngDspCmd_0_Default" 1 "VehElecRngDspCmd_1_HvbatYellowLightOnWordsRemind" 2 "VehElecRngDspCmd_2_HvbatYellowLightFlashingWordsRemind" 3 "VehElecRngDspCmd_3_HvbatYellowLightFlashingWordsRemindNotDisplayVehicleElectricalRange";
VAL_ 548 IElecDrvRngPerKwhV 0 "DrvRngPerKwhV_0_Valid" 1 "DrvRngPerKwhV_1_Invalid";
VAL_ 548 IVehElecRngV 0 "VehElecRngV_0_valid" 1 "VehElecRngV_1_NotValid";
VAL_ 548 IBMSOfbdChrgrMaxOtptVolV 0 "BMSOfbdChrgrMaxOtptVolV_0_Valid" 1 "BMSOfbdChrgrMaxOtptVolV_1_Invalid";
VAL_ 548 IBMSOfbdChrgrOtptVolV 0 "BMSOfbdChrgrOtptVolV_0_Valid" 1 "BMSOfbdChrgrOtptVolV_1_Invalid";
VAL_ 548 IBMSOfbdChrgngMd 0 "BMSOfbdChrgngMd_0_Default" 1 "BMSOfbdChrgngMd_1_NotBoostOffboardCharge" 2 "BMSOfbdChrgngMd_2_BoostOffboardCharge";
VAL_ 548 IBMSOfbdChrgrOtptCrnV 0 "BMSOfbdChrgrOtptCrnV_0_Valid" 1 "BMSOfbdChrgrOtptCrnV_1_Invalid";
VAL_ 548 IBMSEnbPTC 0 "BMSEnbPTC_0_Off" 1 "BMSEnbPTC_1_On";
VAL_ 548 IHVOffMoSts 0 "HVOffMoSts_0_Normal_Working_No_Static_Monitoring" 1 "HVOffMoSts_1_IN_Monitoring_Wake_Up" 2 "HVOffMoSts_2_Reserved" 3 "HVOffMoSts_3_Reserved" 4 "HVOffMoSts_4_Reserved" 5 "HVOffMoSts_5_Reserved" 6 "HVOffMoSts_6_Reserved" 7 "HVOffMoSts_7_Reserved";
VAL_ 548 IBMSPTCHeatReqDspCmd 0 "BMSPTCHeatReqDspCmd_0_Default" 1 "BMSPTCHeatReqDspCmd_1_HeatStart" 2 "BMSPTCHeatReqDspCmd_2_HeatStop" 3 "BMSPTCHeatReqDspCmd_3_Reserved";
VAL_ 548 IChrgngRmnngTimeV 0 "ChrgngRmnngTimeV_0_Valid" 1 "ChrgngRmnngTimeV_1_Invalid";
VAL_ 548 IBMSChrgrPlugCnctnIO 0 "BMSChrgrPlugCnctnIO_0_LampOn" 1 "BMSChrgrPlugCnctnIO_1_LampOff";
VAL_ 548 IBMSCumuDschrgEnrgV 0 "BMSCumuDschrgEnrgV_0_Valid" 1 "BMSCumuDschrgEnrgV_1_Invalid";
VAL_ 548 IBMSEleccLckCtrlDspCmd 0 "BMSEleccLckCtrlDspCmd_0_NoRequest" 1 "BMSEleccLckCtrlDspCmd_1_Lock" 2 "BMSEleccLckCtrlDspCmd_2_Unlock" 3 "BMSEleccLckCtrlDspCmd_3_Reserved";
VAL_ 548 IBMSPackSOCCorr 0 "BMSPackSOCCorr_0_default" 1 "BMSPackSOCCorr_1_SOC_correction_Reminder" 2 "BMSPackSOCCorr_2_Force_SOC_Correction" 3 "BMSPackSOCCorr_3_SOC_has_been_corrected";
VAL_ 548 IBMSPTCHeatResp 0 "BMSPTCHeatResp_0_Default" 1 "BMSPTCHeatResp_1_CommandExecutedSuccessful" 2 "BMSPTCHeatResp_2_Failed_BatteryPackHeatingSystemFailure" 3 "BMSPTCHeatResp_3_Failed_NotMeetChargingConditions" 4 "BMSPTCHeatResp_4_Failed_BatteryPackNotNeedToBeHeated" 5 "BMSPTCHeatResp_5_Failed_ReachStopTime" 7 "BMSPTCHeatResp_7_Failed_Others";
VAL_ 548 IBMSNotfnPushReq 0 "BMSNotfnPushReq_0_NoRequest" 1 "BMSNotfnPushReq_1_ChargeSettingUpdate" 2 "BMSNotfnPushReq_2_ChargeReservrtionUpdate" 3 "BMSNotfnPushReq_3_PtcHeatReservrtionUpdate";
VAL_ 548 IBMSBattNoFuChargReq 0 "BMSBattNoFuChargReq_0_No_Request" 1 "BMSBattNoFuChargReq_1_Request";
VAL_ 548 IBMSPackSOCV 0 "BMSPackSOCV_0_Valid" 1 "BMSPackSOCV_1_Invalid";
VAL_ 548 IBMSPackSOCActual 254 "BMSPackSOCActual_254_Init" 255 "BMSPackSOCActual_255_Error";
VAL_ 548 IBMSPackSOCDspV 0 "BMSPackSOCDspV_0_Valid" 1 "BMSPackSOCDspV_1_Invalid";
VAL_ 548 IBMSPackSOCEV 0 "BMSPackSOCEV_0_valid" 1 "BMSPackSOCEV_1_invalid";
VAL_ 548 IBMSSysCoolResp 0 "BMSSysCoolResp_0_No_Request" 1 "BMSSysCoolResp_1_Active" 2 "BMSSysCoolResp_2_Not_allowed_for__Temperature_Low" 3 "BMSSysCoolResp_3_Not_allowed_for_DisChrg_Power_limit" 4 "BMSSysCoolResp_4_Not_allowed_for_ESS_Pump_Fault" 5 "BMSSysCoolResp_5_reserved1" 6 "BMSSysCoolResp_6_reserved2" 7 "BMSSysCoolResp_7_reserved3";
VAL_ 548 IBMSOnbdChrgngCmdReq 0 "BMSOnbdChrgngCmdReq_0_Default" 1 "BMSOnbdChrgngCmdReq_1_EnableCharging" 2 "BMSOnbdChrgngCmdReq_2_ShutDown" 3 "BMSOnbdChrgngCmdReq_3_Restart" 4 "BMSOnbdChrgngCmdReq_4_Pending" 5 "BMSOnbdChrgngCmdReq_5_ChargingRequest" 6 "BMSOnbdChrgngCmdReq_6_DischargingRequest" 7 "BMSOnbdChrgngCmdReq_7_HeatingRequest" 8 "BMSOnbdChrgngCmdReq_8_EnableDischarging";
VAL_ 548 IBMSCtrlS2Req 0 "BMSCtrlS2Req_0_Default" 1 "BMSCtrlS2Req_1_CloseRequest" 2 "BMSCtrlS2Req_2_OpenRequest";
VAL_ 548 IBMSDsChrgSpRsn 0 "BMSDsChrgSpRsn_0_Default" 1 "BMSDsChrgSpRsn_1_Reserved" 2 "BMSDsChrgSpRsn_2_Discharging_system_fault" 3 "BMSDsChrgSpRsn_3_NotPluginDisChargeGun" 4 "BMSDsChrgSpRsn_4_Overload" 5 "BMSDsChrgSpRsn_5_DischargingGunoverTemperature" 6 "BMSDsChrgSpRsn_6_Electronic_Lock_Failure" 7 "BMSDsChrgSpRsn_7_Others";
VAL_ 548 IBMSOnbdChrgngMd 0 "BMSOnbdChrgngMd_0_Invalid" 1 "BMSOnbdChrgngMd_1_CurrentControlMode" 2 "BMSOnbdChrgngMd_2_VoltageControlMode" 3 "BMSOnbdChrgngMd_3_PowerControlMode";
VAL_ 548 IBMSOnbdChrgrOtptVolReqV 0 "BMSOnbdChrgrOtptVolReqV_0_Valid" 1 "BMSOnbdChrgrOtptVolReqV_1_Invalid";
VAL_ 548 IVehCltcElecCsumpV 0 "VehCltcElecCsumpV_0_Valid" 1 "VehCltcElecCsumpV_1_NotValid";
VAL_ 548 IBMSAvlblEnrgV 0 "BMSAvlblEnrgV_0_Valid" 1 "BMSAvlblEnrgV_1_Invalid";
VAL_ 548 ICrntAvgElecCsumpV 0 "CrntAvgElecCsumpV_0_Valid" 1 "CrntAvgElecCsumpV_1_Invalid";
VAL_ 548 IHVBatElecEnrgAvgRateV 0 "HVBatElecEnrgAvgRateV_0_Valid" 1 "HVBatElecEnrgAvgRateV_1_Invalid";
VAL_ 548 IElecEnrgAvgRstPerfd 0 "ElecEnrgAvgRstPerfd_0_False" 1 "ElecEnrgAvgRstPerfd_1_True";
VAL_ 548 IElecCsumpPerKmV 0 "ElecCsumpPerKmV_0_Valid" 1 "ElecCsumpPerKmV_1_Invalid";
VAL_ 404 ITrEstdGearV 0 "TrEstdGearV_0_Valid" 1 "TrEstdGearV_1_Invalid";
VAL_ 404 IEPTRdyV 0 "EPTRdyV_0_Valid" 1 "EPTRdyV_1_Invalid";
VAL_ 404 IEPTRdy 0 "EPTRdy_0_NotReady" 1 "EPTRdy_1_Ready";
VAL_ 404 ITrShftLvrPosV 0 "TrShftLvrPosV_0_Valid" 1 "TrShftLvrPosV_1_Invalid";
VAL_ 404 ITrEstdGear 0 "TrEstdGear_0_NotSupported" 1 "TrEstdGear_1_FirstGear" 2 "TrEstdGear_2_SecondGear" 3 "TrEstdGear_3_ThirdGear" 4 "TrEstdGear_4_FourthGear" 5 "TrEstdGear_5_FifthGear" 6 "TrEstdGear_6_SixthGear" 7 "TrEstdGear_7_SeventhGear" 8 "TrEstdGear_8_EighthGear" 13 "TrEstdGear_13_NeutralGear" 14 "TrEstdGear_14_ReverseGear" 15 "TrEstdGear_15_ParkGear";
VAL_ 404 ITrShftLvrPos 0 "TrShftLvrPos_0_Between_Ranges" 1 "TrShftLvrPos_1_Park_Range" 2 "TrShftLvrPos_2_Reverse_Range" 3 "TrShftLvrPos_3_Neutral_Range" 4 "TrShftLvrPos_4_Forward_Range_A" 5 "TrShftLvrPos_5_Forward_Range_B" 6 "TrShftLvrPos_6_Forward_Range_C" 7 "TrShftLvrPos_7_Forward_Range_D" 8 "TrShftLvrPos_8_Forward_Range_E" 9 "TrShftLvrPos_9_Forward_Range_F" 10 "TrShftLvrPos_10_Forward_Range_G" 11 "TrShftLvrPos_11_Forward_Range_H" 12 "TrShftLvrPos_12_reserved" 13 "TrShftLvrPos_13_reserved" 14 "TrShftLvrPos_14_reserved" 15 "TrShftLvrPos_15_Lever_Position_Unknown";
VAL_ 404 ITrEngdStaV 0 "TrEngdStaV_0_Valid" 1 "TrEngdStaV_1_InValid";
VAL_ 404 ITrEngdSta 0 "TrEngdSta_0_Transmission_Not_Engaged" 1 "TrEngdSta_1_Transmissino_Engaged_in_Forward" 2 "TrEngdSta_2_Transmission_Engaged_in_Reverse" 3 "TrEngdSta_3_Operating_State_Not_Reached";
VAL_ 404 IEPTRunCrkTrmlSts 0 "EPTRunCrkTrmlSts_0_OFF" 1 "EPTRunCrkTrmlSts_1_ACC" 2 "EPTRunCrkTrmlSts_2_CRANK" 3 "EPTRunCrkTrmlSts_3_RUN";
VAL_ 404 IVMCLvlCtrlAdjActn 0 "VMCLvlCtrlAdjActn_0_Noaction" 1 "VMCLvlCtrlAdjActn_1_Actionduetoeasyload" 2 "VMCLvlCtrlAdjActn_2_Actionduetoeasypass" 3 "VMCLvlCtrlAdjActn_3_Actionduetoeasyentry" 4 "VMCLvlCtrlAdjActn_4_ActionduetoSpeeddependent" 5 "VMCLvlCtrlAdjActn_5_Actionduetoieasyentry" 6 "VMCLvlCtrlAdjActn_6_Actionduetodrivingmode" 7 "VMCLvlCtrlAdjActn_7_Actionduetoeasylevel" 8 "VMCLvlCtrlAdjActn_8_ActionduetoExtrePass" 9 "VMCLvlCtrlAdjActn_9_ActionduetoCloudBody" 10 "VMCLvlCtrlAdjActn_10_Reserved" 11 "VMCLvlCtrlAdjActn_11_Reserved" 12 "VMCLvlCtrlAdjActn_12_Reserved" 13 "VMCLvlCtrlAdjActn_13_Reserved" 14 "VMCLvlCtrlAdjActn_14_Reserved" 15 "VMCLvlCtrlAdjActn_15_LiftMdActivate";
VAL_ 404 ISecyAxleSts 0 "SecyAxleSts_0_Normal_Operation" 1 "SecyAxleSts_1_Temporary_Limited" 2 "SecyAxleSts_2_Temporarily_Inhibited" 3 "SecyAxleSts_3_Permanently_Failed";
VAL_ 180 IElecMotEmgcShutDwn 0 "ElecMotEmgcShutDwn_0_False" 1 "ElecMotEmgcShutDwn_1_True";
VAL_ 180 IEPTHVEmgcPwrOffReq 0 "EPTHVEmgcPwrOffReq_0_NoRequest" 1 "EPTHVEmgcPwrOffReq_1_request";
VAL_ 180 IEPTMainRelayDrvReq 0 "EPTMainRelayDrvReq_0_OpenRequest" 1 "EPTMainRelayDrvReq_1_CloseMainRelay" 2 "EPTMainRelayDrvReq_2_CloseFastChargeRelay" 3 "EPTMainRelayDrvReq_3_Reserved";
VAL_ 180 IEPTStCmdOn 0 "EPTStCmdOn_0_False" 1 "EPTStCmdOn_1_True";
VAL_ 180 IEPTAccelActuPosV 0 "EPTAccelActuPosV_0_Valid" 1 "EPTAccelActuPosV_1_Invalid";
VAL_ 180 IAutoChrgngMngmnt 0 "AutoChrgngMngmnt_0_Default" 1 "AutoChrgngMngmnt_1_Hold" 2 "AutoChrgngMngmnt_2_Stop_and_Enable" 3 "AutoChrgngMngmnt_3_Stop_and_Inhibited";
VAL_ 180 IEPTBrkPdlDscrtInptStsV 0 "EPTBrkPdlDscrtInptStsV_0_Valid" 1 "EPTBrkPdlDscrtInptStsV_1_Invalid";
VAL_ 180 IEPTBrkPdlDscrtInptSts 0 "EPTBrkPdlDscrtInptSts_0_BrakeNotApplied" 1 "EPTBrkPdlDscrtInptSts_1_BrakeApplied";
VAL_ 180 IRVSEPTRdy 0 "RVSEPTRdy_0_False" 1 "RVSEPTRdy_1_True";
VAL_ 180 IEPTCrkAbotd 0 "EPTCrkAbotd_0_False" 1 "EPTCrkAbotd_1_True";
VAL_ 180 IEPTHVDCDCMdReq 0 "EPTHVDCDCMdReq_0_Standby" 1 "EPTHVDCDCMdReq_1_Boost" 2 "EPTHVDCDCMdReq_2_Buck" 3 "EPTHVDCDCMdReq_3_DcLinkDischarge" 4 "EPTHVDCDCMdReq_4_Reserved" 5 "EPTHVDCDCMdReq_5_Reserved" 6 "EPTHVDCDCMdReq_6_Reserved" 7 "EPTHVDCDCMdReq_7_Reserved";
VAL_ 180 IEPTTrInptShaftSpdV_R 0 "EPTTrInptShaftSpdV_R_0_Valid" 1 "EPTTrInptShaftSpdV_R_1_Invalid";
VAL_ 180 IEPTTrInptShaftSpdV 0 "EPTTrInptShaftSpdV_0_Valid" 1 "EPTTrInptShaftSpdV_1_Invalid";
VAL_ 180 IEPTSecyAxleInptShaftSpdV 0 "EPTSecyAxleInptShaftSpdV_0_Valid" 1 "EPTSecyAxleInptShaftSpdV_1_Invalid";
SIG_GROUP_ 777 IRZCU_100ms_Group10 1 : ICstRgtnBrkLgtReq ICstRgtnBrkLgtReqV IEleccLckCtrlResp IFlbStrgFnStsResp IIMU_Signal_status IOfbdChrgRelaySts IOfbdChrgRelayStsV IOfbdChrgrNgtvSktTem IOfbdChrgrNgtvSktTemV IOfbdChrgrWkup IOfbdRelayWeldFlt IOnBdChrgrSktElecLckSta IOnBdChrgrSktElecLckStaV IOnBdChrgrSktPstvSnsrTem IOnBdChrgrSktPstvSnsrTemV IOnbdChrgrSktEleccLckEnable IRZCU_100ms_Group10_CRC IRZCU_100ms_Group10_RC IRZCU_100ms_Group10_Reserved1 IRZCU_100ms_Group10_Reserved2 IRZCU_100ms_Group10_Reserved3 IVCUCtrlS2Req;
SIG_GROUP_ 247 IRZCU_10ms_Group22 1 : IEPTTrOtptShaftTotMaxAvlblToq IEPTTrOtptShaftTotMaxAvlblToqV IEPTTrOtptShaftTotMinAvlblToq IEPTTrOtptShaftTotMinAvlblToqV IEPTTrOtptShaftTotToq IEPTTrOtptShaftTotToqV IRZCU_10ms_Group22_CRC IRZCU_10ms_Group22_RC IRZCU_10ms_Group22_Reserved1 IRZCU_10ms_Group22_Reserved2 IRZCU_10ms_Group22_Reserved3 IRZCU_10ms_Group22_Reserved4 IRZCU_10ms_Group22_Reserved5 IRZCU_10ms_Group22_Reserved6 IRZCU_10ms_Group22_Reserved7;
SIG_GROUP_ 225 IRZCU_10ms_Group23 1 : IAIPilotSysSaBrInh IAIPilotSysSaBrSts IAccelOvrd IAutodDrvngToqReqResp IPtACCToqReqResp IRZCU_10ms_Group23_CRC IRZCU_10ms_Group23_RC IRZCU_10ms_Group23_Reserved1 IRZCU_10ms_Group23_Reserved10 IRZCU_10ms_Group23_Reserved11 IRZCU_10ms_Group23_Reserved2 IRZCU_10ms_Group23_Reserved3 IRZCU_10ms_Group23_Reserved4 IRZCU_10ms_Group23_Reserved5 IRZCU_10ms_Group23_Reserved6 IRZCU_10ms_Group23_Reserved7 IRZCU_10ms_Group23_Reserved8 IRZCU_10ms_Group23_Reserved9;
SIG_GROUP_ 769 ESS_100ms_PDU19 1 : IBMSEmsnRltdMalfA IBMSOdoFctV IBMSCdstCtr IBMSOdoFct IBMSStdAvlblEnrg IBMSChrgTrgtStdAvlblEnrg IBMSDisTrgtStdAvlblEnrg IBMSStdAvlblEnrgV IBMSChrgTrgtStdAvlblEnrgV IBMSDisTrgtStdAvlblEnrgV;
SIG_GROUP_ 769 ESS_100ms_PDU25 2 : IESS_100ms_Group25_CRC IESS_100ms_Group25_RC IESS_100ms_Group25_Reserved1 IBMSPosPtIsltnRstc IBMSPosPtIsltnRstcV IBMSNegPtIsltnRstcV IBMSNegPtIsltnRstc IESS_100ms_Group25_Reserved2 IESS_100ms_Group25_Reserved3 IESS_100ms_Group25_Reserved4;
SIG_GROUP_ 769 ESS_100ms_PDU28 3 : IBMSStaOfHealthResi IBMSStaOfHealthCapct IBMSOnbdChrgSpRsn IBMSPackSOH IBMSFltLamp IHVBatShutOff;
SIG_GROUP_ 769 ESS_100ms_PDU54 4 : IHVBatSOCHiResV IHVBatSOCMin IHVBatSOCHiRes IHVBatSOCTrgtHiRes;
SIG_GROUP_ 769 ESS_100ms_PDU58 5 : IESS_100ms_Group58_CRC IESS_100ms_Group58_RC IBMSOfbdChrgrSktVolV IESS_100ms_Group58_Reserved1 IBMSOffBdChrgrPlugOn IESS_100ms_Group58_Reserved2 IESS_100ms_Group58_Reserved3 IBMSOfbdChrgrSktVol IESS_100ms_Group58_Reserved4 IBMSOffBdChrgrPlugOnV IBMSOfbdChrgrWkup IESS_100ms_Group58_Reserved5 IESS_100ms_Group58_Reserved6;
SIG_GROUP_ 548 BMS_ZONE_100ms_PDU16 1 : IVehElecRngDspCmd IElecDrvRngPerKwhV IVehElecRngV IElecDrvRngPerKwh IBMSOfbdChrgrMaxOtptVol IBMSOfbdChrgrOtptVol IBMSOfbdChrgrMaxOtptVolV IBMSOfbdChrgrOtptCrnt IBMSOfbdChrgrOtptVolV IBMSOfbdChrgngMd IBMSOfbdChrgrOtptCrnV IVehElecRng IBMSEnbPTC IHVOffMoSts;
SIG_GROUP_ 548 ESS_100ms_PDU15 2 : IBMSPTCHeatReqDspCmd IChrgngRmnngTimeV IBMSChrgrPlugCnctnIO IBMSCumuDschrgEnrgV IBMSCumuDschrgEnrg IChrgngRmnngTime IBMSEleccLckCtrlDspCmd IBMSPackSOCCorr IBMSPTCHeatResp IBMSNotfnPushReq IBMSBattNoFuChargReq;
SIG_GROUP_ 548 ESS_100ms_PDU26 3 : IBMSPackSOCE IBMSPackSOC IBMSPackSOCV IBMSPackSOCActual IBMSPackSOCDsp IBMSPackSOCDspV IBMSPackSOCEV IBMSSysCoolResp;
SIG_GROUP_ 548 ESS_100ms_PDU29 4 : IBMSOnbdChrgngCmdReq IBMSCtrlS2Req IBMSDsChrgSpRsn IBMSOnbdChrgrAltCrntLmt IBMSOnbdChrgrOtptCrntReq IBMSOnbdChrgngMd IBMSOnbdChrgrOtptVolReqV IBMSOnbdChrgrOtptVolReq;
SIG_GROUP_ 548 ESS_100ms_PDU34 5 : IVehCltcElecCsumpV IBMSAvlblEnrgV ICrntAvgElecCsumpV IVehCltcElecCsump ICrntAvgElecCsump IElecCsumpPerKm IHVBatElecEnrgAvgRate IHVBatElecEnrgAvgRateV IElecEnrgAvgRstPerfd IElecCsumpPerKmV IBMSAvlblEnrg;
SIG_GROUP_ 404 RZCU_20ms_PDU06 1 : IRZCU_20ms_Group06_CRC IRZCU_20ms_Group06_RC ITrEstdGearV IEPTRdyV IEPTRdy ITrShftLvrPosV ITrEstdGear ITrShftLvrPos IRZCU_20ms_Group06_Reserved1 ITrEngdStaV ITrEngdSta IRZCU_20ms_Group06_Reserved2 IRZCU_20ms_Group06_Reserved3 IRZCU_20ms_Group06_Reserved4 IRZCU_20ms_Group06_Reserved5;
SIG_GROUP_ 404 RZCU_20ms_PDU07 2 : IEPTRunCrkTrmlSts IEPTSimEnSpd IVMCLvlCtrlAdjActn ISecyAxleSts;
SIG_GROUP_ 180 RZCU_10ms_PDU01 1 : IRZCU_10ms_Group01_CRC IRZCU_10ms_Group01_RC IElecMotEmgcShutDwn IEPTHVEmgcPwrOffReq IEPTMainRelayDrvReq IEPTStCmdOn IEPTAccelActuPosV IAutoChrgngMngmnt IEPTBrkPdlDscrtInptStsV IEPTBrkPdlDscrtInptSts IRVSEPTRdy IEPTCrkAbotd IRZCU_10ms_Group01_Reserved1 IEPTHVDCDCMdReq IEPTAccelActuPos IEPTAccelEfctvPos IRZCU_10ms_Group01_Reserved2 IRZCU_10ms_Group01_Reserved3;
SIG_GROUP_ 180 RZCU_10ms_PDU02 2 : IRZCU_10ms_Group02_CRC IRZCU_10ms_Group02_RC IEPTTrInptShaftSpdV_R IRZCU_10ms_Group02_Reserved1 IEPTTrInptShaftSpdV IEPTSecyAxleInptShaftSpdV IEPTSecyAxleInptShaftSpd IEPTTrInptShaftSpd IEPTTrInptShaftSpd_R;
